VERSION "dbc-export 1 2025.20.8"

NS_ :

BS_:

BU_: ADSP APB APP APS APSB BB BMS CC CMP CMPD CP DAS DI DIF DIR DPB EPAS3P EPAS3S EPASTP EPASTS EPBL EPBR ESP GTW HVP IBST ICR IDB OCS1P ODIN PARK PCS PLG PM PMF PMR PTC RADC RCM RCM2 RCU SCCM SDCR TAS TCU TPMS TRCM UDS UI UIS UMC USM VC VCFRONT VCLEFT VCRIGHT VCSEC

BO_ 938 HVP_alertMatrix: 8 HVP
 SG_ HVP_matrixIndex M : 0|4@1+ (1,0) [0|15] "" Vector__XXX
 SG_ HVP_w001_WatchdogReset m0 : 4|1@1+ (1,0) [0|1] "" Vector__XXX
 SG_ HVP_w002_UnusedAlert2 m0 : 5|1@1+ (1,0) [0|1] "" Vector__XXX
 SG_ HVP_w003_SwAssertion m0 : 6|1@1+ (1,0) [0|1] "" Vector__XXX
 SG_ HVP_w004_CrashEvent m0 : 7|1@1+ (1,0) [0|1] "" Vector__XXX
 SG_ HVP_w005_OverDchgCurrentFault m0 : 8|1@1+ (1,0) [0|1] "" Vector__XXX
 SG_ HVP_w006_OverChargeCurrentFault m0 : 9|1@1+ (1,0) [0|1] "" Vector__XXX
 SG_ HVP_w007_OverCurrentFault m0 : 10|1@1+ (1,0) [0|1] "" Vector__XXX
 SG_ HVP_w008_OverTemperatureFault m0 : 11|1@1+ (1,0) [0|1] "" Vector__XXX
 SG_ HVP_w009_OverVoltageFault m0 : 12|1@1+ (1,0) [0|1] "" Vector__XXX
 SG_ HVP_w010_UnderVoltageFault m0 : 13|1@1+ (1,0) [0|1] "" Vector__XXX
 SG_ HVP_w011_PrimaryBmbMiaFault m0 : 14|1@1+ (1,0) [0|1] "" Vector__XXX
 SG_ HVP_w012_BmbDataIntegrityLoss m0 : 15|1@1+ (1,0) [0|1] "" Vector__XXX
 SG_ HVP_w013_BmbCommunication m0 : 16|1@1+ (1,0) [0|1] "" Vector__XXX
 SG_ HVP_w014_BmsMiaOnHviFault m0 : 17|1@1+ (1,0) [0|1] "" Vector__XXX
 SG_ HVP_w015_CpMiaFault m0 : 18|1@1+ (1,0) [0|1] "" Vector__XXX
 SG_ HVP_w016_PcsMiaFault m0 : 19|1@1+ (1,0) [0|1] "" Vector__XXX
 SG_ HVP_w017_GtwMiaFault m0 : 20|1@1+ (1,0) [0|1] "" Vector__XXX
 SG_ HVP_w018_powerCyclingPcs m0 : 21|1@1+ (1,0) [0|1] "" Vector__XXX
 SG_ HVP_w019_CpFault m0 : 22|1@1+ (1,0) [0|1] "" Vector__XXX
 SG_ HVP_w020_ShuntHwMiaFault m0 : 23|1@1+ (1,0) [0|1] "" Vector__XXX
 SG_ HVP_w021_PyroMiaFault m0 : 24|1@1+ (1,0) [0|1] "" Vector__XXX
 SG_ HVP_w022_PyroMiaWarning m0 : 25|1@1+ (1,0) [0|1] "" Vector__XXX
 SG_ HVP_w023_BmbResetRecovery m0 : 26|1@1+ (1,0) [0|1] "" Vector__XXX
 SG_ HVP_w024_Supply12vFault m0 : 27|1@1+ (1,0) [0|1] "" Vector__XXX
 SG_ HVP_w025_VerSupplyFault m0 : 28|1@1+ (1,0) [0|1] "" Vector__XXX
 SG_ HVP_w026_HvilFault m0 : 29|1@1+ (1,0) [0|1] "" Vector__XXX
 SG_ HVP_w027_BmsMiaOnHvsFault m0 : 30|1@1+ (1,0) [0|1] "" Vector__XXX
 SG_ HVP_w028_PackVoltMismatchFault m0 : 31|1@1+ (1,0) [0|1] "" Vector__XXX
 SG_ HVP_w029_EnsMiaFault m0 : 32|1@1+ (1,0) [0|1] "" Vector__XXX
 SG_ HVP_w030_PackPosCtrArcFault m0 : 33|1@1+ (1,0) [0|1] "" Vector__XXX
 SG_ HVP_w031_packNegCtrArcFault m0 : 34|1@1+ (1,0) [0|1] "" Vector__XXX
 SG_ HVP_w032_ShuntHwAndBmsMiaFault m0 : 35|1@1+ (1,0) [0|1] "" Vector__XXX
 SG_ HVP_w033_fcContHwFault m0 : 36|1@1+ (1,0) [0|1] "" Vector__XXX
 SG_ HVP_w034_cpMismatchFault m0 : 37|1@1+ (1,0) [0|1] "" Vector__XXX
 SG_ HVP_w035_packContHwFault m0 : 38|1@1+ (1,0) [0|1] "" Vector__XXX
 SG_ HVP_w036_pyroFuseBlown m0 : 39|1@1+ (1,0) [0|1] "" Vector__XXX
 SG_ HVP_w037_pyroFuseFailedToBlow m0 : 40|1@1+ (1,0) [0|1] "" Vector__XXX
 SG_ HVP_w038_CpilFault m0 : 41|1@1+ (1,0) [0|1] "" Vector__XXX
 SG_ HVP_w039_PackContactorFellOpen m0 : 42|1@1+ (1,0) [0|1] "" Vector__XXX
 SG_ HVP_w040_FcContactorFellOpen m0 : 43|1@1+ (1,0) [0|1] "" Vector__XXX
 SG_ HVP_w041_packCtrCloseBlocked m0 : 44|1@1+ (1,0) [0|1] "" Vector__XXX
 SG_ HVP_w042_fcCtrCloseBlocked m0 : 45|1@1+ (1,0) [0|1] "" Vector__XXX
 SG_ HVP_w043_packContactorForceOpen m0 : 46|1@1+ (1,0) [0|1] "" Vector__XXX
 SG_ HVP_w044_fcContactorForceOpen m0 : 47|1@1+ (1,0) [0|1] "" Vector__XXX
 SG_ HVP_w045_dcLinkOverVoltage m0 : 48|1@1+ (1,0) [0|1] "" Vector__XXX
 SG_ HVP_w046_shuntOverTemperature m0 : 49|1@1+ (1,0) [0|1] "" Vector__XXX
 SG_ HVP_w047_passivePyroDeploy m0 : 50|1@1+ (1,0) [0|1] "" Vector__XXX
 SG_ HVP_w048_swUnsupportedBmbAsicTyp m0 : 51|1@1+ (1,0) [0|1] "" Vector__XXX
 SG_ HVP_w049_packCtrCloseFailed m0 : 52|1@1+ (1,0) [0|1] "" Vector__XXX
 SG_ HVP_w050_fcCtrCloseFailed m0 : 53|1@1+ (1,0) [0|1] "" Vector__XXX
 SG_ HVP_w051_shuntThermistorMia m0 : 54|1@1+ (1,0) [0|1] "" Vector__XXX
 SG_ HVP_w052_BmbStatusRegError m0 : 55|1@1+ (1,0) [0|1] "" Vector__XXX
 SG_ HVP_w053_hvVoltageSensorRational m0 : 56|1@1+ (1,0) [0|1] "" Vector__XXX
 SG_ HVP_w054_swMissingConfigBlock m0 : 57|1@1+ (1,0) [0|1] "" Vector__XXX
 SG_ HVP_w055_swMissingPartNumber m0 : 58|1@1+ (1,0) [0|1] "" Vector__XXX
 SG_ HVP_w056_contactorFailedToOpen m0 : 59|1@1+ (1,0) [0|1] "" Vector__XXX
 SG_ HVP_w057_BatmanDiagnosticsError m0 : 60|1@1+ (1,0) [0|1] "" Vector__XXX
 SG_ HVP_w058_BmbVrefBad m0 : 61|1@1+ (1,0) [0|1] "" Vector__XXX
 SG_ HVP_w059_BmbVrefWarning m0 : 62|1@1+ (1,0) [0|1] "" Vector__XXX
 SG_ HVP_w060_StackVoltageSense m0 : 63|1@1+ (1,0) [0|1] "" Vector__XXX
 SG_ HVP_w061_ShuntCurrentRationality m1 : 4|1@1+ (1,0) [0|1] "" Vector__XXX
 SG_ HVP_w062_BmbOtpConfigError m1 : 5|1@1+ (1,0) [0|1] "" Vector__XXX
 SG_ HVP_w063_BmbBrickVRationality m1 : 6|1@1+ (1,0) [0|1] "" Vector__XXX
 SG_ HVP_w064_BmbAuxVRationality m1 : 7|1@1+ (1,0) [0|1] "" Vector__XXX
 SG_ HVP_w065_FastOpenVshDetected m1 : 8|1@1+ (1,0) [0|1] "" Vector__XXX
 SG_ HVP_w067_HvilCalNodeMismatch m1 : 10|1@1+ (1,0) [0|1] "" Vector__XXX
 SG_ HVP_w068_shuntUnexpectedThermist m1 : 11|1@1+ (1,0) [0|1] "" Vector__XXX

BO_ 522 HVP_contactorState: 6 HVP
 SG_ HVP_packContNegativeState : 0|3@1+ (1,0) [1|7] "" Vector__XXX
 SG_ HVP_packContPositiveState : 3|3@1+ (1,0) [1|7] "" Vector__XXX
 SG_ HVP_fcContPositiveAuxOpen : 6|1@1+ (1,0) [0|1] "" Vector__XXX
 SG_ HVP_fcContNegativeAuxOpen : 7|1@1+ (1,0) [0|1] "" Vector__XXX
 SG_ HVP_packContactorSetState : 8|4@1+ (1,0) [1|15] "" Vector__XXX
 SG_ HVP_fcContNegativeState : 12|3@1+ (1,0) [1|7] "" Vector__XXX
 SG_ HVP_fcContPositiveState : 16|3@1+ (1,0) [1|7] "" Vector__XXX
 SG_ HVP_fcContactorSetState : 19|4@1+ (1,0) [1|15] "" Vector__XXX
 SG_ HVP_fcCtrsRequestStatus : 24|2@1+ (1,0) [0|3] "" Vector__XXX
 SG_ HVP_fcCtrsResetRequestRequired : 26|1@1+ (1,0) [0|1] "" Vector__XXX
 SG_ HVP_fcCtrsOpenNowRequested : 27|1@1+ (1,0) [0|1] "" Vector__XXX
 SG_ HVP_fcCtrsOpenRequested : 28|1@1+ (1,0) [0|1] "" Vector__XXX
 SG_ HVP_fcCtrsClosingAllowed : 29|1@1+ (1,0) [0|1] "" Vector__XXX
 SG_ HVP_packCtrsRequestStatus : 30|2@1+ (1,0) [0|3] "" Vector__XXX
 SG_ HVP_packCtrsResetRequestRequired : 32|1@1+ (1,0) [0|1] "" Vector__XXX
 SG_ HVP_packCtrsOpenNowRequested : 33|1@1+ (1,0) [0|1] "" Vector__XXX
 SG_ HVP_packCtrsOpenRequested : 34|1@1+ (1,0) [0|1] "" Vector__XXX
 SG_ HVP_packCtrsClosingAllowed : 35|1@1+ (1,0) [0|1] "" Vector__XXX
 SG_ HVP_dcLinkAllowedToEnergize : 36|1@1+ (1,0) [0|1] "" Vector__XXX
 SG_ HVP_pyroTestInProgress : 37|1@1+ (1,0) [0|1] "" Vector__XXX
 SG_ HVP_hvilDiag : 40|4@1+ (1,0) [0|15] "" Vector__XXX
 SG_ HVP_fcLinkAllowedToEnergize : 44|2@1+ (1,0) [0|3] "" Vector__XXX

BO_ 1962 HVP_debugMessage: 8 HVP
 SG_ HVP_debugMessageMultiplexer M : 0|4@1+ (1,0) [0|15] "" Vector__XXX
 SG_ HVP_gpioPassivePyroDepl m0 : 4|1@1+ (1,0) [0|1] "" Vector__XXX
 SG_ HVP_gpioPyroIsoEn m0 : 5|1@1+ (1,0) [0|1] "" Vector__XXX
 SG_ HVP_gpioCpFaultIn m0 : 6|1@1+ (1,0) [0|1] "" Vector__XXX
 SG_ HVP_gpioPackContPowerEn m0 : 7|1@1+ (1,0) [0|1] "" Vector__XXX
 SG_ HVP_gpioHvCablesOk m0 : 8|1@1+ (1,0) [0|1] "" Vector__XXX
 SG_ HVP_gpioHvpSelfEnable m0 : 9|1@1+ (1,0) [0|1] "" Vector__XXX
 SG_ HVP_gpioLed m0 : 10|1@1+ (1,0) [0|1] "" Vector__XXX
 SG_ HVP_gpioCrashSignal m0 : 11|1@1+ (1,0) [0|1] "" Vector__XXX
 SG_ HVP_gpioShuntDataReady m0 : 12|1@1+ (1,0) [0|1] "" Vector__XXX
 SG_ HVP_gpioFcContPosAux m0 : 13|1@1+ (1,0) [0|1] "" Vector__XXX
 SG_ HVP_gpioFcContNegAux m0 : 14|1@1+ (1,0) [0|1] "" Vector__XXX
 SG_ HVP_gpioBmsEout m0 : 15|1@1+ (1,0) [0|1] "" Vector__XXX
 SG_ HVP_gpioCpFaultOut m0 : 16|1@1+ (1,0) [0|1] "" Vector__XXX
 SG_ HVP_gpioPyroPor m0 : 17|1@1+ (1,0) [0|1] "" Vector__XXX
 SG_ HVP_gpioShuntEn m0 : 18|1@1+ (1,0) [0|1] "" Vector__XXX
 SG_ HVP_gpioHvpVerEn m0 : 19|1@1+ (1,0) [0|1] "" Vector__XXX
 SG_ HVP_gpioFcContFlywheelEnable m0 : 20|1@1+ (1,0) [0|1] "" Vector__XXX
 SG_ HVP_gpioCpLatchEnable m0 : 21|1@1+ (1,0) [0|1] "" Vector__XXX
 SG_ HVP_gpioFcContPowerEnable m0 : 22|1@1+ (1,0) [0|1] "" Vector__XXX
 SG_ HVP_gpioHvilEnable m0 : 23|1@1+ (1,0) [0|1] "" Vector__XXX
 SG_ HVP_gpioPortSelSpiRdy m0 : 24|1@1+ (1,0) [0|1] "" Vector__XXX
 SG_ HVP_gpioPyroUnlock m0 : 25|1@1+ (1,0) [0|1] "" Vector__XXX
 SG_ HVP_hvp1v5Ref m0 : 26|12@1+ (0.1,0) [0|3] "V" Vector__XXX
 SG_ HVP_packCurrentMia m0 : 38|1@1+ (1,0) [0|1] "" Vector__XXX
 SG_ HVP_auxCurrentMia m0 : 39|1@1+ (1,0) [0|1] "" Vector__XXX
 SG_ HVP_currentSenseMia m0 : 40|1@1+ (1,0) [0|1] "" Vector__XXX
 SG_ HVP_shuntRefVoltageMismatch m0 : 41|1@1+ (1,0) [0|1] "" Vector__XXX
 SG_ HVP_shuntThermistorMissing m0 : 42|1@1+ (1,0) [0|1] "" Vector__XXX
 SG_ HVP_shuntThermistorExpected m0 : 43|1@1+ (1,0) [0|1] "" Vector__XXX
 SG_ HVP_shuntThermistorMia m0 : 44|1@1+ (1,0) [0|1] "" Vector__XXX
 SG_ HVP_shuntUnexpectedThermistor m0 : 45|1@1+ (1,0) [0|1] "" Vector__XXX
 SG_ HVP_shuntHwMia m0 : 46|1@1+ (1,0) [0|1] "" Vector__XXX
 SG_ HVP_shuntCurrentIrrational m0 : 47|1@1+ (1,0) [0|1] "" Vector__XXX
 SG_ HVP_shuntAsicTCompActive m0 : 48|1@1+ (1,0) [0|1] "" Vector__XXX
 SG_ HVP_ecuLogUploadRequest m0 : 49|2@1+ (1,0) [0|3] "" Vector__XXX
 SG_ HVP_packContVoltage m2 : 4|12@1+ (0.1,0) [0|30] "V" Vector__XXX
 SG_ HVP_packNegativeV m2 : 16|16@1- (0.1,0) [-550|550] "V" Vector__XXX
 SG_ HVP_packPositiveV m2 : 32|16@1- (0.1,0) [-550|550] "V" Vector__XXX
 SG_ HVP_pyroAnalog m2 : 48|12@1+ (0.1,0) [0|3] "V" Vector__XXX
 SG_ HVP_fcContCoilCurrent m4 : 4|12@1+ (0.1,0) [0|7.5] "A" Vector__XXX
 SG_ HVP_fcContVoltage m4 : 16|12@1+ (0.1,0) [0|30] "V" Vector__XXX
 SG_ HVP_hvilInVoltage m4 : 28|12@1+ (0.1,0) [0|30] "V" Vector__XXX
 SG_ HVP_hvilOutVoltage m4 : 40|12@1+ (0.1,0) [0|30] "V" Vector__XXX
 SG_ HVP_shuntGainInvalidCountDbg m4 : 56|8@1+ (1,0) [0|255] "counts" Vector__XXX
 SG_ HVP_fcLinkPositiveV m5 : 8|16@1- (0.1,0) [-550|550] "V" Vector__XXX
 SG_ HVP_packContCoilCurrent m5 : 24|12@1+ (0.1,0) [0|7.5] "A" Vector__XXX
 SG_ HVP_battery12V m5 : 36|12@1+ (0.1,0) [0|30] "V" Vector__XXX
 SG_ HVP_shuntRefVoltageDbg m5 : 48|16@1- (0.001,0) [-32.768|32.767] "V" Vector__XXX

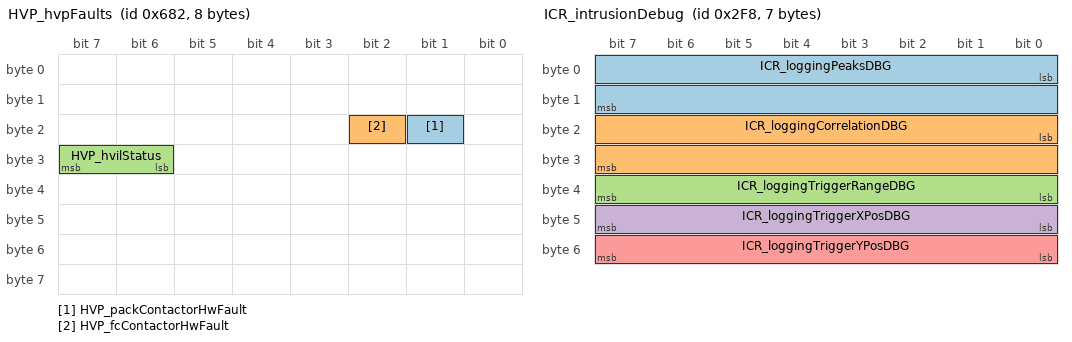
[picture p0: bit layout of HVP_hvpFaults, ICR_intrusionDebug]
BO_ 1666 HVP_hvpFaults: 8 HVP
 SG_ HVP_packContactorHwFault : 17|1@1+ (1,0) [0|1] "" Vector__XXX
 SG_ HVP_fcContactorHwFault : 18|1@1+ (1,0) [0|1] "" Vector__XXX
 SG_ HVP_hvilStatus : 30|2@1+ (1,0) [0|2] "" Vector__XXX

BO_ 1553 HVP_udsResponse: 8 HVP
 SG_ HVP_udsResponseData : 7|64@0+ (1,0) [0|1.84467440737e+19] "" Vector__XXX

BO_ 861 IBST_alertMatrix: 8 IBST
 SG_ IBST_matrixIndex M : 0|4@1+ (1,0) [0|15] "" Vector__XXX
 SG_ IBST_a001_microSupplyError m0 : 4|1@1+ (1,0) [0|1] "" Vector__XXX
 SG_ IBST_a002_HWBISTError m0 : 5|1@1+ (1,0) [0|1] "" Vector__XXX
 SG_ IBST_a003_RAMFault m0 : 6|1@1+ (1,0) [0|1] "" Vector__XXX
 SG_ IBST_a004_flashFault m0 : 7|1@1+ (1,0) [0|1] "" Vector__XXX
 SG_ IBST_a005_microSafetyFault m0 : 8|1@1+ (1,0) [0|1] "" Vector__XXX
 SG_ IBST_a006_microSafetyLogicFault m0 : 9|1@1+ (1,0) [0|1] "" Vector__XXX
 SG_ IBST_a007_RBCPUException m0 : 10|1@1+ (1,0) [0|1] "" Vector__XXX
 SG_ IBST_a008_stackOverUnderFlow m0 : 11|1@1+ (1,0) [0|1] "" Vector__XXX
 SG_ IBST_a009_systemErrorHook m0 : 12|1@1+ (1,0) [0|1] "" Vector__XXX
 SG_ IBST_a010_OSErrorHook m0 : 13|1@1+ (1,0) [0|1] "" Vector__XXX
 SG_ IBST_a011_systemTaskOverRun m0 : 14|1@1+ (1,0) [0|1] "" Vector__XXX
 SG_ IBST_a012_OSTaskSchemeError m0 : 15|1@1+ (1,0) [0|1] "" Vector__XXX
 SG_ IBST_a013_systemTaskJitter m0 : 16|1@1+ (1,0) [0|1] "" Vector__XXX
 SG_ IBST_a014_DMATransferError m0 : 17|1@1+ (1,0) [0|1] "" Vector__XXX
 SG_ IBST_a015_asicOscillatorError m0 : 18|1@1+ (1,0) [0|1] "" Vector__XXX
 SG_ IBST_a016_RBBLMShaftShiftError m0 : 19|1@1+ (1,0) [0|1] "" Vector__XXX
 SG_ IBST_a017_assertionFault m0 : 20|1@1+ (1,0) [0|1] "" Vector__XXX
 SG_ IBST_a018_unsupportedHW m0 : 21|1@1+ (1,0) [0|1] "" Vector__XXX
 SG_ IBST_a019_supplyASICInitFault m0 : 22|1@1+ (1,0) [0|1] "" Vector__XXX
 SG_ IBST_a020_VPREU5VOutOfRange m0 : 23|1@1+ (1,0) [0|1] "" Vector__XXX
 SG_ IBST_a021_IREFOutOfRange m0 : 24|1@1+ (1,0) [0|1] "" Vector__XXX
 SG_ IBST_a022_U5VTestFault m0 : 25|1@1+ (1,0) [0|1] "" Vector__XXX
 SG_ IBST_a023_U5VOutOfRange m0 : 26|1@1+ (1,0) [0|1] "" Vector__XXX
 SG_ IBST_a024_chargePumpFault m0 : 27|1@1+ (1,0) [0|1] "" Vector__XXX
 SG_ IBST_a025_ecuClockTestFault m0 : 28|1@1+ (1,0) [0|1] "" Vector__XXX
 SG_ IBST_a026_ecuBistCmdTestFault m0 : 29|1@1+ (1,0) [0|1] "" Vector__XXX
 SG_ IBST_a027_ecuFastWdTestFault m0 : 30|1@1+ (1,0) [0|1] "" Vector__XXX
 SG_ IBST_a028_ecuBistFaultCtrFault m0 : 31|1@1+ (1,0) [0|1] "" Vector__XXX
 SG_ IBST_a029_ecuErrpinCounterFault m0 : 32|1@1+ (1,0) [0|1] "" Vector__XXX
 SG_ IBST_a030_ecuEnableElLowFault m0 : 33|1@1+ (1,0) [0|1] "" Vector__XXX
 SG_ IBST_a031_decoupleBitTestFault m0 : 34|1@1+ (1,0) [0|1] "" Vector__XXX
 SG_ IBST_a032_ecuEnableElHighFault m0 : 35|1@1+ (1,0) [0|1] "" Vector__XXX
 SG_ IBST_a033_ecuWdStartuptestFault m0 : 36|1@1+ (1,0) [0|1] "" Vector__XXX
 SG_ IBST_a034_ecuEnableHyHighFault m0 : 37|1@1+ (1,0) [0|1] "" Vector__XXX
 SG_ IBST_a035_ecuEnableHyLowFault m0 : 38|1@1+ (1,0) [0|1] "" Vector__XXX
 SG_ IBST_a036_MRGPathTestFault m0 : 39|1@1+ (1,0) [0|1] "" Vector__XXX
 SG_ IBST_a037_ecuWdSContinuousError m0 : 40|1@1+ (1,0) [0|1] "" Vector__XXX
 SG_ IBST_a038_ecuEnContinuousError m0 : 41|1@1+ (1,0) [0|1] "" Vector__XXX
 SG_ IBST_a039_GTMRefFrequencyError m0 : 42|1@1+ (1,0) [0|1] "" Vector__XXX
 SG_ IBST_a040_GTMTbuMonError m0 : 43|1@1+ (1,0) [0|1] "" Vector__XXX
 SG_ IBST_a041_micAsicClkInError m0 : 44|1@1+ (1,0) [0|1] "" Vector__XXX
 SG_ IBST_a042_micAsicInitTestError m0 : 45|1@1+ (1,0) [0|1] "" Vector__XXX
 SG_ IBST_a043_micSpiTransferError m0 : 46|1@1+ (1,0) [0|1] "" Vector__XXX
 SG_ IBST_a044_NvMEepromWIP m0 : 47|1@1+ (1,0) [0|1] "" Vector__XXX
 SG_ IBST_a045_WdhAsicWdErrorCntStuck m0 : 48|1@1+ (1,0) [0|1] "" Vector__XXX
 SG_ IBST_a046_WdhAsicWdErrorCntLimit m0 : 49|1@1+ (1,0) [0|1] "" Vector__XXX
 SG_ IBST_a047_WdhAsicWdCmdMissing m0 : 50|1@1+ (1,0) [0|1] "" Vector__XXX
 SG_ IBST_a048_WdhSwBistConCnt m0 : 51|1@1+ (1,0) [0|1] "" Vector__XXX
 SG_ IBST_a049_WdhTaskMonConCnt m0 : 52|1@1+ (1,0) [0|1] "" Vector__XXX
 SG_ IBST_a050_VPreExternalFeeding m0 : 53|1@1+ (1,0) [0|1] "" Vector__XXX
 SG_ IBST_a051_ecuBandgap m0 : 54|1@1+ (1,0) [0|1] "" Vector__XXX
 SG_ IBST_a052_AdcPinTest m0 : 55|1@1+ (1,0) [0|1] "" Vector__XXX
 SG_ IBST_a053_AdcSelftestC5P m0 : 56|1@1+ (1,0) [0|1] "" Vector__XXX
 SG_ IBST_a054_AdcPeripheralFault m0 : 57|1@1+ (1,0) [0|1] "" Vector__XXX
 SG_ IBST_a055_UB6SupplyPathFault m0 : 58|1@1+ (1,0) [0|1] "" Vector__XXX
 SG_ IBST_a056_UB6PlausiMonFault m0 : 59|1@1+ (1,0) [0|1] "" Vector__XXX
 SG_ IBST_a057_microRegisterFault m0 : 60|1@1+ (1,0) [0|1] "" Vector__XXX
 SG_ IBST_a058_NvMWriteCycleExceed m0 : 61|1@1+ (1,0) [0|1] "" Vector__XXX
 SG_ IBST_a059_NvMEepromSize m0 : 62|1@1+ (1,0) [0|1] "" Vector__XXX
 SG_ IBST_a060_NvMMigrationFault m0 : 63|1@1+ (1,0) [0|1] "" Vector__XXX
 SG_ IBST_a061_AswSystemTimeOut m1 : 4|1@1+ (1,0) [0|1] "" Vector__XXX
 SG_ IBST_a062_MICB6TransferError m1 : 5|1@1+ (1,0) [0|1] "" Vector__XXX
 SG_ IBST_a063_tempSens2ShortToSupply m1 : 6|1@1+ (1,0) [0|1] "" Vector__XXX
 SG_ IBST_a064_tempSens1ShortToGround m1 : 7|1@1+ (1,0) [0|1] "" Vector__XXX
 SG_ IBST_a065_tempSens2ShortToGround m1 : 8|1@1+ (1,0) [0|1] "" Vector__XXX
 SG_ IBST_a066_tempSens1ShortToSupply m1 : 9|1@1+ (1,0) [0|1] "" Vector__XXX
 SG_ IBST_a067_tempSensImplausVoltage m1 : 10|1@1+ (1,0) [0|1] "" Vector__XXX
 SG_ IBST_a068_chargePumpUndervoltage m1 : 11|1@1+ (1,0) [0|1] "" Vector__XXX
 SG_ IBST_a069_greasingRoutineFault m1 : 12|1@1+ (1,0) [0|1] "" Vector__XXX
 SG_ IBST_a070_notShutDownNvMWrite m1 : 13|1@1+ (1,0) [0|1] "" Vector__XXX
 SG_ IBST_a071_notShutDownNvMRead m1 : 14|1@1+ (1,0) [0|1] "" Vector__XXX
 SG_ IBST_a072_notShutDownRight m1 : 15|1@1+ (1,0) [0|1] "" Vector__XXX
 SG_ IBST_a073_jumpInAdjustNvMRead m1 : 16|1@1+ (1,0) [0|1] "" Vector__XXX
 SG_ IBST_a074_FindIdleDataNvMWrite m1 : 17|1@1+ (1,0) [0|1] "" Vector__XXX
 SG_ IBST_a075_FindIdleRoutineFault m1 : 18|1@1+ (1,0) [0|1] "" Vector__XXX
 SG_ IBST_a076_masterCylLengthRead m1 : 19|1@1+ (1,0) [0|1] "" Vector__XXX
 SG_ IBST_a077_runOutMotorSaturated m1 : 20|1@1+ (1,0) [0|1] "" Vector__XXX
 SG_ IBST_a078_wearOffsetCompNVMRead m1 : 21|1@1+ (1,0) [0|1] "" Vector__XXX
 SG_ IBST_a079_motorTempHighLevel1 m1 : 22|1@1+ (1,0) [0|1] "" Vector__XXX
 SG_ IBST_a080_motorTempHighLevel2 m1 : 23|1@1+ (1,0) [0|1] "" Vector__XXX
 SG_ IBST_a081_travelDeviation m1 : 24|1@1+ (1,0) [0|1] "" Vector__XXX
 SG_ IBST_a082_motorSpeedDeviation m1 : 25|1@1+ (1,0) [0|1] "" Vector__XXX
 SG_ IBST_a083_spindlePositionTooHigh m1 : 26|1@1+ (1,0) [0|1] "" Vector__XXX
 SG_ IBST_a084_CANTransceiverHWFault m1 : 27|1@1+ (1,0) [0|1] "" Vector__XXX
 SG_ IBST_a085_supplyUndervoltageLvl3 m1 : 28|1@1+ (1,0) [0|1] "" Vector__XXX
 SG_ IBST_a086_supplyOvervoltageLvl3 m1 : 29|1@1+ (1,0) [0|1] "" Vector__XXX
 SG_ IBST_a087_rotorSinOutOfRangeLow m1 : 30|1@1+ (1,0) [0|1] "" Vector__XXX
 SG_ IBST_a088_rotorCosOutOfRangeLow m1 : 31|1@1+ (1,0) [0|1] "" Vector__XXX
 SG_ IBST_a089_rotorSinOutOfRangeHigh m1 : 32|1@1+ (1,0) [0|1] "" Vector__XXX
 SG_ IBST_a090_rotorCosOutOfRangeHigh m1 : 33|1@1+ (1,0) [0|1] "" Vector__XXX
 SG_ IBST_a091_SMMOneRequestsInit m1 : 34|1@1+ (1,0) [0|1] "" Vector__XXX
 SG_ IBST_a092_systemStartTimeOut m1 : 35|1@1+ (1,0) [0|1] "" Vector__XXX
 SG_ IBST_a093_UEXSOvertemperature m1 : 36|1@1+ (1,0) [0|1] "" Vector__XXX
 SG_ IBST_a094_XPASSEchoTimeDeviation m1 : 37|1@1+ (1,0) [0|1] "" Vector__XXX
 SG_ IBST_a095_XPASSTimeOut m1 : 38|1@1+ (1,0) [0|1] "" Vector__XXX
 SG_ IBST_a096_bridgeDriverMonError m1 : 39|1@1+ (1,0) [0|1] "" Vector__XXX
 SG_ IBST_a097_bridgeDriverError m1 : 40|1@1+ (1,0) [0|1] "" Vector__XXX
 SG_ IBST_a098_bridgeShortedPhase m1 : 41|1@1+ (1,0) [0|1] "" Vector__XXX
 SG_ IBST_a099_bridgeSwitchInitError m1 : 42|1@1+ (1,0) [0|1] "" Vector__XXX
 SG_ IBST_a100_current2OffsetHigh m1 : 43|1@1+ (1,0) [0|1] "" Vector__XXX
 SG_ IBST_a101_current2OffsetLow m1 : 44|1@1+ (1,0) [0|1] "" Vector__XXX
 SG_ IBST_a102_current1OffsetHigh m1 : 45|1@1+ (1,0) [0|1] "" Vector__XXX
 SG_ IBST_a103_current1OffsetLow m1 : 46|1@1+ (1,0) [0|1] "" Vector__XXX
 SG_ IBST_a104_bridgeDriverShort m1 : 47|1@1+ (1,0) [0|1] "" Vector__XXX
 SG_ IBST_a105_LiPSUndervoltage m1 : 48|1@1+ (1,0) [0|1] "" Vector__XXX
 SG_ IBST_a106_LiPS5VSupply m1 : 49|1@1+ (1,0) [0|1] "" Vector__XXX
 SG_ IBST_a107_LiPS2PwmLineHigh m1 : 50|1@1+ (1,0) [0|1] "" Vector__XXX
 SG_ IBST_a108_LiPS2PwmLineLow m1 : 51|1@1+ (1,0) [0|1] "" Vector__XXX
 SG_ IBST_a109_LiPS2PwmTransmission m1 : 52|1@1+ (1,0) [0|1] "" Vector__XXX
 SG_ IBST_a110_LiPS1SentLineHigh m1 : 53|1@1+ (1,0) [0|1] "" Vector__XXX
 SG_ IBST_a111_LiPS1SentLineLow m1 : 54|1@1+ (1,0) [0|1] "" Vector__XXX
 SG_ IBST_a112_LiPS1SentTransmission m1 : 55|1@1+ (1,0) [0|1] "" Vector__XXX
 SG_ IBST_a113_LiPS1SentSensor m1 : 56|1@1+ (1,0) [0|1] "" Vector__XXX
 SG_ IBST_a114_partyBusOff m1 : 57|1@1+ (1,0) [0|1] "" Vector__XXX
 SG_ IBST_a115_chassisBusOff m1 : 58|1@1+ (1,0) [0|1] "" Vector__XXX
 SG_ IBST_a116_supplyUndervoltageLvl2 m1 : 59|1@1+ (1,0) [0|1] "" Vector__XXX
 SG_ IBST_a117_supplyOvervoltageLvl2 m1 : 60|1@1+ (1,0) [0|1] "" Vector__XXX
 SG_ IBST_a118_RPSNvMReadFault m1 : 61|1@1+ (1,0) [0|1] "" Vector__XXX
 SG_ IBST_a119_RPSWrongCalibData m1 : 62|1@1+ (1,0) [0|1] "" Vector__XXX
 SG_ IBST_a120_RPSVectorRangeHigh m1 : 63|1@1+ (1,0) [0|1] "" Vector__XXX
 SG_ IBST_a121_RPSVectorRangeLow m2 : 4|1@1+ (1,0) [0|1] "" Vector__XXX
 SG_ IBST_a122_RPSVectorOscillating m2 : 5|1@1+ (1,0) [0|1] "" Vector__XXX
 SG_ IBST_a123_bridgeDriverUnavail m2 : 6|1@1+ (1,0) [0|1] "" Vector__XXX
 SG_ IBST_a124_OBDCurrent1OORHigh m2 : 7|1@1+ (1,0) [0|1] "" Vector__XXX
 SG_ IBST_a125_OBDCurrent2OORHigh m2 : 8|1@1+ (1,0) [0|1] "" Vector__XXX
 SG_ IBST_a126_OBDCurrent1OORLow m2 : 9|1@1+ (1,0) [0|1] "" Vector__XXX
 SG_ IBST_a127_OBDCurrent2OORLow m2 : 10|1@1+ (1,0) [0|1] "" Vector__XXX
 SG_ IBST_a128_BLMMuxerTimeoutError m2 : 11|1@1+ (1,0) [0|1] "" Vector__XXX
 SG_ IBST_a129_loadDumpOnFSLTest m2 : 12|1@1+ (1,0) [0|1] "" Vector__XXX
 SG_ IBST_a130_DTSFunctionalRangeLow m2 : 13|1@1+ (1,0) [0|1] "" Vector__XXX
 SG_ IBST_a131_DTSFunctionalRangeHigh m2 : 14|1@1+ (1,0) [0|1] "" Vector__XXX
 SG_ IBST_a132_DTSPlausiCheck1vs2 m2 : 15|1@1+ (1,0) [0|1] "" Vector__XXX
 SG_ IBST_a133_DTSOffsetTooLow m2 : 16|1@1+ (1,0) [0|1] "" Vector__XXX
 SG_ IBST_a134_DTSOffsetTooHigh m2 : 17|1@1+ (1,0) [0|1] "" Vector__XXX
 SG_ IBST_a135_ESPparty1DLC m2 : 18|1@1+ (1,0) [0|1] "" Vector__XXX
 SG_ IBST_a136_ESPparty1Timeout m2 : 19|1@1+ (1,0) [0|1] "" Vector__XXX
 SG_ IBST_a137_ESPparty1Checksum m2 : 20|1@1+ (1,0) [0|1] "" Vector__XXX
 SG_ IBST_a138_ESPparty1Counter m2 : 21|1@1+ (1,0) [0|1] "" Vector__XXX
 SG_ IBST_a139_ESPparty2DLC m2 : 22|1@1+ (1,0) [0|1] "" Vector__XXX
 SG_ IBST_a140_ESPparty2Timeout m2 : 23|1@1+ (1,0) [0|1] "" Vector__XXX
 SG_ IBST_a141_ESPparty2Checksum m2 : 24|1@1+ (1,0) [0|1] "" Vector__XXX
 SG_ IBST_a142_ESPparty2Counter m2 : 25|1@1+ (1,0) [0|1] "" Vector__XXX
 SG_ IBST_a143_ESPparty3DLC m2 : 26|1@1+ (1,0) [0|1] "" Vector__XXX
 SG_ IBST_a144_ESPparty3Timeout m2 : 27|1@1+ (1,0) [0|1] "" Vector__XXX
 SG_ IBST_a145_ESPparty3Checksum m2 : 28|1@1+ (1,0) [0|1] "" Vector__XXX
 SG_ IBST_a146_ESPparty3Counter m2 : 29|1@1+ (1,0) [0|1] "" Vector__XXX
 SG_ IBST_a147_PSCMotorSizeReadFault m2 : 30|1@1+ (1,0) [0|1] "" Vector__XXX
 SG_ IBST_a148_MLIGainMechReadFault m2 : 31|1@1+ (1,0) [0|1] "" Vector__XXX
 SG_ IBST_a149_MLITMCAreaReadFault m2 : 32|1@1+ (1,0) [0|1] "" Vector__XXX
 SG_ IBST_a150_motorTestFault m2 : 33|1@1+ (1,0) [0|1] "" Vector__XXX
 SG_ IBST_a151_PSCGearRatioReadFault m2 : 34|1@1+ (1,0) [0|1] "" Vector__XXX
 SG_ IBST_a152_PSCVoltageImplausible m2 : 35|1@1+ (1,0) [0|1] "" Vector__XXX
 SG_ IBST_a153_unused m2 : 36|1@1+ (1,0) [0|1] "" Vector__XXX
 SG_ IBST_a154_unused m2 : 37|1@1+ (1,0) [0|1] "" Vector__XXX
 SG_ IBST_a155_supplyUndervoltageLvl1 m2 : 38|1@1+ (1,0) [0|1] "" Vector__XXX
 SG_ IBST_a156_supplyOvervoltageLvl1 m2 : 39|1@1+ (1,0) [0|1] "" Vector__XXX
 SG_ IBST_a157_masterCylPressInvalid m2 : 40|1@1+ (1,0) [0|1] "" Vector__XXX
 SG_ IBST_a158_DTSOffsHighSuspicious m2 : 41|1@1+ (1,0) [0|1] "" Vector__XXX
 SG_ IBST_a159_FindIdleNvMReadError m2 : 42|1@1+ (1,0) [0|1] "" Vector__XXX
 SG_ IBST_a160_DTSIDTimeOut m2 : 43|1@1+ (1,0) [0|1] "" Vector__XXX
 SG_ IBST_a161_powerPackMismatch m2 : 44|1@1+ (1,0) [0|1] "" Vector__XXX
 SG_ IBST_a162_idlePosNotDetected m2 : 45|1@1+ (1,0) [0|1] "" Vector__XXX
 SG_ IBST_a163_ESPpEstMaxInvalid m2 : 46|1@1+ (1,0) [0|1] "" Vector__XXX
 SG_ IBST_a164_ESPVehicleSpeedInvalid m2 : 47|1@1+ (1,0) [0|1] "" Vector__XXX
 SG_ IBST_a165_ESPpForceBlendInvalid m2 : 48|1@1+ (1,0) [0|1] "" Vector__XXX
 SG_ IBST_a166_ESPpMcVirtualInvalid m2 : 49|1@1+ (1,0) [0|1] "" Vector__XXX
 SG_ IBST_a167_ESPqTargetExterInvalid m2 : 50|1@1+ (1,0) [0|1] "" Vector__XXX
 SG_ IBST_a168_CANOvervoltage m2 : 51|1@1+ (1,0) [0|1] "" Vector__XXX
 SG_ IBST_a169_CANUndervoltage m2 : 52|1@1+ (1,0) [0|1] "" Vector__XXX
 SG_ IBST_a170_LVPowerStateTimeout m2 : 53|1@1+ (1,0) [0|1] "" Vector__XXX
 SG_ IBST_a171_LVPowerStateChecksum m2 : 54|1@1+ (1,0) [0|1] "" Vector__XXX
 SG_ IBST_a172_LVPowerStateDLC m2 : 55|1@1+ (1,0) [0|1] "" Vector__XXX
 SG_ IBST_a173_LVPowerStateCounter m2 : 56|1@1+ (1,0) [0|1] "" Vector__XXX
 SG_ IBST_a174_LVOffStateInvalid m2 : 57|1@1+ (1,0) [0|1] "" Vector__XXX
 SG_ IBST_a175_LVGoingDownInvalid m2 : 58|1@1+ (1,0) [0|1] "" Vector__XXX
 SG_ IBST_a176_blockedPedalDetected m2 : 59|1@1+ (1,0) [0|1] "" Vector__XXX
 SG_ IBST_a177_EPBLsystemStatusMIA m2 : 60|1@1+ (1,0) [0|1] "" Vector__XXX
 SG_ IBST_a178_EPBRsystemStatusMIA m2 : 61|1@1+ (1,0) [0|1] "" Vector__XXX
 SG_ IBST_a179_VCLEFTepbmStatusMIA m2 : 62|1@1+ (1,0) [0|1] "" Vector__XXX
 SG_ IBST_a180_VCRIGHTepbmStatusMIA m2 : 63|1@1+ (1,0) [0|1] "" Vector__XXX
 SG_ IBST_a181_DIchassisControlDLC m3 : 4|1@1+ (1,0) [0|1] "" Vector__XXX
 SG_ IBST_a182_DIchassisControlTimeou m3 : 5|1@1+ (1,0) [0|1] "" Vector__XXX
 SG_ IBST_a183_DIchassisControlChecks m3 : 6|1@1+ (1,0) [0|1] "" Vector__XXX
 SG_ IBST_a184_DIchassisControlCounte m3 : 7|1@1+ (1,0) [0|1] "" Vector__XXX
 SG_ IBST_a185_rightBusOff m3 : 8|1@1+ (1,0) [0|1] "" Vector__XXX
 SG_ IBST_a186_rightBusPassive m3 : 9|1@1+ (1,0) [0|1] "" Vector__XXX
 SG_ IBST_a187_brakeBusOff m3 : 10|1@1+ (1,0) [0|1] "" Vector__XXX
 SG_ IBST_a188_brakeBusPassive m3 : 11|1@1+ (1,0) [0|1] "" Vector__XXX
 SG_ IBST_a189_rightVCLVPowerStateTim m3 : 12|1@1+ (1,0) [0|1] "" Vector__XXX
 SG_ IBST_a190_rightVCLVPowerStateDLC m3 : 13|1@1+ (1,0) [0|1] "" Vector__XXX
 SG_ IBST_a191_rightVCLVPowerStateChe m3 : 14|1@1+ (1,0) [0|1] "" Vector__XXX
 SG_ IBST_a192_rightVCLVPowerStateCou m3 : 15|1@1+ (1,0) [0|1] "" Vector__XXX
 SG_ IBST_a193_leftVCLVPowerStateTime m3 : 16|1@1+ (1,0) [0|1] "" Vector__XXX
 SG_ IBST_a194_leftVCLVPowerStateChec m3 : 17|1@1+ (1,0) [0|1] "" Vector__XXX
 SG_ IBST_a195_leftVCLVPowerStateDLC m3 : 18|1@1+ (1,0) [0|1] "" Vector__XXX
 SG_ IBST_a196_leftVCLVPowerStateCoun m3 : 19|1@1+ (1,0) [0|1] "" Vector__XXX
 SG_ IBST_a197_brakeLatencyReductionA m3 : 20|1@1+ (1,0) [0|1] "" Vector__XXX
 SG_ IBST_a198_aesActive m3 : 21|1@1+ (1,0) [0|1] "" Vector__XXX
 SG_ IBST_a199_undefinedAlertDetected m3 : 22|1@1+ (1,0) [0|1] "" Vector__XXX
 SG_ IBST_a200_aesFault m3 : 23|1@1+ (1,0) [0|1] "" Vector__XXX
 SG_ IBST_a201_EGGREAR1wheelSpeedsRea m3 : 24|1@1+ (1,0) [0|1] "" Vector__XXX
 SG_ IBST_a202_EGGREAR1wheelSpeedsRea m3 : 25|1@1+ (1,0) [0|1] "" Vector__XXX
 SG_ IBST_a203_EGGREAR1wheelSpeedsRea m3 : 26|1@1+ (1,0) [0|1] "" Vector__XXX
 SG_ IBST_a204_EGGREAR1wheelSpeedsRea m3 : 27|1@1+ (1,0) [0|1] "" Vector__XXX
 SG_ IBST_a205_EGGRIGHT1wheelSpeedsFr m3 : 28|1@1+ (1,0) [0|1] "" Vector__XXX
 SG_ IBST_a206_EGGRIGHT1wheelSpeedsFr m3 : 29|1@1+ (1,0) [0|1] "" Vector__XXX
 SG_ IBST_a207_EGGRIGHT1wheelSpeedsFr m3 : 30|1@1+ (1,0) [0|1] "" Vector__XXX
 SG_ IBST_a208_EGGRIGHT1wheelSpeedsFr m3 : 31|1@1+ (1,0) [0|1] "" Vector__XXX
 SG_ IBST_a209_reducedBrakePowerActiv m3 : 32|1@1+ (1,0) [0|1] "" Vector__XXX
 SG_ IBST_a210_reducedBrakePowerNotAv m3 : 33|1@1+ (1,0) [0|1] "" Vector__XXX
 SG_ IBST_a211_DETReportError m3 : 34|1@1+ (1,0) [0|1] "" Vector__XXX
 SG_ IBST_a212_infoFailureWrongCUBASH m3 : 35|1@1+ (1,0) [0|1] "" Vector__XXX
 SG_ IBST_a213_PDURouterinitializatio m3 : 36|1@1+ (1,0) [0|1] "" Vector__XXX
 SG_ IBST_a214_LossOfPDUInstanceDetec m3 : 37|1@1+ (1,0) [0|1] "" Vector__XXX
 SG_ IBST_a215_UnsupportedSeriesHWDet m3 : 38|1@1+ (1,0) [0|1] "" Vector__XXX
 SG_ IBST_a216_AsicMalfunctionDetecte m3 : 39|1@1+ (1,0) [0|1] "" Vector__XXX
 SG_ IBST_a217_AsicTrimmingNotComplet m3 : 40|1@1+ (1,0) [0|1] "" Vector__XXX
 SG_ IBST_a218_uCSafetyNotificationGR m3 : 41|1@1+ (1,0) [0|1] "" Vector__XXX
 SG_ IBST_a219_uCSafetyNotification m3 : 42|1@1+ (1,0) [0|1] "" Vector__XXX
 SG_ IBST_a220_ASICOvercurrentOnGPIO2 m3 : 43|1@1+ (1,0) [0|1] "" Vector__XXX
 SG_ IBST_a221_ASICOvercurrentOnGPIO2 m3 : 44|1@1+ (1,0) [0|1] "" Vector__XXX
 SG_ IBST_a222_ASICOvercurrentOnGPIO5 m3 : 45|1@1+ (1,0) [0|1] "" Vector__XXX
 SG_ IBST_a223_ASICOvercurrentOnGPIO5 m3 : 46|1@1+ (1,0) [0|1] "" Vector__XXX
 SG_ IBST_a224_ASICOvercurrentOnGPIO5 m3 : 47|1@1+ (1,0) [0|1] "" Vector__XXX
 SG_ IBST_a225_ASICOvercurrentOnGPIO5 m3 : 48|1@1+ (1,0) [0|1] "" Vector__XXX
 SG_ IBST_a226_ASICOvercurrentOnWRHS m3 : 49|1@1+ (1,0) [0|1] "" Vector__XXX
 SG_ IBST_a227_wakeRequestMismatchDet m3 : 50|1@1+ (1,0) [0|1] "" Vector__XXX
 SG_ IBST_a228_BlockedPedalDetectedDu m3 : 51|1@1+ (1,0) [0|1] "" Vector__XXX
 SG_ IBST_a229_BlockedPedalDetected m3 : 52|1@1+ (1,0) [0|1] "" Vector__XXX
 SG_ IBST_a230_DTS2FunctionalRangeLow m3 : 53|1@1+ (1,0) [0|1] "" Vector__XXX
 SG_ IBST_a231_DTS2FunctionalRangeLow m3 : 54|1@1+ (1,0) [0|1] "" Vector__XXX
 SG_ IBST_a232_PostAssemblyRoutineFai m3 : 55|1@1+ (1,0) [0|1] "" Vector__XXX
 SG_ IBST_a233_ReferenceRunAbortByECU m3 : 56|1@1+ (1,0) [0|1] "" Vector__XXX
 SG_ IBST_a234_LiPSOutOfRangeHigh m3 : 57|1@1+ (1,0) [0|1] "" Vector__XXX
 SG_ IBST_a235_LiPSOutOfRangeLow m3 : 58|1@1+ (1,0) [0|1] "" Vector__XXX

BO_ 1629 IBST_udsResponse: 8 IBST
 SG_ IBST_udsResponseData : 7|64@0+ (1,0) [0|1.84467440737e+19] "" Vector__XXX

BO_ 1208 ICR_alertLog: 8 ICR
 SG_ ICR_alertID M : 0|8@1+ (1,0) [0|255] "" Vector__XXX
 SG_ ICR_alertState : 15|1@1+ (1,0) [0|1] "" Vector__XXX
 SG_ ICR_a001_watchdogTaskAppDPM m1 : 16|1@1+ (1,0) [0|1] "" Vector__XXX
 SG_ ICR_a001_watchdogTaskMMWControl m1 : 17|1@1+ (1,0) [0|1] "" Vector__XXX
 SG_ ICR_a001_watchdogTaskSentinelInt m1 : 18|1@1+ (1,0) [0|1] "" Vector__XXX
 SG_ ICR_a001_watchdogTaskSentinelMod m1 : 19|1@1+ (1,0) [0|1] "" Vector__XXX
 SG_ ICR_a001_watchdogTaskComTXRAD m1 : 20|1@1+ (1,0) [0|1] "" Vector__XXX
 SG_ ICR_a001_watchdogTaskComRX m1 : 21|1@1+ (1,0) [0|1] "" Vector__XXX
 SG_ ICR_a001_watchdogTaskComTXVEH m1 : 22|1@1+ (1,0) [0|1] "" Vector__XXX
 SG_ ICR_a001_watchdogTaskComUDS m1 : 23|1@1+ (1,0) [0|1] "" Vector__XXX
 SG_ ICR_a001_watchdogTaskCommonError m1 : 24|1@1+ (1,0) [0|1] "" Vector__XXX
 SG_ ICR_a001_watchdogTaskUARTLog m1 : 25|1@1+ (1,0) [0|1] "" Vector__XXX
 SG_ ICR_a001_watchdogTaskDataDump m1 : 26|1@1+ (1,0) [0|1] "" Vector__XXX
 SG_ ICR_a001_watchdogRTOSAppRun10MS m1 : 27|1@1+ (1,0) [0|1] "" Vector__XXX
 SG_ ICR_a001_watchdogRTOSAppRun1MS m1 : 28|1@1+ (1,0) [0|1] "" Vector__XXX
 SG_ ICR_a001_InternalWatchdog m1 : 29|1@1+ (1,0) [0|1] "" Vector__XXX
 SG_ ICR_a002_CPUUndervoltage m2 : 16|1@1+ (1,0) [0|1] "" Vector__XXX
 SG_ ICR_a002_PowerOnReset m2 : 17|1@1+ (1,0) [0|1] "" Vector__XXX
 SG_ ICR_a015_NVMMMemOverflow m15 : 16|1@1+ (1,0) [0|1] "" Vector__XXX
 SG_ ICR_a015_NVMMFilesystemError m15 : 17|1@1+ (1,0) [0|1] "" Vector__XXX
 SG_ ICR_a015_NVMMRecordIDError m15 : 18|1@1+ (1,0) [0|1] "" Vector__XXX
 SG_ ICR_a059_voltageDrop m59 : 16|12@1+ (0.005443676,0) [0|22.29185322] "V" Vector__XXX
 SG_ ICR_a059_resistanceEstimate m59 : 28|12@1+ (0.00244,0) [0|9.9918] "Ohms" Vector__XXX
 SG_ ICR_a059_current m59 : 40|12@1+ (0.05,0) [0|204.75] "A" Vector__XXX
 SG_ ICR_a063_switchChannel m63 : 16|8@1+ (1,0) [0|255] "" Vector__XXX
 SG_ ICR_a063_switchType m63 : 24|8@1+ (1,0) [0|255] "" Vector__XXX
 SG_ ICR_a063_ADCVoltage m63 : 32|8@1+ (0.025,0) [0|6.375] "V" Vector__XXX
 SG_ ICR_a063_disconnected m63 : 40|1@1+ (1,0) [0|1] "" Vector__XXX
 SG_ ICR_a063_indeterminate m63 : 41|1@1+ (1,0) [0|1] "" Vector__XXX
 SG_ ICR_a063_stuckActive m63 : 42|1@1+ (1,0) [0|1] "" Vector__XXX
 SG_ ICR_a063_faulted m63 : 43|1@1+ (1,0) [0|1] "" Vector__XXX
 SG_ ICR_a133_nearClutter m133 : 16|8@1- (0.2,0) [-25.6|25.4] "dB" Vector__XXX
 SG_ ICR_a133_farClutter m133 : 24|8@1- (0.2,0) [-25.6|25.4] "dB" Vector__XXX
 SG_ ICR_a137_nearClutter m137 : 16|8@1- (0.2,0) [-25.6|25.4] "dB" Vector__XXX
 SG_ ICR_a137_farClutter m137 : 24|8@1- (0.2,0) [-25.6|25.4] "dB" Vector__XXX
 SG_ ICR_a139_nearClutter m139 : 16|8@1- (0.2,0) [-25.6|25.4] "dB" Vector__XXX
 SG_ ICR_a139_farClutter m139 : 24|8@1- (0.2,0) [-25.6|25.4] "dB" Vector__XXX

BO_ 2026 ICR_alertMatrix: 8 ICR
 SG_ ICR_matrixIndex M : 0|4@1+ (1,0) [0|15] "" Vector__XXX
 SG_ ICR_a001_WatchdogReset m0 : 4|1@1+ (1,0) [0|1] "" Vector__XXX
 SG_ ICR_a002_PowerLossReset m0 : 5|1@1+ (1,0) [0|1] "" Vector__XXX
 SG_ ICR_a003_SWAssertion m0 : 6|1@1+ (1,0) [0|1] "" Vector__XXX
 SG_ ICR_a005_CANTXError m0 : 8|1@1+ (1,0) [0|1] "" Vector__XXX
 SG_ ICR_a006_CANTX_cyclicError m0 : 9|1@1+ (1,0) [0|1] "" Vector__XXX
 SG_ ICR_a012_CPUReset m0 : 15|1@1+ (1,0) [0|1] "" Vector__XXX
 SG_ ICR_a013_AlertManagerFault m0 : 16|1@1+ (1,0) [0|1] "" Vector__XXX
 SG_ ICR_a015_NVMMError m0 : 18|1@1+ (1,0) [0|1] "" Vector__XXX
 SG_ ICR_a016_NVMMRecordError m0 : 19|1@1+ (1,0) [0|1] "" Vector__XXX
 SG_ ICR_a021_TaskSchedulerError m0 : 24|1@1+ (1,0) [0|1] "" Vector__XXX
 SG_ ICR_a022_TaskInitError m0 : 25|1@1+ (1,0) [0|1] "" Vector__XXX
 SG_ ICR_a029_CoreDump m0 : 32|1@1+ (1,0) [0|1] "" Vector__XXX
 SG_ ICR_a030_ECULogUploadRequest m0 : 33|1@1+ (1,0) [0|1] "" Vector__XXX
 SG_ ICR_a031_UDSActive m0 : 34|1@1+ (1,0) [0|1] "" Vector__XXX
 SG_ ICR_a041_HighCPULoad m0 : 44|1@1+ (1,0) [0|1] "" Vector__XXX
 SG_ ICR_a042_HighStackUsage m0 : 45|1@1+ (1,0) [0|1] "" Vector__XXX
 SG_ ICR_a043_Task1msError m0 : 46|1@1+ (1,0) [0|1] "" Vector__XXX
 SG_ ICR_a044_Task10msError m0 : 47|1@1+ (1,0) [0|1] "" Vector__XXX
 SG_ ICR_a045_Task100msError m0 : 48|1@1+ (1,0) [0|1] "" Vector__XXX
 SG_ ICR_a046_Task1000msError m0 : 49|1@1+ (1,0) [0|1] "" Vector__XXX
 SG_ ICR_a058_inputRHighSyncDebug m0 : 61|1@1+ (1,0) [0|1] "" Vector__XXX
 SG_ ICR_a059_inputResistanceHigh m0 : 62|1@1+ (1,0) [0|1] "" Vector__XXX
 SG_ ICR_a060_engineeringBuild m0 : 63|1@1+ (1,0) [0|1] "" Vector__XXX
 SG_ ICR_a061_XCPConnected m1 : 4|1@1+ (1,0) [0|1] "" Vector__XXX
 SG_ ICR_a062_XCPWasConnected m1 : 5|1@1+ (1,0) [0|1] "" Vector__XXX
 SG_ ICR_a063_SwitchFault m1 : 6|1@1+ (1,0) [0|1] "" Vector__XXX
 SG_ ICR_a064_busSleepReqTimeout m1 : 7|1@1+ (1,0) [0|1] "" Vector__XXX
 SG_ ICR_a133_radarBlocked m2 : 16|1@1+ (1,0) [0|1] "" Vector__XXX
 SG_ ICR_a134_radarPgood m2 : 17|1@1+ (1,0) [0|1] "" Vector__XXX
 SG_ ICR_a135_radarTxBallBreak m2 : 18|1@1+ (1,0) [0|1] "" Vector__XXX
 SG_ ICR_a136_radarHighTemperature m2 : 19|1@1+ (1,0) [0|1] "" Vector__XXX
 SG_ ICR_a137_radarBlocked m2 : 20|1@1+ (1,0) [0|1] "" Vector__XXX
 SG_ ICR_a138_DriverSideMismatch m2 : 21|1@1+ (1,0) [0|1] "" Vector__XXX
 SG_ ICR_a139_AbnormalBlockageDetecte m2 : 22|1@1+ (1,0) [0|1] "" Vector__XXX
 SG_ ICR_a140_OccupancyExceptionEncou m2 : 23|1@1+ (1,0) [0|1] "" Vector__XXX
 SG_ ICR_a141_RequiresReplacement m2 : 24|1@1+ (1,0) [0|1] "" Vector__XXX
 SG_ ICR_a142_ModeOverrideActive m2 : 25|1@1+ (1,0) [0|1] "" Vector__XXX

BO_ 760 ICR_intrusionDebug: 7 ICR
 SG_ ICR_loggingPeaksDBG : 0|16@1+ (1,0) [0|65535] "" Vector__XXX
 SG_ ICR_loggingCorrelationDBG : 16|16@1- (0.390625,0) [-12800|12799.609375] "%" Vector__XXX
 SG_ ICR_loggingTriggerRangeDBG : 32|8@1- (0.04,0) [-5.12|5.08] "m" Vector__XXX
 SG_ ICR_loggingTriggerXPosDBG : 40|8@1- (0.04,0) [-5.12|5.08] "m" Vector__XXX
 SG_ ICR_loggingTriggerYPosDBG : 48|8@1- (0.04,0) [-5.12|5.08] "m" Vector__XXX

BO_ 2025 ICR_occupancy: 8 ICR
 SG_ ICR_occupancy1LRaw : 0|2@1+ (1,0) [0|2] "" Vector__XXX
 SG_ ICR_occupancy1RRaw : 2|2@1+ (1,0) [0|2] "" Vector__XXX
 SG_ ICR_occupancy1LVoteCnt : 4|6@1- (1,0) [-32|31] "" Vector__XXX
 SG_ ICR_occupancy1RVoteCnt : 10|6@1- (1,0) [-32|31] "" Vector__XXX
 SG_ ICR_userPresenceFilt : 16|2@1+ (1,0) [0|2] "" Vector__XXX
 SG_ ICR_userPresenceRaw : 19|2@1+ (1,0) [0|2] "" Vector__XXX
 SG_ ICR_occupancy1LFilt : 21|2@1+ (1,0) [0|2] "" Vector__XXX
 SG_ ICR_occupancy1RFilt : 23|2@1+ (1,0) [0|2] "" Vector__XXX
 SG_ ICR_occupancy2LFilt : 25|2@1+ (1,0) [0|2] "" Vector__XXX
 SG_ ICR_occupancy2CFilt : 27|2@1+ (1,0) [0|2] "" Vector__XXX
 SG_ ICR_occupancy2RFilt : 29|2@1+ (1,0) [0|2] "" Vector__XXX
 SG_ ICR_childPresenceFilt : 31|3@1+ (1,0) [1|7] "" Vector__XXX
 SG_ ICR_childPresenceRaw : 34|3@1+ (1,0) [1|7] "" Vector__XXX
 SG_ ICR_classification1LFilt : 37|3@1+ (1,0) [1|7] "" Vector__XXX
 SG_ ICR_classification1RqF : 40|1@1+ (1,0) [0|1] "" Vector__XXX
 SG_ ICR_occupancy1RFiltExp : 41|2@1+ (1,0) [0|2] "" Vector__XXX
 SG_ ICR_occupancyCounter : 52|4@1+ (1,0) [0|15] "" Vector__XXX
 SG_ ICR_occupancyChecksum : 56|8@1+ (1,0) [0|255] "" Vector__XXX

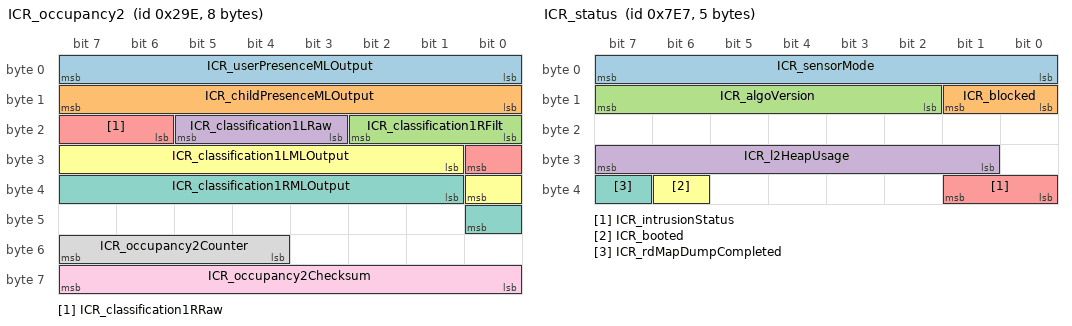
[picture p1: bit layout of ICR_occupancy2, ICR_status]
BO_ 670 ICR_occupancy2: 8 ICR
 SG_ ICR_userPresenceMLOutput : 0|8@1+ (0.004,0) [0|1.016] "points" Vector__XXX
 SG_ ICR_childPresenceMLOutput : 8|8@1+ (0.004,0) [0|1.016] "points" Vector__XXX
 SG_ ICR_classification1RFilt : 16|3@1+ (1,0) [1|7] "" Vector__XXX
 SG_ ICR_classification1LRaw : 19|3@1+ (1,0) [1|7] "" Vector__XXX
 SG_ ICR_classification1RRaw : 22|3@1+ (1,0) [1|7] "" Vector__XXX
 SG_ ICR_classification1LMLOutput : 25|8@1+ (0.004,0) [0|1.016] "points" Vector__XXX
 SG_ ICR_classification1RMLOutput : 33|8@1+ (0.004,0) [0|1.016] "points" Vector__XXX
 SG_ ICR_occupancy2Counter : 52|4@1+ (1,0) [0|15] "" Vector__XXX
 SG_ ICR_occupancy2Checksum : 56|8@1+ (1,0) [0|255] "" Vector__XXX

BO_ 2023 ICR_status: 5 ICR
 SG_ ICR_sensorMode : 0|8@1+ (1,0) [0|255] "" Vector__XXX
 SG_ ICR_blocked : 8|2@1+ (1,0) [1|3] "" Vector__XXX
 SG_ ICR_algoVersion : 10|6@1+ (1,0) [0|63] "" Vector__XXX
 SG_ ICR_l2HeapUsage : 25|7@1+ (1,0) [0|127] "PCT" Vector__XXX
 SG_ ICR_intrusionStatus : 32|2@1+ (1,0) [0|3] "" Vector__XXX
 SG_ ICR_booted : 38|1@1+ (1,0) [0|1] "" Vector__XXX
 SG_ ICR_rdMapDumpCompleted : 39|1@1+ (1,0) [0|1] "" Vector__XXX

BO_ 1624 ICR_udsResponse: 8 ICR
 SG_ ICR_udsResponseData : 7|64@0+ (1,0) [0|1.84467440737e+19] "" Vector__XXX

BO_ 1470 IDB_alertLog: 8 IDB
 SG_ IDB_alertID M : 0|8@1+ (1,0) [0|255] "" Vector__XXX
 SG_ IDB_alertState : 15|1@1+ (1,0) [0|1] "" Vector__XXX
 SG_ IDB_a014_wheelSpeedSensorFreq m14 : 16|1@1+ (1,0) [0|1] "" Vector__XXX
 SG_ IDB_a014_wheelSpeedSensorPhase m14 : 17|1@1+ (1,0) [0|1] "" Vector__XXX
 SG_ IDB_a014_wheelSpeedSensorMisinst m14 : 18|1@1+ (1,0) [0|1] "" Vector__XXX
 SG_ IDB_a014_wheelSpeedSensorWrongEx m14 : 19|1@1+ (1,0) [0|1] "" Vector__XXX
 SG_ IDB_a014_wheelSpeedSensorSpeedJu m14 : 20|1@1+ (1,0) [0|1] "" Vector__XXX
 SG_ IDB_a014_wheelSpeedSensorSp_0001 m14 : 21|1@1+ (1,0) [0|1] "" Vector__XXX
 SG_ IDB_a014_wheelSpeedSensorAirGap m14 : 22|1@1+ (1,0) [0|1] "" Vector__XXX
 SG_ IDB_a014_wheelSpeedSensorBIST m14 : 23|1@1+ (1,0) [0|1] "" Vector__XXX
 SG_ IDB_a014_wheelSpeedSensorLeakage m14 : 24|1@1+ (1,0) [0|1] "" Vector__XXX
 SG_ IDB_a014_wheelSpeedSensorOverTem m14 : 25|1@1+ (1,0) [0|1] "" Vector__XXX
 SG_ IDB_a014_wheelSpeedSensorSh_0001 m14 : 26|1@1+ (1,0) [0|1] "" Vector__XXX
 SG_ IDB_a014_wheelSpeedSensorShortTo m14 : 27|1@1+ (1,0) [0|1] "" Vector__XXX
 SG_ IDB_a014_wheelSpeedSensorOpen m14 : 28|1@1+ (1,0) [0|1] "" Vector__XXX
 SG_ IDB_a015_wheelSpeedSensorFreq m15 : 16|1@1+ (1,0) [0|1] "" Vector__XXX
 SG_ IDB_a015_wheelSpeedSensorPhase m15 : 17|1@1+ (1,0) [0|1] "" Vector__XXX
 SG_ IDB_a015_wheelSpeedSensorMisinst m15 : 18|1@1+ (1,0) [0|1] "" Vector__XXX
 SG_ IDB_a015_wheelSpeedSensorWrongEx m15 : 19|1@1+ (1,0) [0|1] "" Vector__XXX
 SG_ IDB_a015_wheelSpeedSensorSpeedJu m15 : 20|1@1+ (1,0) [0|1] "" Vector__XXX
 SG_ IDB_a015_wheelSpeedSensorSp_0001 m15 : 21|1@1+ (1,0) [0|1] "" Vector__XXX
 SG_ IDB_a015_wheelSpeedSensorAirGap m15 : 22|1@1+ (1,0) [0|1] "" Vector__XXX
 SG_ IDB_a015_wheelSpeedSensorBIST m15 : 23|1@1+ (1,0) [0|1] "" Vector__XXX
 SG_ IDB_a015_wheelSpeedSensorLeakage m15 : 24|1@1+ (1,0) [0|1] "" Vector__XXX
 SG_ IDB_a015_wheelSpeedSensorOverTem m15 : 25|1@1+ (1,0) [0|1] "" Vector__XXX
 SG_ IDB_a015_wheelSpeedSensorSh_0001 m15 : 26|1@1+ (1,0) [0|1] "" Vector__XXX
 SG_ IDB_a015_wheelSpeedSensorShortTo m15 : 27|1@1+ (1,0) [0|1] "" Vector__XXX
 SG_ IDB_a015_wheelSpeedSensorOpen m15 : 28|1@1+ (1,0) [0|1] "" Vector__XXX
 SG_ IDB_a016_wheelSpeedSensorFreq m16 : 16|1@1+ (1,0) [0|1] "" Vector__XXX
 SG_ IDB_a016_wheelSpeedSensorPhase m16 : 17|1@1+ (1,0) [0|1] "" Vector__XXX
 SG_ IDB_a016_wheelSpeedSensorMisinst m16 : 18|1@1+ (1,0) [0|1] "" Vector__XXX
 SG_ IDB_a016_wheelSpeedSensorWrongEx m16 : 19|1@1+ (1,0) [0|1] "" Vector__XXX
 SG_ IDB_a016_wheelSpeedSensorSpeedJu m16 : 20|1@1+ (1,0) [0|1] "" Vector__XXX
 SG_ IDB_a016_wheelSpeedSensorSp_0001 m16 : 21|1@1+ (1,0) [0|1] "" Vector__XXX
 SG_ IDB_a016_wheelSpeedSensorAirGap m16 : 22|1@1+ (1,0) [0|1] "" Vector__XXX
 SG_ IDB_a016_wheelSpeedSensorBIST m16 : 23|1@1+ (1,0) [0|1] "" Vector__XXX
 SG_ IDB_a016_wheelSpeedSensorLeakage m16 : 24|1@1+ (1,0) [0|1] "" Vector__XXX
 SG_ IDB_a016_wheelSpeedSensorOverTem m16 : 25|1@1+ (1,0) [0|1] "" Vector__XXX
 SG_ IDB_a016_wheelSpeedSensorSh_0001 m16 : 26|1@1+ (1,0) [0|1] "" Vector__XXX
 SG_ IDB_a016_wheelSpeedSensorShortTo m16 : 27|1@1+ (1,0) [0|1] "" Vector__XXX
 SG_ IDB_a016_wheelSpeedSensorOpen m16 : 28|1@1+ (1,0) [0|1] "" Vector__XXX
 SG_ IDB_a017_wheelSpeedSensorFreq m17 : 16|1@1+ (1,0) [0|1] "" Vector__XXX
 SG_ IDB_a017_wheelSpeedSensorPhase m17 : 17|1@1+ (1,0) [0|1] "" Vector__XXX
 SG_ IDB_a017_wheelSpeedSensorMisinst m17 : 18|1@1+ (1,0) [0|1] "" Vector__XXX
 SG_ IDB_a017_wheelSpeedSensorWrongEx m17 : 19|1@1+ (1,0) [0|1] "" Vector__XXX
 SG_ IDB_a017_wheelSpeedSensorSpeedJu m17 : 20|1@1+ (1,0) [0|1] "" Vector__XXX
 SG_ IDB_a017_wheelSpeedSensorSp_0001 m17 : 21|1@1+ (1,0) [0|1] "" Vector__XXX
 SG_ IDB_a017_wheelSpeedSensorAirGap m17 : 22|1@1+ (1,0) [0|1] "" Vector__XXX
 SG_ IDB_a017_wheelSpeedSensorBIST m17 : 23|1@1+ (1,0) [0|1] "" Vector__XXX
 SG_ IDB_a017_wheelSpeedSensorLeakage m17 : 24|1@1+ (1,0) [0|1] "" Vector__XXX
 SG_ IDB_a017_wheelSpeedSensorOverTem m17 : 25|1@1+ (1,0) [0|1] "" Vector__XXX
 SG_ IDB_a017_wheelSpeedSensorSh_0001 m17 : 26|1@1+ (1,0) [0|1] "" Vector__XXX
 SG_ IDB_a017_wheelSpeedSensorShortTo m17 : 27|1@1+ (1,0) [0|1] "" Vector__XXX
 SG_ IDB_a017_wheelSpeedSensorOpen m17 : 28|1@1+ (1,0) [0|1] "" Vector__XXX
 SG_ IDB_a020_canSignalValidity m20 : 16|1@1+ (1,0) [0|1] "" Vector__XXX
 SG_ IDB_a020_signalValueCrosscheck m20 : 17|1@1+ (1,0) [0|1] "" Vector__XXX
 SG_ IDB_a030_primaryExternalCircuitL m30 : 16|1@1+ (1,0) [0|1] "" Vector__XXX
 SG_ IDB_a030_secondaryExternalCircui m30 : 17|1@1+ (1,0) [0|1] "" Vector__XXX
 SG_ IDB_a030_primaryChamberInternalL m30 : 18|1@1+ (1,0) [0|1] "" Vector__XXX
 SG_ IDB_a030_syncModeInternalLeakage m30 : 19|1@1+ (1,0) [0|1] "" Vector__XXX
 SG_ IDB_a030_secondaryChamberInterna m30 : 20|1@1+ (1,0) [0|1] "" Vector__XXX
 SG_ IDB_a030_masterCylinderInternalL m30 : 21|1@1+ (1,0) [0|1] "" Vector__XXX
 SG_ IDB_a060_validityOnChassisBus m60 : 16|1@1+ (1,0) [0|1] "" Vector__XXX
 SG_ IDB_a060_validityOnPartyBus m60 : 17|1@1+ (1,0) [0|1] "" Vector__XXX
 SG_ IDB_a061_validityOnChassisBus m61 : 16|1@1+ (1,0) [0|1] "" Vector__XXX
 SG_ IDB_a061_validityOnPartyBus m61 : 17|1@1+ (1,0) [0|1] "" Vector__XXX
 SG_ IDB_a062_validityOnChassisBus m62 : 16|1@1+ (1,0) [0|1] "" Vector__XXX
 SG_ IDB_a062_validityOnPartyBus m62 : 17|1@1+ (1,0) [0|1] "" Vector__XXX
 SG_ IDB_a063_validityOnChassisBus m63 : 16|1@1+ (1,0) [0|1] "" Vector__XXX
 SG_ IDB_a063_validityOnPartyBus m63 : 17|1@1+ (1,0) [0|1] "" Vector__XXX
 SG_ IDB_a064_validityOnChassisBus m64 : 16|1@1+ (1,0) [0|1] "" Vector__XXX
 SG_ IDB_a064_validityOnPartyBus m64 : 17|1@1+ (1,0) [0|1] "" Vector__XXX
 SG_ IDB_a065_validityOnChassisBus m65 : 16|1@1+ (1,0) [0|1] "" Vector__XXX
 SG_ IDB_a065_validityOnPartyBus m65 : 17|1@1+ (1,0) [0|1] "" Vector__XXX
 SG_ IDB_a106_qualifierValidity m106 : 16|1@1+ (1,0) [0|1] "" Vector__XXX
 SG_ IDB_a106_signalNotAvailable m106 : 17|1@1+ (1,0) [0|1] "" Vector__XXX
 SG_ IDB_a107_qualifierValidity m107 : 16|1@1+ (1,0) [0|1] "" Vector__XXX
 SG_ IDB_a107_signalNotAvailable m107 : 17|1@1+ (1,0) [0|1] "" Vector__XXX
 SG_ IDB_a112_qualifierValidity m112 : 16|1@1+ (1,0) [0|1] "" Vector__XXX
 SG_ IDB_a112_signalNotAvailable m112 : 17|1@1+ (1,0) [0|1] "" Vector__XXX
 SG_ IDB_a113_qualifierValidity m113 : 16|1@1+ (1,0) [0|1] "" Vector__XXX
 SG_ IDB_a113_signalNotAvailable m113 : 17|1@1+ (1,0) [0|1] "" Vector__XXX
 SG_ IDB_a114_qualifierValidity m114 : 16|1@1+ (1,0) [0|1] "" Vector__XXX
 SG_ IDB_a114_signalNotAvailable m114 : 17|1@1+ (1,0) [0|1] "" Vector__XXX
 SG_ IDB_a126_PMebrCmdStateValidity m126 : 16|1@1+ (1,0) [0|1] "" Vector__XXX
 SG_ IDB_a126_PMstate2Validity m126 : 17|1@1+ (1,0) [0|1] "" Vector__XXX
 SG_ IDB_a126_PMstate2Missing m126 : 18|1@1+ (1,0) [0|1] "" Vector__XXX
 SG_ IDB_a126_DIchassisControlValidit m126 : 19|1@1+ (1,0) [0|1] "" Vector__XXX
 SG_ IDB_a126_DIchassisControlMissing m126 : 20|1@1+ (1,0) [0|1] "" Vector__XXX
 SG_ IDB_a126_DIrequestActiveValidity m126 : 21|1@1+ (1,0) [0|1] "" Vector__XXX
 SG_ IDB_a129_validityOnChassisBus m129 : 16|1@1+ (1,0) [0|1] "" Vector__XXX
 SG_ IDB_a129_validityOnPartyBus m129 : 17|1@1+ (1,0) [0|1] "" Vector__XXX
 SG_ IDB_a130_PMbrakePedalCmdQFValidi m130 : 16|1@1+ (1,0) [0|1] "" Vector__XXX
 SG_ IDB_a130_PMstate2Validity m130 : 17|1@1+ (1,0) [0|1] "" Vector__XXX
 SG_ IDB_a130_PMstate2Missing m130 : 18|1@1+ (1,0) [0|1] "" Vector__XXX
 SG_ IDB_a130_DIbrakeCommandValidity m130 : 19|1@1+ (1,0) [0|1] "" Vector__XXX
 SG_ IDB_a130_DIbrakeCommandMissing m130 : 20|1@1+ (1,0) [0|1] "" Vector__XXX
 SG_ IDB_a130_DIbrakeTorqueCommandFul m130 : 21|1@1+ (1,0) [0|1] "" Vector__XXX
 SG_ IDB_a130_DIbrakeTorqueComma_0001 m130 : 22|1@1+ (1,0) [0|1] "" Vector__XXX
 SG_ IDB_a132_validityOnChassisBus m132 : 16|1@1+ (1,0) [0|1] "" Vector__XXX
 SG_ IDB_a132_validityOnPartyBus m132 : 17|1@1+ (1,0) [0|1] "" Vector__XXX

BO_ 983 IDB_alertMatrix: 8 IDB
 SG_ IDB_matrixIndex M : 0|4@1+ (1,0) [0|15] "" Vector__XXX
 SG_ IDB_a001_mcuGenericFault m0 : 4|1@1+ (1,0) [0|1] "" Vector__XXX
 SG_ IDB_a002_supplyOvervoltage m0 : 5|1@1+ (1,0) [0|1] "" Vector__XXX
 SG_ IDB_a003_supplyHardOvervoltage m0 : 6|1@1+ (1,0) [0|1] "" Vector__XXX
 SG_ IDB_a004_supplyUndervoltage m0 : 7|1@1+ (1,0) [0|1] "" Vector__XXX
 SG_ IDB_a005_supplyMidUndervoltage m0 : 8|1@1+ (1,0) [0|1] "" Vector__XXX
 SG_ IDB_a006_supplyHardUndervoltage m0 : 9|1@1+ (1,0) [0|1] "" Vector__XXX
 SG_ IDB_a007_wakeLineOpen m0 : 10|1@1+ (1,0) [0|1] "" Vector__XXX
 SG_ IDB_a008_motorPowerOpen m0 : 11|1@1+ (1,0) [0|1] "" Vector__XXX
 SG_ IDB_a009_asicBoostFault m0 : 12|1@1+ (1,0) [0|1] "" Vector__XXX
 SG_ IDB_a010_asicGenericFault m0 : 13|1@1+ (1,0) [0|1] "" Vector__XXX
 SG_ IDB_a011_solenoidValveFault m0 : 14|1@1+ (1,0) [0|1] "" Vector__XXX
 SG_ IDB_a012_motorGenericFault m0 : 15|1@1+ (1,0) [0|1] "" Vector__XXX
 SG_ IDB_a013_motorPosSensorFault m0 : 16|1@1+ (1,0) [0|1] "" Vector__XXX
 SG_ IDB_a014_FrLWSSFault m0 : 17|1@1+ (1,0) [0|1] "" Vector__XXX
 SG_ IDB_a015_FrRWSSFault m0 : 18|1@1+ (1,0) [0|1] "" Vector__XXX
 SG_ IDB_a016_ReLWSSFault m0 : 19|1@1+ (1,0) [0|1] "" Vector__XXX
 SG_ IDB_a017_ReRWSSFault m0 : 20|1@1+ (1,0) [0|1] "" Vector__XXX
 SG_ IDB_a018_WSSGenericFault m0 : 21|1@1+ (1,0) [0|1] "" Vector__XXX
 SG_ IDB_a019_pedalSensorFault m0 : 22|1@1+ (1,0) [0|1] "" Vector__XXX
 SG_ IDB_a020_RCUpedalTravelMismatch m0 : 23|1@1+ (1,0) [0|1] "" Vector__XXX
 SG_ IDB_a021_pedalSensorNotCal m0 : 24|1@1+ (1,0) [0|1] "" Vector__XXX
 SG_ IDB_a022_brakeFluidLow m0 : 25|1@1+ (1,0) [0|1] "" Vector__XXX
 SG_ IDB_a023_steeringImplausible m0 : 26|1@1+ (1,0) [0|1] "" Vector__XXX
 SG_ IDB_a024_yawImplausible m0 : 27|1@1+ (1,0) [0|1] "" Vector__XXX
 SG_ IDB_a025_ayImplausible m0 : 28|1@1+ (1,0) [0|1] "" Vector__XXX
 SG_ IDB_a026_axImplausible m0 : 29|1@1+ (1,0) [0|1] "" Vector__XXX
 SG_ IDB_a027_circuitPresSensorFault m0 : 30|1@1+ (1,0) [0|1] "" Vector__XXX
 SG_ IDB_a028_simPresSensorFault m0 : 31|1@1+ (1,0) [0|1] "" Vector__XXX
 SG_ IDB_a029_pressureSensNotCal m0 : 32|1@1+ (1,0) [0|1] "" Vector__XXX
 SG_ IDB_a030_fluidLeakDetected m0 : 33|1@1+ (1,0) [0|1] "" Vector__XXX
 SG_ IDB_a031_solenoidValveStuck m0 : 34|1@1+ (1,0) [0|1] "" Vector__XXX
 SG_ IDB_a032_motorSoftOverheat m0 : 35|1@1+ (1,0) [0|1] "" Vector__XXX
 SG_ IDB_a033_motorHardOverheat m0 : 36|1@1+ (1,0) [0|1] "" Vector__XXX
 SG_ IDB_a034_motorPositionSetFault m0 : 37|1@1+ (1,0) [0|1] "" Vector__XXX
 SG_ IDB_a035_motorStuck m0 : 38|1@1+ (1,0) [0|1] "" Vector__XXX
 SG_ IDB_a036_partyBusOff m0 : 39|1@1+ (1,0) [0|1] "" Vector__XXX
 SG_ IDB_a037_chassisBusOff m0 : 40|1@1+ (1,0) [0|1] "" Vector__XXX
 SG_ IDB_a038_motorInitFault m0 : 41|1@1+ (1,0) [0|1] "" Vector__XXX
 SG_ IDB_a039_absActive m0 : 42|1@1+ (1,0) [0|1] "" Vector__XXX
 SG_ IDB_a040_ebdActive m0 : 43|1@1+ (1,0) [0|1] "" Vector__XXX
 SG_ IDB_a041_vdcActive m0 : 44|1@1+ (1,0) [0|1] "" Vector__XXX
 SG_ IDB_a042_btcActive m0 : 45|1@1+ (1,0) [0|1] "" Vector__XXX
 SG_ IDB_a043_DItorquePathActive m0 : 46|1@1+ (1,0) [0|1] "" Vector__XXX
 SG_ IDB_a044_standstillSkidDetected m0 : 47|1@1+ (1,0) [0|1] "" Vector__XXX
 SG_ IDB_a045_panicBrakeAssistActive m0 : 48|1@1+ (1,0) [0|1] "" Vector__XXX
 SG_ IDB_a046_fadeCompensationActive m0 : 49|1@1+ (1,0) [0|1] "" Vector__XXX
 SG_ IDB_a047_brakeDiscWipeActive m0 : 50|1@1+ (1,0) [0|1] "" Vector__XXX
 SG_ IDB_a048_scmActive m0 : 51|1@1+ (1,0) [0|1] "" Vector__XXX
 SG_ IDB_a049_cdpActive m0 : 52|1@1+ (1,0) [0|1] "" Vector__XXX
 SG_ IDB_a050_absFaulted m0 : 53|1@1+ (1,0) [0|1] "" Vector__XXX
 SG_ IDB_a051_ebdFaulted m0 : 54|1@1+ (1,0) [0|1] "" Vector__XXX
 SG_ IDB_a052_vdcFaulted m0 : 55|1@1+ (1,0) [0|1] "" Vector__XXX
 SG_ IDB_a053_DItorquePathFaulted m0 : 56|1@1+ (1,0) [0|1] "" Vector__XXX
 SG_ IDB_a054_skidDetectionFaulted m0 : 57|1@1+ (1,0) [0|1] "" Vector__XXX
 SG_ IDB_a055_panicBrakeAssistFaulted m0 : 58|1@1+ (1,0) [0|1] "" Vector__XXX
 SG_ IDB_a056_fadeCompensationFaulted m0 : 59|1@1+ (1,0) [0|1] "" Vector__XXX
 SG_ IDB_a057_bdwRequestInvalid m0 : 60|1@1+ (1,0) [0|1] "" Vector__XXX
 SG_ IDB_a058_scmFaulted m0 : 61|1@1+ (1,0) [0|1] "" Vector__XXX
 SG_ IDB_a059_cdpFaulted m0 : 62|1@1+ (1,0) [0|1] "" Vector__XXX
 SG_ IDB_a060_RCUstatusDLC m0 : 63|1@1+ (1,0) [0|1] "" Vector__XXX
 SG_ IDB_a061_RCUstatusChecksum m1 : 4|1@1+ (1,0) [0|1] "" Vector__XXX
 SG_ IDB_a062_RCUstatusCounter m1 : 5|1@1+ (1,0) [0|1] "" Vector__XXX
 SG_ IDB_a063_RCUactuationDLC m1 : 6|1@1+ (1,0) [0|1] "" Vector__XXX
 SG_ IDB_a064_RCUactuationChecksum m1 : 7|1@1+ (1,0) [0|1] "" Vector__XXX
 SG_ IDB_a065_RCUactuationCounter m1 : 8|1@1+ (1,0) [0|1] "" Vector__XXX
 SG_ IDB_a066_DIFtorqueDLC m1 : 9|1@1+ (1,0) [0|1] "" Vector__XXX
 SG_ IDB_a067_DIFtorqueChecksum m1 : 10|1@1+ (1,0) [0|1] "" Vector__XXX
 SG_ IDB_a068_DIFtorqueCounter m1 : 11|1@1+ (1,0) [0|1] "" Vector__XXX
 SG_ IDB_a069_DIchassisControlDLC m1 : 12|1@1+ (1,0) [0|1] "" Vector__XXX
 SG_ IDB_a070_DIchassisControlChecksu m1 : 13|1@1+ (1,0) [0|1] "" Vector__XXX
 SG_ IDB_a071_DIchassisControlCounter m1 : 14|1@1+ (1,0) [0|1] "" Vector__XXX
 SG_ IDB_a072_DIsystemStatusDLC m1 : 15|1@1+ (1,0) [0|1] "" Vector__XXX
 SG_ IDB_a073_DIsystemStatusChecksum m1 : 16|1@1+ (1,0) [0|1] "" Vector__XXX
 SG_ IDB_a074_DIsystemStatusCounter m1 : 17|1@1+ (1,0) [0|1] "" Vector__XXX
 SG_ IDB_a075_DIRtorqueDLC m1 : 18|1@1+ (1,0) [0|1] "" Vector__XXX
 SG_ IDB_a076_DIRtorqueChecksum m1 : 19|1@1+ (1,0) [0|1] "" Vector__XXX
 SG_ IDB_a077_DIRtorqueCounter m1 : 20|1@1+ (1,0) [0|1] "" Vector__XXX
 SG_ IDB_a078_DIvdcLeftDLC m1 : 21|1@1+ (1,0) [0|1] "" Vector__XXX
 SG_ IDB_a079_DIvdcLeftChecksum m1 : 22|1@1+ (1,0) [0|1] "" Vector__XXX
 SG_ IDB_a080_DIvdcLeftCounter m1 : 23|1@1+ (1,0) [0|1] "" Vector__XXX
 SG_ IDB_a081_DIvdcRightDLC m1 : 24|1@1+ (1,0) [0|1] "" Vector__XXX
 SG_ IDB_a082_DIvdcRightChecksum m1 : 25|1@1+ (1,0) [0|1] "" Vector__XXX
 SG_ IDB_a083_DIvdcRightCounter m1 : 26|1@1+ (1,0) [0|1] "" Vector__XXX
 SG_ IDB_a084_EPAS3PsysStatusDLC m1 : 27|1@1+ (1,0) [0|1] "" Vector__XXX
 SG_ IDB_a085_EPAS3PsysStatusChecksum m1 : 28|1@1+ (1,0) [0|1] "" Vector__XXX
 SG_ IDB_a086_EPAS3PsysStatusCounter m1 : 29|1@1+ (1,0) [0|1] "" Vector__XXX
 SG_ IDB_a087_PMstate2DLC m1 : 30|1@1+ (1,0) [0|1] "" Vector__XXX
 SG_ IDB_a088_PMstate2Checksum m1 : 31|1@1+ (1,0) [0|1] "" Vector__XXX
 SG_ IDB_a089_PMstate2Counter m1 : 32|1@1+ (1,0) [0|1] "" Vector__XXX
 SG_ IDB_a090_RCMinertial1DLC m1 : 33|1@1+ (1,0) [0|1] "" Vector__XXX
 SG_ IDB_a091_RCMinertial1Checksum m1 : 34|1@1+ (1,0) [0|1] "" Vector__XXX
 SG_ IDB_a092_RCMinertial1Counter m1 : 35|1@1+ (1,0) [0|1] "" Vector__XXX
 SG_ IDB_a093_RCMinertial2DLC m1 : 36|1@1+ (1,0) [0|1] "" Vector__XXX
 SG_ IDB_a094_RCMinertial2Checksum m1 : 37|1@1+ (1,0) [0|1] "" Vector__XXX
 SG_ IDB_a095_RCMinertial2Counter m1 : 38|1@1+ (1,0) [0|1] "" Vector__XXX
 SG_ IDB_a096_VCFRONTLVPowerStateDLC m1 : 39|1@1+ (1,0) [0|1] "" Vector__XXX
 SG_ IDB_a097_VCFRONTLVPwrStChecksum m1 : 40|1@1+ (1,0) [0|1] "" Vector__XXX
 SG_ IDB_a098_VCFRONTLVPwrStCounter m1 : 41|1@1+ (1,0) [0|1] "" Vector__XXX
 SG_ IDB_a099_RCMcollisionDLC m1 : 42|1@1+ (1,0) [0|1] "" Vector__XXX
 SG_ IDB_a100_RCMcollisionChecksum m1 : 43|1@1+ (1,0) [0|1] "" Vector__XXX
 SG_ IDB_a101_RCMcollisionCounter m1 : 44|1@1+ (1,0) [0|1] "" Vector__XXX
 SG_ IDB_a102_bdwRequestActiveInvalid m1 : 45|1@1+ (1,0) [0|1] "" Vector__XXX
 SG_ IDB_a103_DIfullTorquePathFaulted m1 : 46|1@1+ (1,0) [0|1] "" Vector__XXX
 SG_ IDB_a104_DIaccelPosInvalid m1 : 47|1@1+ (1,0) [0|1] "" Vector__XXX
 SG_ IDB_a105_DIgearInvalid m1 : 48|1@1+ (1,0) [0|1] "" Vector__XXX
 SG_ IDB_a106_DIFtorqueInvalid m1 : 49|1@1+ (1,0) [0|1] "" Vector__XXX
 SG_ IDB_a107_DIRtorqueInvalid m1 : 50|1@1+ (1,0) [0|1] "" Vector__XXX
 SG_ IDB_a108_EPBstatusDLC m1 : 51|1@1+ (1,0) [0|1] "" Vector__XXX
 SG_ IDB_a109_BDWsignalInvalid m1 : 52|1@1+ (1,0) [0|1] "" Vector__XXX
 SG_ IDB_a110_EPBstatusCounter m1 : 53|1@1+ (1,0) [0|1] "" Vector__XXX
 SG_ IDB_a111_EPBstatusChecksum m1 : 54|1@1+ (1,0) [0|1] "" Vector__XXX
 SG_ IDB_a112_yawRateInvalid m1 : 55|1@1+ (1,0) [0|1] "" Vector__XXX
 SG_ IDB_a113_latAccelInvalid m1 : 56|1@1+ (1,0) [0|1] "" Vector__XXX
 SG_ IDB_a114_longAccelInvalid m1 : 57|1@1+ (1,0) [0|1] "" Vector__XXX
 SG_ IDB_a115_VCFRONTespLvStInvalid m1 : 58|1@1+ (1,0) [0|1] "" Vector__XXX
 SG_ IDB_a116_VCFRONTsensorsDLC m1 : 59|1@1+ (1,0) [0|1] "" Vector__XXX
 SG_ IDB_a117_VCLEFTepbmStatusDLC m1 : 60|1@1+ (1,0) [0|1] "" Vector__XXX
 SG_ IDB_a118_VCLEFTepbmStatusCounter m1 : 61|1@1+ (1,0) [0|1] "" Vector__XXX
 SG_ IDB_a119_VCLEFTepbmStatusChecksu m1 : 62|1@1+ (1,0) [0|1] "" Vector__XXX
 SG_ IDB_a120_EPAS3Pinvalid m1 : 63|1@1+ (1,0) [0|1] "" Vector__XXX
 SG_ IDB_a121_dynoModeActive m2 : 4|1@1+ (1,0) [0|1] "" Vector__XXX
 SG_ IDB_a122_DIFtorqueCommandInvalid m2 : 5|1@1+ (1,0) [0|1] "" Vector__XXX
 SG_ IDB_a123_DIRtorqueCommandInvalid m2 : 6|1@1+ (1,0) [0|1] "" Vector__XXX
 SG_ IDB_a124_VCFRONTtempInvalid m2 : 7|1@1+ (1,0) [0|1] "" Vector__XXX
 SG_ IDB_a125_PMvdcCmdStateInvalid m2 : 8|1@1+ (1,0) [0|1] "" Vector__XXX
 SG_ IDB_a126_DItorqueRequestInvalid m2 : 9|1@1+ (1,0) [0|1] "" Vector__XXX
 SG_ IDB_a127_brakeFluidLevelInvalid m2 : 10|1@1+ (1,0) [0|1] "" Vector__XXX
 SG_ IDB_a128_reserved1 m2 : 11|1@1+ (1,0) [0|1] "" Vector__XXX
 SG_ IDB_a129_RCUinputRodStrokeInvali m2 : 12|1@1+ (1,0) [0|1] "" Vector__XXX
 SG_ IDB_a130_DIfullTorqueRequestInva m2 : 13|1@1+ (1,0) [0|1] "" Vector__XXX
 SG_ IDB_a131_DIfullTorquePathActive m2 : 14|1@1+ (1,0) [0|1] "" Vector__XXX
 SG_ IDB_a132_RCUinputRodStrokeQFInva m2 : 15|1@1+ (1,0) [0|1] "" Vector__XXX
 SG_ IDB_a133_DIbrakeCommandDLC m2 : 16|1@1+ (1,0) [0|1] "" Vector__XXX
 SG_ IDB_a134_DIbrakeCommandCounter m2 : 17|1@1+ (1,0) [0|1] "" Vector__XXX
 SG_ IDB_a135_DIbrakeCommandChecksum m2 : 18|1@1+ (1,0) [0|1] "" Vector__XXX
 SG_ IDB_a136_RCUptsCalMissing m2 : 19|1@1+ (1,0) [0|1] "" Vector__XXX
 SG_ IDB_a137_VCLEFTcdpRequestInvalid m2 : 20|1@1+ (1,0) [0|1] "" Vector__XXX
 SG_ IDB_a138_DIbrakeTorqueCommandAnd m2 : 21|1@1+ (1,0) [0|1] "" Vector__XXX
 SG_ IDB_a139_DIbrakeTorqueCommandFul m2 : 22|1@1+ (1,0) [0|1] "" Vector__XXX
 SG_ IDB_a140_PMbrakePedalCmdQFInvali m2 : 23|1@1+ (1,0) [0|1] "" Vector__XXX
 SG_ IDB_a141_DIbrakeTorqueCommandFul m2 : 24|1@1+ (1,0) [0|1] "" Vector__XXX
 SG_ IDB_a142_PMebrCmdStateInvalid m2 : 25|1@1+ (1,0) [0|1] "" Vector__XXX
 SG_ IDB_a143_factoryModeActive m2 : 26|1@1+ (1,0) [0|1] "" Vector__XXX
 SG_ IDB_a144_hydraulicPushthroughAct m2 : 27|1@1+ (1,0) [0|1] "" Vector__XXX

BO_ 1429 OCS1P_alertLog: 8 OCS1P
 SG_ OCS1P_alertID M : 0|8@1+ (1,0) [0|255] "" Vector__XXX
 SG_ OCS1P_alertState : 15|1@1+ (1,0) [0|1] "" Vector__XXX
 SG_ OCS1P_a121_sandwichFreq m121 : 16|32@1+ (1,0) [0|4294967295] "" Vector__XXX
 SG_ OCS1P_a122_sandwichFreq m122 : 16|32@1+ (1,0) [0|4294967295] "" Vector__XXX
 SG_ OCS1P_a123_sandwichFreq m123 : 16|32@1+ (1,0) [0|4294967295] "" Vector__XXX
 SG_ OCS1P_a124_cushionSelfFreq m124 : 16|32@1+ (1,0) [0|4294967295] "" Vector__XXX
 SG_ OCS1P_a125_cushionSelfFreq m125 : 16|32@1+ (1,0) [0|4294967295] "" Vector__XXX
 SG_ OCS1P_a126_cushionSelfFreq m126 : 16|32@1+ (1,0) [0|4294967295] "" Vector__XXX
 SG_ OCS1P_a127_seatbackSelfFreq m127 : 16|32@1+ (1,0) [0|4294967295] "" Vector__XXX
 SG_ OCS1P_a128_seatbackSelfFreq m128 : 16|32@1+ (1,0) [0|4294967295] "" Vector__XXX
 SG_ OCS1P_a129_seatbackSelfFreq m129 : 16|32@1+ (1,0) [0|4294967295] "" Vector__XXX
 SG_ OCS1P_a130_sandwichNoCalib m130 : 16|1@1+ (1,0) [0|1] "" Vector__XXX
 SG_ OCS1P_a131_cushionSelfNoCalib m131 : 16|1@1+ (1,0) [0|1] "" Vector__XXX
 SG_ OCS1P_a132_seatbackSelfNoCalib m132 : 16|1@1+ (1,0) [0|1] "" Vector__XXX
 SG_ OCS1P_a133_sandwichBadCalib m133 : 16|1@1+ (1,0) [0|1] "" Vector__XXX
 SG_ OCS1P_a134_uninitializedCalib m134 : 16|1@1+ (1,0) [0|1] "" Vector__XXX
 SG_ OCS1P_a135_tempNoCalib m135 : 16|1@1+ (1,0) [0|1] "" Vector__XXX
 SG_ OCS1P_a140_tempInvalidCalib m140 : 16|1@1+ (1,0) [0|1] "" Vector__XXX
 SG_ OCS1P_a141_humidityInvalidCalib m141 : 16|1@1+ (1,0) [0|1] "" Vector__XXX
 SG_ OCS1P_a142_tempHumidityInvalid m142 : 16|1@1+ (1,0) [0|1] "" Vector__XXX
 SG_ OCS1P_a143_mismatchPassAirbag m143 : 16|1@1+ (1,0) [0|1] "" Vector__XXX
 SG_ OCS1P_a144_mismatchCarRegion m144 : 16|1@1+ (1,0) [0|1] "" Vector__XXX

BO_ 767 OCS1P_alertMatrix: 8 OCS1P
 SG_ OCS1P_matrixIndex M : 0|4@1+ (1,0) [0|15] "" Vector__XXX
 SG_ OCS1P_w015_NVMMAlert m0 : 18|1@1+ (1,0) [0|1] "" Vector__XXX
 SG_ OCS1P_w121_sandwichOpen m2 : 4|1@1+ (1,0) [0|1] "" Vector__XXX
 SG_ OCS1P_w122_sandwichLow m2 : 5|1@1+ (1,0) [0|1] "" Vector__XXX
 SG_ OCS1P_w123_sandwichShort m2 : 6|1@1+ (1,0) [0|1] "" Vector__XXX
 SG_ OCS1P_w124_cushionSelfOpen m2 : 7|1@1+ (1,0) [0|1] "" Vector__XXX
 SG_ OCS1P_w125_cushionSelfLow m2 : 8|1@1+ (1,0) [0|1] "" Vector__XXX
 SG_ OCS1P_w126_cushionSelfShort m2 : 9|1@1+ (1,0) [0|1] "" Vector__XXX
 SG_ OCS1P_w127_seatbackSelfOpen m2 : 10|1@1+ (1,0) [0|1] "" Vector__XXX
 SG_ OCS1P_w128_seatbackSelfLow m2 : 11|1@1+ (1,0) [0|1] "" Vector__XXX
 SG_ OCS1P_w129_seatbackSelfShort m2 : 12|1@1+ (1,0) [0|1] "" Vector__XXX
 SG_ OCS1P_w130_sandwichNoCalib m2 : 13|1@1+ (1,0) [0|1] "" Vector__XXX
 SG_ OCS1P_w131_cushionSelfNoCalib m2 : 14|1@1+ (1,0) [0|1] "" Vector__XXX
 SG_ OCS1P_w132_seatbackSelfNoCalib m2 : 15|1@1+ (1,0) [0|1] "" Vector__XXX
 SG_ OCS1P_w133_sandwichBadCalib m2 : 16|1@1+ (1,0) [0|1] "" Vector__XXX
 SG_ OCS1P_w134_uninitializedCalib m2 : 17|1@1+ (1,0) [0|1] "" Vector__XXX
 SG_ OCS1P_w135_tempNoCalib m2 : 18|1@1+ (1,0) [0|1] "" Vector__XXX
 SG_ OCS1P_w136_cushionSelfDutyLow m2 : 19|1@1+ (1,0) [0|1] "" Vector__XXX
 SG_ OCS1P_w137_cushionSelfDutyHigh m2 : 20|1@1+ (1,0) [0|1] "" Vector__XXX
 SG_ OCS1P_w138_seatbackSelfDutyLow m2 : 21|1@1+ (1,0) [0|1] "" Vector__XXX
 SG_ OCS1P_w139_seatbackSelfDutyHigh m2 : 22|1@1+ (1,0) [0|1] "" Vector__XXX
 SG_ OCS1P_w140_tempInvalidCalib m2 : 23|1@1+ (1,0) [0|1] "" Vector__XXX
 SG_ OCS1P_w141_humidityInvalidCalib m2 : 24|1@1+ (1,0) [0|1] "" Vector__XXX
 SG_ OCS1P_w142_tempHumidityInvalid m2 : 25|1@1+ (1,0) [0|1] "" Vector__XXX
 SG_ OCS1P_w143_mismatchPassAirbag m2 : 26|1@1+ (1,0) [0|1] "" Vector__XXX
 SG_ OCS1P_w144_mismatchCarRegion m2 : 27|1@1+ (1,0) [0|1] "" Vector__XXX
 SG_ OCS1P_w145_rebaselineTriggered m2 : 28|1@1+ (1,0) [0|1] "" Vector__XXX
 SG_ OCS1P_w148_classificationMismatc m2 : 31|1@1+ (1,0) [0|1] "" Vector__XXX
 SG_ OCS1P_w150_rbEntryTriggered m2 : 33|1@1+ (1,0) [0|1] "" Vector__XXX
 SG_ OCS1P_w151_rbEntryExited m2 : 34|1@1+ (1,0) [0|1] "" Vector__XXX
 SG_ OCS1P_w152_rbExit1Triggered m2 : 35|1@1+ (1,0) [0|1] "" Vector__XXX
 SG_ OCS1P_w153_rbExit1Exited m2 : 36|1@1+ (1,0) [0|1] "" Vector__XXX
 SG_ OCS1P_w154_rbExit2Exited1 m2 : 37|1@1+ (1,0) [0|1] "" Vector__XXX
 SG_ OCS1P_w155_rbExit2Exited2 m2 : 38|1@1+ (1,0) [0|1] "" Vector__XXX

BO_ 766 OCS1P_info: 8 OCS1P
 SG_ OCS1P_infoIndex M : 0|8@1+ (1,0) [0|255] "" Vector__XXX
 SG_ OCS1P_infoBuildType m10 : 8|8@1+ (1,0) [0|255] "" Vector__XXX
 SG_ OCS1P_infoBuildConfigID m10 : 16|16@1+ (1,0) [0|65535] "" Vector__XXX
 SG_ OCS1P_infoHardwareID m10 : 32|16@1+ (1,0) [0|65535] "" Vector__XXX
 SG_ OCS1P_infoComponentID m10 : 48|16@1+ (1,0) [0|65535] "" Vector__XXX
 SG_ OCS1P_infoPcbaID m11 : 16|8@1+ (1,0) [0|255] "" Vector__XXX
 SG_ OCS1P_infoAssemblyID m11 : 24|8@1+ (1,0) [0|255] "" Vector__XXX
 SG_ OCS1P_infoUsageID m11 : 32|16@1+ (1,0) [0|65535] "" Vector__XXX
 SG_ OCS1P_infoSubUsageID m11 : 48|16@1+ (1,0) [0|65535] "" Vector__XXX
 SG_ OCS1P_infoApplicationCRC m13 : 32|32@1+ (1,0) [0|4294967295] "" Vector__XXX
 SG_ OCS1P_infoBootSvnRev m14 : 8|24@1+ (1,0) [0|16777215] "" Vector__XXX
 SG_ OCS1P_infoAppGitHashBytes m17 : 8|56@1+ (1,0) [0|7.20575940379e+16] "" Vector__XXX
 SG_ OCS1P_infoBootGitHashBytes m18 : 8|56@1+ (1,0) [0|7.20575940379e+16] "" Vector__XXX
 SG_ OCS1P_infoPlatformType m19 : 8|8@1+ (1,0) [0|255] "" Vector__XXX
 SG_ OCS1P_infoBootUdsProtoVersion m20 : 8|8@1+ (1,0) [0|255] "" Vector__XXX
 SG_ OCS1P_infoBootloaderCRC m20 : 32|32@1+ (1,0) [0|4294967295] "" Vector__XXX

BO_TX_BU_ 938 : HVP;
BO_TX_BU_ 522 : HVP;
BO_TX_BU_ 1962 : HVP;
BO_TX_BU_ 1666 : HVP;
BO_TX_BU_ 1553 : HVP;
BO_TX_BU_ 861 : IBST;
BO_TX_BU_ 1629 : IBST;
BO_TX_BU_ 1208 : ICR;
BO_TX_BU_ 2026 : ICR;
BO_TX_BU_ 760 : ICR;
BO_TX_BU_ 2025 : ICR;
BO_TX_BU_ 670 : ICR;
BO_TX_BU_ 2023 : ICR;
BO_TX_BU_ 1624 : ICR;
BO_TX_BU_ 1470 : IDB;
BO_TX_BU_ 983 : IDB;
BO_TX_BU_ 1429 : OCS1P;
BO_TX_BU_ 767 : OCS1P;
BO_TX_BU_ 766 : OCS1P;
CM_ BO_ 938 "High-voltage processor (pack contactor and isolation controller) message: alert matrix";
CM_ SG_ 938 HVP_matrixIndex "High-voltage processor (pack contactor and isolation controller): matrix index";
CM_ SG_ 938 HVP_w001_WatchdogReset "High-voltage processor (pack contactor and isolation controller): w001 watchdog reset";
CM_ SG_ 938 HVP_w002_UnusedAlert2 "High-voltage processor (pack contactor and isolation controller): w002 unused alert2";
CM_ SG_ 938 HVP_w003_SwAssertion "High-voltage processor (pack contactor and isolation controller): w003 sw assertion";
CM_ SG_ 938 HVP_w004_CrashEvent "High-voltage processor (pack contactor and isolation controller): w004 crash event";
CM_ SG_ 938 HVP_w005_OverDchgCurrentFault "High-voltage processor (pack contactor and isolation controller): w005 over dchg current fault";
CM_ SG_ 938 HVP_w006_OverChargeCurrentFault "High-voltage processor (pack contactor and isolation controller): w006 over charge current fault";
CM_ SG_ 938 HVP_w007_OverCurrentFault "High-voltage processor (pack contactor and isolation controller): w007 over current fault";
CM_ SG_ 938 HVP_w008_OverTemperatureFault "High-voltage processor (pack contactor and isolation controller): w008 over temperature fault";
CM_ SG_ 938 HVP_w009_OverVoltageFault "High-voltage processor (pack contactor and isolation controller): w009 over voltage fault";
CM_ SG_ 938 HVP_w010_UnderVoltageFault "High-voltage processor (pack contactor and isolation controller): w010 under voltage fault";
CM_ SG_ 938 HVP_w011_PrimaryBmbMiaFault "High-voltage processor (pack contactor and isolation controller): w011 primary bmb mia fault";
CM_ SG_ 938 HVP_w012_BmbDataIntegrityLoss "High-voltage processor (pack contactor and isolation controller): w012 bmb data integrity loss";
CM_ SG_ 938 HVP_w013_BmbCommunication "High-voltage processor (pack contactor and isolation controller): w013 bmb communication";
CM_ SG_ 938 HVP_w014_BmsMiaOnHviFault "High-voltage processor (pack contactor and isolation controller): w014 bms mia on hvi fault";
CM_ SG_ 938 HVP_w015_CpMiaFault "High-voltage processor (pack contactor and isolation controller): w015 cp mia fault";
CM_ SG_ 938 HVP_w016_PcsMiaFault "High-voltage processor (pack contactor and isolation controller): w016 pcs mia fault";
CM_ SG_ 938 HVP_w017_GtwMiaFault "High-voltage processor (pack contactor and isolation controller): w017 gtw mia fault";
CM_ SG_ 938 HVP_w018_powerCyclingPcs "High-voltage processor (pack contactor and isolation controller): w018 power cycling pcs";
CM_ SG_ 938 HVP_w019_CpFault "High-voltage processor (pack contactor and isolation controller): w019 cp fault";
CM_ SG_ 938 HVP_w020_ShuntHwMiaFault "High-voltage processor (pack contactor and isolation controller): w020 shunt hw mia fault";
CM_ SG_ 938 HVP_w021_PyroMiaFault "High-voltage processor (pack contactor and isolation controller): w021 pyro mia fault";
CM_ SG_ 938 HVP_w022_PyroMiaWarning "High-voltage processor (pack contactor and isolation controller): w022 pyro mia warning";
CM_ SG_ 938 HVP_w023_BmbResetRecovery "High-voltage processor (pack contactor and isolation controller): w023 bmb reset recovery";
CM_ SG_ 938 HVP_w024_Supply12vFault "High-voltage processor (pack contactor and isolation controller): w024 supply12v fault";
CM_ SG_ 938 HVP_w025_VerSupplyFault "High-voltage processor (pack contactor and isolation controller): w025 ver supply fault";
CM_ SG_ 938 HVP_w026_HvilFault "High-voltage processor (pack contactor and isolation controller): w026 hvil fault";
CM_ SG_ 938 HVP_w027_BmsMiaOnHvsFault "High-voltage processor (pack contactor and isolation controller): w027 bms mia on hvs fault";
CM_ SG_ 938 HVP_w028_PackVoltMismatchFault "High-voltage processor (pack contactor and isolation controller): w028 pack volt mismatch fault";
CM_ SG_ 938 HVP_w029_EnsMiaFault "High-voltage processor (pack contactor and isolation controller): w029 ens mia fault";
CM_ SG_ 938 HVP_w030_PackPosCtrArcFault "High-voltage processor (pack contactor and isolation controller): w030 pack pos ctr arc fault";
CM_ SG_ 938 HVP_w031_packNegCtrArcFault "High-voltage processor (pack contactor and isolation controller): w031 pack neg ctr arc fault";
CM_ SG_ 938 HVP_w032_ShuntHwAndBmsMiaFault "High-voltage processor (pack contactor and isolation controller): w032 shunt hw and bms mia fault";
CM_ SG_ 938 HVP_w033_fcContHwFault "High-voltage processor (pack contactor and isolation controller): w033 fc cont hw fault";
CM_ SG_ 938 HVP_w034_cpMismatchFault "High-voltage processor (pack contactor and isolation controller): w034 cp mismatch fault";
CM_ SG_ 938 HVP_w035_packContHwFault "High-voltage processor (pack contactor and isolation controller): w035 pack cont hw fault";
CM_ SG_ 938 HVP_w036_pyroFuseBlown "High-voltage processor (pack contactor and isolation controller): w036 pyro fuse blown";
CM_ SG_ 938 HVP_w037_pyroFuseFailedToBlow "High-voltage processor (pack contactor and isolation controller): w037 pyro fuse failed to blow";
CM_ SG_ 938 HVP_w038_CpilFault "High-voltage processor (pack contactor and isolation controller): w038 cpil fault";
CM_ SG_ 938 HVP_w039_PackContactorFellOpen "High-voltage processor (pack contactor and isolation controller): w039 pack contactor fell open";
CM_ SG_ 938 HVP_w040_FcContactorFellOpen "High-voltage processor (pack contactor and isolation controller): w040 fc contactor fell open";
CM_ SG_ 938 HVP_w041_packCtrCloseBlocked "High-voltage processor (pack contactor and isolation controller): w041 pack ctr close blocked";
CM_ SG_ 938 HVP_w042_fcCtrCloseBlocked "High-voltage processor (pack contactor and isolation controller): w042 fc ctr close blocked";
CM_ SG_ 938 HVP_w043_packContactorForceOpen "High-voltage processor (pack contactor and isolation controller): w043 pack contactor force open";
CM_ SG_ 938 HVP_w044_fcContactorForceOpen "High-voltage processor (pack contactor and isolation controller): w044 fc contactor force open";
CM_ SG_ 938 HVP_w045_dcLinkOverVoltage "High-voltage processor (pack contactor and isolation controller): w045 dc link over voltage";
CM_ SG_ 938 HVP_w046_shuntOverTemperature "High-voltage processor (pack contactor and isolation controller): w046 shunt over temperature";
CM_ SG_ 938 HVP_w047_passivePyroDeploy "High-voltage processor (pack contactor and isolation controller): w047 passive pyro deploy";
CM_ SG_ 938 HVP_w048_swUnsupportedBmbAsicTyp "High-voltage processor (pack contactor and isolation controller): w048 sw unsupported bmb asic type";
CM_ SG_ 938 HVP_w049_packCtrCloseFailed "High-voltage processor (pack contactor and isolation controller): w049 pack ctr close failed";
CM_ SG_ 938 HVP_w050_fcCtrCloseFailed "High-voltage processor (pack contactor and isolation controller): w050 fc ctr close failed";
CM_ SG_ 938 HVP_w051_shuntThermistorMia "High-voltage processor (pack contactor and isolation controller): w051 shunt thermistor mia";
CM_ SG_ 938 HVP_w052_BmbStatusRegError "High-voltage processor (pack contactor and isolation controller): w052 bmb status reg error";
CM_ SG_ 938 HVP_w053_hvVoltageSensorRational "High-voltage processor (pack contactor and isolation controller): w053 hv voltage sensor rationality";
CM_ SG_ 938 HVP_w054_swMissingConfigBlock "High-voltage processor (pack contactor and isolation controller): w054 sw missing config block";
CM_ SG_ 938 HVP_w055_swMissingPartNumber "High-voltage processor (pack contactor and isolation controller): w055 sw missing part number";
CM_ SG_ 938 HVP_w056_contactorFailedToOpen "High-voltage processor (pack contactor and isolation controller): w056 contactor failed to open";
CM_ SG_ 938 HVP_w057_BatmanDiagnosticsError "High-voltage processor (pack contactor and isolation controller): w057 batman diagnostics error";
CM_ SG_ 938 HVP_w058_BmbVrefBad "High-voltage processor (pack contactor and isolation controller): w058 bmb vref bad";
CM_ SG_ 938 HVP_w059_BmbVrefWarning "High-voltage processor (pack contactor and isolation controller): w059 bmb vref warning";
CM_ SG_ 938 HVP_w060_StackVoltageSense "High-voltage processor (pack contactor and isolation controller): w060 stack voltage sense";
CM_ SG_ 938 HVP_w061_ShuntCurrentRationality "High-voltage processor (pack contactor and isolation controller): w061 shunt current rationality";
CM_ SG_ 938 HVP_w062_BmbOtpConfigError "High-voltage processor (pack contactor and isolation controller): w062 bmb otp config error";
CM_ SG_ 938 HVP_w063_BmbBrickVRationality "High-voltage processor (pack contactor and isolation controller): w063 bmb brick v rationality";
CM_ SG_ 938 HVP_w064_BmbAuxVRationality "High-voltage processor (pack contactor and isolation controller): w064 bmb aux v rationality";
CM_ SG_ 938 HVP_w065_FastOpenVshDetected "High-voltage processor (pack contactor and isolation controller): w065 fast open vsh detected";
CM_ SG_ 938 HVP_w067_HvilCalNodeMismatch "High-voltage processor (pack contactor and isolation controller): w067 hvil cal node mismatch";
CM_ SG_ 938 HVP_w068_shuntUnexpectedThermist "High-voltage processor (pack contactor and isolation controller): w068 shunt unexpected thermistor";
CM_ BO_ 522 "High-voltage processor (pack contactor and isolation controller) message: contactor state";
CM_ SG_ 522 HVP_packContNegativeState "High-voltage processor (pack contactor and isolation controller): pack cont negative state; raw 0 = signal not available (SNA)";
CM_ SG_ 522 HVP_packContPositiveState "Current state of positive pack contactor; raw 0 = signal not available (SNA)";
CM_ SG_ 522 HVP_fcContPositiveAuxOpen "High-voltage processor (pack contactor and isolation controller): fc cont positive aux open";
CM_ SG_ 522 HVP_fcContNegativeAuxOpen "High-voltage processor (pack contactor and isolation controller): fc cont negative aux open";
CM_ SG_ 522 HVP_packContactorSetState "The current state of the pack contactors; raw 0 = signal not available (SNA)";
CM_ SG_ 522 HVP_fcContNegativeState "Current state of the negative FC contactor; raw 0 = signal not available (SNA)";
CM_ SG_ 522 HVP_fcContPositiveState "Current state of the positive FC contactor; raw 0 = signal not available (SNA)";
CM_ SG_ 522 HVP_fcContactorSetState "The current state of the fast charge contactors; raw 0 = signal not available (SNA)";
CM_ SG_ 522 HVP_fcCtrsRequestStatus "Current status of FC contactor request";
CM_ SG_ 522 HVP_fcCtrsResetRequestRequired "High-voltage processor (pack contactor and isolation controller): fc ctrs reset request required";
CM_ SG_ 522 HVP_fcCtrsOpenNowRequested "Flag indicated immediate-opening request of FC contactors";
CM_ SG_ 522 HVP_fcCtrsOpenRequested "Flag indicating opening request of FC contactors";
CM_ SG_ 522 HVP_fcCtrsClosingAllowed "Flag indicating closure allowance of FC contactors";
CM_ SG_ 522 HVP_packCtrsRequestStatus "Current request status of pack contactors";
CM_ SG_ 522 HVP_packCtrsResetRequestRequired "High-voltage processor (pack contactor and isolation controller): pack ctrs reset request required";
CM_ SG_ 522 HVP_packCtrsOpenNowRequested "Flag indicating immediate-opening request of pack contactors";
CM_ SG_ 522 HVP_packCtrsOpenRequested "Flag indicating opening request of pack contactors";
CM_ SG_ 522 HVP_packCtrsClosingAllowed "Flag indicating closure allowance of pack contactors";
CM_ SG_ 522 HVP_dcLinkAllowedToEnergize "Indicates there should be no HV exposure if the FC link is energized by an internal or external source";
CM_ SG_ 522 HVP_pyroTestInProgress "High-voltage processor (pack contactor and isolation controller): pyro test in progress";
CM_ SG_ 522 HVP_hvilDiag "Diagnostic status of HVIL circuit, including specific FAULT types; raw 14 = signal not available (SNA)";
CM_ SG_ 522 HVP_fcLinkAllowedToEnergize "The type of charge that is allowed to energize the FC link. Indicates that the HVP has disabled the dynamic FC weld check for DC charge, or has enabled the PCS charging hardware for AC charge";
CM_ BO_ 1962 "High-voltage processor (pack contactor and isolation controller) message: debug message";
CM_ SG_ 1962 HVP_debugMessageMultiplexer "High-voltage processor (pack contactor and isolation controller): debug message multiplexer";
CM_ SG_ 1962 HVP_gpioPassivePyroDepl "High-voltage processor (pack contactor and isolation controller): gpio passive pyro depl";
CM_ SG_ 1962 HVP_gpioPyroIsoEn "High-voltage processor (pack contactor and isolation controller): gpio pyro iso en";
CM_ SG_ 1962 HVP_gpioCpFaultIn "High-voltage processor (pack contactor and isolation controller): gpio cp fault in";
CM_ SG_ 1962 HVP_gpioPackContPowerEn "High-voltage processor (pack contactor and isolation controller): gpio pack cont power en";
CM_ SG_ 1962 HVP_gpioHvCablesOk "CPIL fault monitoring signal";
CM_ SG_ 1962 HVP_gpioHvpSelfEnable "High-voltage processor (pack contactor and isolation controller): gpio hvp self enable";
CM_ SG_ 1962 HVP_gpioLed "High-voltage processor (pack contactor and isolation controller): gpio led";
CM_ SG_ 1962 HVP_gpioCrashSignal "Crash signal from RCM";
CM_ SG_ 1962 HVP_gpioShuntDataReady "High-voltage processor (pack contactor and isolation controller): gpio shunt data ready";
CM_ SG_ 1962 HVP_gpioFcContPosAux "Aux contact line from positive FC contactor";
CM_ SG_ 1962 HVP_gpioFcContNegAux "Aux contact line from negative FC contactor";
CM_ SG_ 1962 HVP_gpioBmsEout "High-voltage processor (pack contactor and isolation controller): gpio bms eout";
CM_ SG_ 1962 HVP_gpioCpFaultOut "High-voltage processor (pack contactor and isolation controller): gpio cp fault out";
CM_ SG_ 1962 HVP_gpioPyroPor "High-voltage processor (pack contactor and isolation controller): gpio pyro por";
CM_ SG_ 1962 HVP_gpioShuntEn "High-voltage processor (pack contactor and isolation controller): gpio shunt en";
CM_ SG_ 1962 HVP_gpioHvpVerEn "High-voltage processor (pack contactor and isolation controller): gpio hvp ver en";
CM_ SG_ 1962 HVP_gpioFcContFlywheelEnable "High-voltage processor (pack contactor and isolation controller): gpio fc cont flywheel enable";
CM_ SG_ 1962 HVP_gpioCpLatchEnable "High-voltage processor (pack contactor and isolation controller): gpio cp latch enable";
CM_ SG_ 1962 HVP_gpioFcContPowerEnable "High-voltage processor (pack contactor and isolation controller): gpio fc cont power enable";
CM_ SG_ 1962 HVP_gpioHvilEnable "High-voltage processor (pack contactor and isolation controller): gpio hvil enable";
CM_ SG_ 1962 HVP_gpioPortSelSpiRdy "High-voltage processor (pack contactor and isolation controller): gpio port sel spi rdy";
CM_ SG_ 1962 HVP_gpioPyroUnlock "High-voltage processor (pack contactor and isolation controller): gpio pyro unlock";
CM_ SG_ 1962 HVP_hvp1v5Ref "High-voltage processor (pack contactor and isolation controller): hvp1v5 ref";
CM_ SG_ 1962 HVP_packCurrentMia "High-voltage processor (pack contactor and isolation controller): pack current mia";
CM_ SG_ 1962 HVP_auxCurrentMia "High-voltage processor (pack contactor and isolation controller): aux current mia";
CM_ SG_ 1962 HVP_currentSenseMia "High-voltage processor (pack contactor and isolation controller): current sense mia";
CM_ SG_ 1962 HVP_shuntRefVoltageMismatch "High-voltage processor (pack contactor and isolation controller): shunt ref voltage mismatch";
CM_ SG_ 1962 HVP_shuntThermistorMissing "High-voltage processor (pack contactor and isolation controller): shunt thermistor missing";
CM_ SG_ 1962 HVP_shuntThermistorExpected "High-voltage processor (pack contactor and isolation controller): shunt thermistor expected";
CM_ SG_ 1962 HVP_shuntThermistorMia "High-voltage processor (pack contactor and isolation controller): shunt thermistor mia";
CM_ SG_ 1962 HVP_shuntUnexpectedThermistor "High-voltage processor (pack contactor and isolation controller): shunt unexpected thermistor";
CM_ SG_ 1962 HVP_shuntHwMia "High-voltage processor (pack contactor and isolation controller): shunt hw mia";
CM_ SG_ 1962 HVP_shuntCurrentIrrational "High-voltage processor (pack contactor and isolation controller): shunt current irrational";
CM_ SG_ 1962 HVP_shuntAsicTCompActive "High-voltage processor (pack contactor and isolation controller): shunt asic t comp active";
CM_ SG_ 1962 HVP_ecuLogUploadRequest "High-voltage processor (pack contactor and isolation controller): ecu log upload request";
CM_ SG_ 1962 HVP_packContVoltage "High-voltage processor (pack contactor and isolation controller): pack cont voltage";
CM_ SG_ 1962 HVP_packNegativeV "The HVP's common-mode measurement of PACK-HV-SENSE-NEG relative to chassis ground";
CM_ SG_ 1962 HVP_packPositiveV "The HVP's common-mode measurement of PACK-HV-SENSE-POS relative to chassis ground";
CM_ SG_ 1962 HVP_pyroAnalog "High-voltage processor (pack contactor and isolation controller): pyro analog";
CM_ SG_ 1962 HVP_fcContCoilCurrent "High-voltage processor (pack contactor and isolation controller): fc cont coil current";
CM_ SG_ 1962 HVP_fcContVoltage "High-voltage processor (pack contactor and isolation controller): fc cont voltage";
CM_ SG_ 1962 HVP_hvilInVoltage "Measured HVIL input voltage";
CM_ SG_ 1962 HVP_hvilOutVoltage "Measured HVIL output voltage";
CM_ SG_ 1962 HVP_shuntGainInvalidCountDbg "High-voltage processor (pack contactor and isolation controller): shunt gain invalid count dbg";
CM_ SG_ 1962 HVP_fcLinkPositiveV "High-voltage processor (pack contactor and isolation controller): fc link positive v";
CM_ SG_ 1962 HVP_packContCoilCurrent "High-voltage processor (pack contactor and isolation controller): pack cont coil current";
CM_ SG_ 1962 HVP_battery12V "Monitored voltage sense of 12V battery";
CM_ SG_ 1962 HVP_shuntRefVoltageDbg "High-voltage processor (pack contactor and isolation controller): shunt ref voltage dbg";
CM_ BO_ 1666 "High-voltage processor (pack contactor and isolation controller) message: hvp faults";
CM_ SG_ 1666 HVP_packContactorHwFault "High-voltage processor (pack contactor and isolation controller): pack contactor hw fault";
CM_ SG_ 1666 HVP_fcContactorHwFault "High-voltage processor (pack contactor and isolation controller): fc contactor hw fault";
CM_ SG_ 1666 HVP_hvilStatus "High-voltage processor (pack contactor and isolation controller): hvil status";
CM_ BO_ 1553 "High-voltage processor (pack contactor and isolation controller) message: uds response";
CM_ SG_ 1553 HVP_udsResponseData "High-voltage processor (pack contactor and isolation controller): uds response data";
CM_ BO_ 861 "Electric brake booster message: alert matrix";
CM_ SG_ 861 IBST_matrixIndex "Electric brake booster: matrix index";
CM_ SG_ 861 IBST_a001_microSupplyError "Electric brake booster: a001 micro supply error";
CM_ SG_ 861 IBST_a002_HWBISTError "Electric brake booster: a002 HWBIST error";
CM_ SG_ 861 IBST_a003_RAMFault "Electric brake booster: a003 RAM fault";
CM_ SG_ 861 IBST_a004_flashFault "Electric brake booster: a004 flash fault";
CM_ SG_ 861 IBST_a005_microSafetyFault "Electric brake booster: a005 micro safety fault";
CM_ SG_ 861 IBST_a006_microSafetyLogicFault "Electric brake booster: a006 micro safety logic fault";
CM_ SG_ 861 IBST_a007_RBCPUException "Electric brake booster: a007 RBCPU exception";
CM_ SG_ 861 IBST_a008_stackOverUnderFlow "Electric brake booster: a008 stack over under flow";
CM_ SG_ 861 IBST_a009_systemErrorHook "Electric brake booster: a009 system error hook";
CM_ SG_ 861 IBST_a010_OSErrorHook "Electric brake booster: a010 OS error hook";
CM_ SG_ 861 IBST_a011_systemTaskOverRun "Electric brake booster: a011 system task over run";
CM_ SG_ 861 IBST_a012_OSTaskSchemeError "Electric brake booster: a012 OS task scheme error";
CM_ SG_ 861 IBST_a013_systemTaskJitter "Electric brake booster: a013 system task jitter";
CM_ SG_ 861 IBST_a014_DMATransferError "Electric brake booster: a014 DMA transfer error";
CM_ SG_ 861 IBST_a015_asicOscillatorError "Electric brake booster: a015 asic oscillator error";
CM_ SG_ 861 IBST_a016_RBBLMShaftShiftError "Electric brake booster: a016 RBBLM shaft shift error";
CM_ SG_ 861 IBST_a017_assertionFault "Electric brake booster: a017 assertion fault";
CM_ SG_ 861 IBST_a018_unsupportedHW "Electric brake booster: a018 unsupported HW";
CM_ SG_ 861 IBST_a019_supplyASICInitFault "Electric brake booster: a019 supply ASIC init fault";
CM_ SG_ 861 IBST_a020_VPREU5VOutOfRange "Electric brake booster: a020 VPREU5 v out of range";
CM_ SG_ 861 IBST_a021_IREFOutOfRange "Electric brake booster: a021 IREF out of range";
CM_ SG_ 861 IBST_a022_U5VTestFault "Electric brake booster: a022 U5 v test fault";
CM_ SG_ 861 IBST_a023_U5VOutOfRange "Electric brake booster: a023 U5 v out of range";
CM_ SG_ 861 IBST_a024_chargePumpFault "Electric brake booster: a024 charge pump fault";
CM_ SG_ 861 IBST_a025_ecuClockTestFault "Electric brake booster: a025 ecu clock test fault";
CM_ SG_ 861 IBST_a026_ecuBistCmdTestFault "Electric brake booster: a026 ecu bist cmd test fault";
CM_ SG_ 861 IBST_a027_ecuFastWdTestFault "Electric brake booster: a027 ecu fast wd test fault";
CM_ SG_ 861 IBST_a028_ecuBistFaultCtrFault "Electric brake booster: a028 ecu bist fault ctr fault";
CM_ SG_ 861 IBST_a029_ecuErrpinCounterFault "Electric brake booster: a029 ecu errpin counter fault";
CM_ SG_ 861 IBST_a030_ecuEnableElLowFault "Electric brake booster: a030 ecu enable el low fault";
CM_ SG_ 861 IBST_a031_decoupleBitTestFault "Electric brake booster: a031 decouple bit test fault";
CM_ SG_ 861 IBST_a032_ecuEnableElHighFault "Electric brake booster: a032 ecu enable el high fault";
CM_ SG_ 861 IBST_a033_ecuWdStartuptestFault "Electric brake booster: a033 ecu wd startuptest fault";
CM_ SG_ 861 IBST_a034_ecuEnableHyHighFault "Electric brake booster: a034 ecu enable hy high fault";
CM_ SG_ 861 IBST_a035_ecuEnableHyLowFault "Electric brake booster: a035 ecu enable hy low fault";
CM_ SG_ 861 IBST_a036_MRGPathTestFault "Electric brake booster: a036 MRG path test fault";
CM_ SG_ 861 IBST_a037_ecuWdSContinuousError "Electric brake booster: a037 ecu wd s continuous error";
CM_ SG_ 861 IBST_a038_ecuEnContinuousError "Electric brake booster: a038 ecu en continuous error";
CM_ SG_ 861 IBST_a039_GTMRefFrequencyError "Electric brake booster: a039 GTM ref frequency error";
CM_ SG_ 861 IBST_a040_GTMTbuMonError "Electric brake booster: a040 GTM tbu mon error";
CM_ SG_ 861 IBST_a041_micAsicClkInError "Electric brake booster: a041 mic asic clk in error";
CM_ SG_ 861 IBST_a042_micAsicInitTestError "Electric brake booster: a042 mic asic init test error";
CM_ SG_ 861 IBST_a043_micSpiTransferError "Electric brake booster: a043 mic spi transfer error";
CM_ SG_ 861 IBST_a044_NvMEepromWIP "Electric brake booster: a044 nv m eeprom WIP";
CM_ SG_ 861 IBST_a045_WdhAsicWdErrorCntStuck "Electric brake booster: a045 wdh asic wd error cnt stuck";
CM_ SG_ 861 IBST_a046_WdhAsicWdErrorCntLimit "Electric brake booster: a046 wdh asic wd error cnt limit";
CM_ SG_ 861 IBST_a047_WdhAsicWdCmdMissing "Electric brake booster: a047 wdh asic wd cmd missing";
CM_ SG_ 861 IBST_a048_WdhSwBistConCnt "Electric brake booster: a048 wdh sw bist con cnt";
CM_ SG_ 861 IBST_a049_WdhTaskMonConCnt "Electric brake booster: a049 wdh task mon con cnt";
CM_ SG_ 861 IBST_a050_VPreExternalFeeding "Electric brake booster: a050 v pre external feeding";
CM_ SG_ 861 IBST_a051_ecuBandgap "Electric brake booster: a051 ecu bandgap";
CM_ SG_ 861 IBST_a052_AdcPinTest "Electric brake booster: a052 adc pin test";
CM_ SG_ 861 IBST_a053_AdcSelftestC5P "Electric brake booster: a053 adc selftest C5 p";
CM_ SG_ 861 IBST_a054_AdcPeripheralFault "Electric brake booster: a054 adc peripheral fault";
CM_ SG_ 861 IBST_a055_UB6SupplyPathFault "Electric brake booster: a055 UB6 supply path fault";
CM_ SG_ 861 IBST_a056_UB6PlausiMonFault "Electric brake booster: a056 UB6 plausi mon fault";
CM_ SG_ 861 IBST_a057_microRegisterFault "Electric brake booster: a057 micro register fault";
CM_ SG_ 861 IBST_a058_NvMWriteCycleExceed "Electric brake booster: a058 nv m write cycle exceed";
CM_ SG_ 861 IBST_a059_NvMEepromSize "Electric brake booster: a059 nv m eeprom size";
CM_ SG_ 861 IBST_a060_NvMMigrationFault "Electric brake booster: a060 nv m migration fault";
CM_ SG_ 861 IBST_a061_AswSystemTimeOut "Electric brake booster: a061 asw system time out";
CM_ SG_ 861 IBST_a062_MICB6TransferError "Electric brake booster: a062 MICB6 transfer error";
CM_ SG_ 861 IBST_a063_tempSens2ShortToSupply "Electric brake booster: a063 temp sens2 short to supply";
CM_ SG_ 861 IBST_a064_tempSens1ShortToGround "Electric brake booster: a064 temp sens1 short to ground";
CM_ SG_ 861 IBST_a065_tempSens2ShortToGround "Electric brake booster: a065 temp sens2 short to ground";
CM_ SG_ 861 IBST_a066_tempSens1ShortToSupply "Electric brake booster: a066 temp sens1 short to supply";
CM_ SG_ 861 IBST_a067_tempSensImplausVoltage "Electric brake booster: a067 temp sens implaus voltage";
CM_ SG_ 861 IBST_a068_chargePumpUndervoltage "Electric brake booster: a068 charge pump undervoltage";
CM_ SG_ 861 IBST_a069_greasingRoutineFault "Electric brake booster: a069 greasing routine fault";
CM_ SG_ 861 IBST_a070_notShutDownNvMWrite "Electric brake booster: a070 not shut down nv m write";
CM_ SG_ 861 IBST_a071_notShutDownNvMRead "Electric brake booster: a071 not shut down nv m read";
CM_ SG_ 861 IBST_a072_notShutDownRight "Electric brake booster: a072 not shut down right";
CM_ SG_ 861 IBST_a073_jumpInAdjustNvMRead "Electric brake booster: a073 jump in adjust nv m read";
CM_ SG_ 861 IBST_a074_FindIdleDataNvMWrite "Electric brake booster: a074 find idle data nv m write";
CM_ SG_ 861 IBST_a075_FindIdleRoutineFault "Electric brake booster: a075 find idle routine fault";
CM_ SG_ 861 IBST_a076_masterCylLengthRead "Electric brake booster: a076 master cyl length read";
CM_ SG_ 861 IBST_a077_runOutMotorSaturated "Electric brake booster: a077 run out motor saturated";
CM_ SG_ 861 IBST_a078_wearOffsetCompNVMRead "Electric brake booster: a078 wear offset comp NVM read";
CM_ SG_ 861 IBST_a079_motorTempHighLevel1 "Electric brake booster: a079 motor temp high level1";
CM_ SG_ 861 IBST_a080_motorTempHighLevel2 "Electric brake booster: a080 motor temp high level2";
CM_ SG_ 861 IBST_a081_travelDeviation "Electric brake booster: a081 travel deviation";
CM_ SG_ 861 IBST_a082_motorSpeedDeviation "Electric brake booster: a082 motor speed deviation";
CM_ SG_ 861 IBST_a083_spindlePositionTooHigh "Electric brake booster: a083 spindle position too high";
CM_ SG_ 861 IBST_a084_CANTransceiverHWFault "Electric brake booster: a084 CAN transceiver HW fault";
CM_ SG_ 861 IBST_a085_supplyUndervoltageLvl3 "Electric brake booster: a085 supply undervoltage lvl3";
CM_ SG_ 861 IBST_a086_supplyOvervoltageLvl3 "Electric brake booster: a086 supply overvoltage lvl3";
CM_ SG_ 861 IBST_a087_rotorSinOutOfRangeLow "Electric brake booster: a087 rotor sin out of range low";
CM_ SG_ 861 IBST_a088_rotorCosOutOfRangeLow "Electric brake booster: a088 rotor cos out of range low";
CM_ SG_ 861 IBST_a089_rotorSinOutOfRangeHigh "Electric brake booster: a089 rotor sin out of range high";
CM_ SG_ 861 IBST_a090_rotorCosOutOfRangeHigh "Electric brake booster: a090 rotor cos out of range high";
CM_ SG_ 861 IBST_a091_SMMOneRequestsInit "Electric brake booster: a091 SMM one requests init";
CM_ SG_ 861 IBST_a092_systemStartTimeOut "Electric brake booster: a092 system start time out";
CM_ SG_ 861 IBST_a093_UEXSOvertemperature "Electric brake booster: a093 UEXS overtemperature";
CM_ SG_ 861 IBST_a094_XPASSEchoTimeDeviation "Electric brake booster: a094 XPASS echo time deviation";
CM_ SG_ 861 IBST_a095_XPASSTimeOut "Electric brake booster: a095 XPASS time out";
CM_ SG_ 861 IBST_a096_bridgeDriverMonError "Electric brake booster: a096 bridge driver mon error";
CM_ SG_ 861 IBST_a097_bridgeDriverError "Electric brake booster: a097 bridge driver error";
CM_ SG_ 861 IBST_a098_bridgeShortedPhase "Electric brake booster: a098 bridge shorted phase";
CM_ SG_ 861 IBST_a099_bridgeSwitchInitError "Electric brake booster: a099 bridge switch init error";
CM_ SG_ 861 IBST_a100_current2OffsetHigh "Electric brake booster: a100 current2 offset high";
CM_ SG_ 861 IBST_a101_current2OffsetLow "Electric brake booster: a101 current2 offset low";
CM_ SG_ 861 IBST_a102_current1OffsetHigh "Electric brake booster: a102 current1 offset high";
CM_ SG_ 861 IBST_a103_current1OffsetLow "Electric brake booster: a103 current1 offset low";
CM_ SG_ 861 IBST_a104_bridgeDriverShort "Electric brake booster: a104 bridge driver short";
CM_ SG_ 861 IBST_a105_LiPSUndervoltage "Electric brake booster: a105 li PS undervoltage";
CM_ SG_ 861 IBST_a106_LiPS5VSupply "Electric brake booster: a106 li PS5 v supply";
CM_ SG_ 861 IBST_a107_LiPS2PwmLineHigh "Electric brake booster: a107 li PS2 pwm line high";
CM_ SG_ 861 IBST_a108_LiPS2PwmLineLow "Electric brake booster: a108 li PS2 pwm line low";
CM_ SG_ 861 IBST_a109_LiPS2PwmTransmission "Electric brake booster: a109 li PS2 pwm transmission";
CM_ SG_ 861 IBST_a110_LiPS1SentLineHigh "Electric brake booster: a110 li PS1 sent line high";
CM_ SG_ 861 IBST_a111_LiPS1SentLineLow "Electric brake booster: a111 li PS1 sent line low";
CM_ SG_ 861 IBST_a112_LiPS1SentTransmission "Electric brake booster: a112 li PS1 sent transmission";
CM_ SG_ 861 IBST_a113_LiPS1SentSensor "Electric brake booster: a113 li PS1 sent sensor";
CM_ SG_ 861 IBST_a114_partyBusOff "Electric brake booster: a114 party bus off";
CM_ SG_ 861 IBST_a115_chassisBusOff "Electric brake booster: a115 chassis bus off";
CM_ SG_ 861 IBST_a116_supplyUndervoltageLvl2 "Electric brake booster: a116 supply undervoltage lvl2";
CM_ SG_ 861 IBST_a117_supplyOvervoltageLvl2 "Electric brake booster: a117 supply overvoltage lvl2";
CM_ SG_ 861 IBST_a118_RPSNvMReadFault "Electric brake booster: a118 RPS nv m read fault";
CM_ SG_ 861 IBST_a119_RPSWrongCalibData "Electric brake booster: a119 RPS wrong calib data";
CM_ SG_ 861 IBST_a120_RPSVectorRangeHigh "Electric brake booster: a120 RPS vector range high";
CM_ SG_ 861 IBST_a121_RPSVectorRangeLow "Electric brake booster: a121 RPS vector range low";
CM_ SG_ 861 IBST_a122_RPSVectorOscillating "Electric brake booster: a122 RPS vector oscillating";
CM_ SG_ 861 IBST_a123_bridgeDriverUnavail "Electric brake booster: a123 bridge driver unavail";
CM_ SG_ 861 IBST_a124_OBDCurrent1OORHigh "Electric brake booster: a124 OBD current1 OOR high";
CM_ SG_ 861 IBST_a125_OBDCurrent2OORHigh "Electric brake booster: a125 OBD current2 OOR high";
CM_ SG_ 861 IBST_a126_OBDCurrent1OORLow "Electric brake booster: a126 OBD current1 OOR low";
CM_ SG_ 861 IBST_a127_OBDCurrent2OORLow "Electric brake booster: a127 OBD current2 OOR low";
CM_ SG_ 861 IBST_a128_BLMMuxerTimeoutError "Electric brake booster: a128 BLM muxer timeout error";
CM_ SG_ 861 IBST_a129_loadDumpOnFSLTest "Electric brake booster: a129 load dump on FSL test";
CM_ SG_ 861 IBST_a130_DTSFunctionalRangeLow "Electric brake booster: a130 DTS functional range low";
CM_ SG_ 861 IBST_a131_DTSFunctionalRangeHigh "Electric brake booster: a131 DTS functional range high";
CM_ SG_ 861 IBST_a132_DTSPlausiCheck1vs2 "Electric brake booster: a132 DTS plausi check1vs2";
CM_ SG_ 861 IBST_a133_DTSOffsetTooLow "Electric brake booster: a133 DTS offset too low";
CM_ SG_ 861 IBST_a134_DTSOffsetTooHigh "Electric brake booster: a134 DTS offset too high";
CM_ SG_ 861 IBST_a135_ESPparty1DLC "Electric brake booster: a135 ES pparty1 DLC";
CM_ SG_ 861 IBST_a136_ESPparty1Timeout "Electric brake booster: a136 ES pparty1 timeout";
CM_ SG_ 861 IBST_a137_ESPparty1Checksum "Electric brake booster: a137 ES pparty1 checksum";
CM_ SG_ 861 IBST_a138_ESPparty1Counter "Electric brake booster: a138 ES pparty1 counter";
CM_ SG_ 861 IBST_a139_ESPparty2DLC "Electric brake booster: a139 ES pparty2 DLC";
CM_ SG_ 861 IBST_a140_ESPparty2Timeout "Electric brake booster: a140 ES pparty2 timeout";
CM_ SG_ 861 IBST_a141_ESPparty2Checksum "Electric brake booster: a141 ES pparty2 checksum";
CM_ SG_ 861 IBST_a142_ESPparty2Counter "Electric brake booster: a142 ES pparty2 counter";
CM_ SG_ 861 IBST_a143_ESPparty3DLC "Electric brake booster: a143 ES pparty3 DLC";
CM_ SG_ 861 IBST_a144_ESPparty3Timeout "Electric brake booster: a144 ES pparty3 timeout";
CM_ SG_ 861 IBST_a145_ESPparty3Checksum "Electric brake booster: a145 ES pparty3 checksum";
CM_ SG_ 861 IBST_a146_ESPparty3Counter "Electric brake booster: a146 ES pparty3 counter";
CM_ SG_ 861 IBST_a147_PSCMotorSizeReadFault "Electric brake booster: a147 PSC motor size read fault";
CM_ SG_ 861 IBST_a148_MLIGainMechReadFault "Electric brake booster: a148 MLI gain mech read fault";
CM_ SG_ 861 IBST_a149_MLITMCAreaReadFault "Electric brake booster: a149 MLITMC area read fault";
CM_ SG_ 861 IBST_a150_motorTestFault "Electric brake booster: a150 motor test fault";
CM_ SG_ 861 IBST_a151_PSCGearRatioReadFault "Electric brake booster: a151 PSC gear ratio read fault";
CM_ SG_ 861 IBST_a152_PSCVoltageImplausible "Electric brake booster: a152 PSC voltage implausible";
CM_ SG_ 861 IBST_a153_unused "Electric brake booster: a153 unused";
CM_ SG_ 861 IBST_a154_unused "Electric brake booster: a154 unused";
CM_ SG_ 861 IBST_a155_supplyUndervoltageLvl1 "Electric brake booster: a155 supply undervoltage lvl1";
CM_ SG_ 861 IBST_a156_supplyOvervoltageLvl1 "Electric brake booster: a156 supply overvoltage lvl1";
CM_ SG_ 861 IBST_a157_masterCylPressInvalid "Electric brake booster: a157 master cyl press invalid";
CM_ SG_ 861 IBST_a158_DTSOffsHighSuspicious "Electric brake booster: a158 DTS offs high suspicious";
CM_ SG_ 861 IBST_a159_FindIdleNvMReadError "Electric brake booster: a159 find idle nv m read error";
CM_ SG_ 861 IBST_a160_DTSIDTimeOut "Electric brake booster: a160 DTSID time out";
CM_ SG_ 861 IBST_a161_powerPackMismatch "Electric brake booster: a161 power pack mismatch";
CM_ SG_ 861 IBST_a162_idlePosNotDetected "Electric brake booster: a162 idle pos not detected";
CM_ SG_ 861 IBST_a163_ESPpEstMaxInvalid "Electric brake booster: a163 ES pp est max invalid";
CM_ SG_ 861 IBST_a164_ESPVehicleSpeedInvalid "Electric brake booster: a164 ESP vehicle speed invalid";
CM_ SG_ 861 IBST_a165_ESPpForceBlendInvalid "Electric brake booster: a165 ES pp force blend invalid";
CM_ SG_ 861 IBST_a166_ESPpMcVirtualInvalid "Electric brake booster: a166 ES pp mc virtual invalid";
CM_ SG_ 861 IBST_a167_ESPqTargetExterInvalid "Electric brake booster: a167 ES pq target exter invalid";
CM_ SG_ 861 IBST_a168_CANOvervoltage "Electric brake booster: a168 CAN overvoltage";
CM_ SG_ 861 IBST_a169_CANUndervoltage "Electric brake booster: a169 CAN undervoltage";
CM_ SG_ 861 IBST_a170_LVPowerStateTimeout "Electric brake booster: a170 LV power state timeout";
CM_ SG_ 861 IBST_a171_LVPowerStateChecksum "Electric brake booster: a171 LV power state checksum";
CM_ SG_ 861 IBST_a172_LVPowerStateDLC "Electric brake booster: a172 LV power state DLC";
CM_ SG_ 861 IBST_a173_LVPowerStateCounter "Electric brake booster: a173 LV power state counter";
CM_ SG_ 861 IBST_a174_LVOffStateInvalid "Electric brake booster: a174 LV off state invalid";
CM_ SG_ 861 IBST_a175_LVGoingDownInvalid "Electric brake booster: a175 LV going down invalid";
CM_ SG_ 861 IBST_a176_blockedPedalDetected "Electric brake booster: a176 blocked pedal detected";
CM_ SG_ 861 IBST_a177_EPBLsystemStatusMIA "Electric brake booster: a177 EPB lsystem status MIA";
CM_ SG_ 861 IBST_a178_EPBRsystemStatusMIA "Electric brake booster: a178 EPB rsystem status MIA";
CM_ SG_ 861 IBST_a179_VCLEFTepbmStatusMIA "Electric brake booster: a179 VCLEF tepbm status MIA";
CM_ SG_ 861 IBST_a180_VCRIGHTepbmStatusMIA "Electric brake booster: a180 VCRIGH tepbm status MIA";
CM_ SG_ 861 IBST_a181_DIchassisControlDLC "Electric brake booster: a181 d ichassis control DLC";
CM_ SG_ 861 IBST_a182_DIchassisControlTimeou "Electric brake booster: a182 d ichassis control timeout";
CM_ SG_ 861 IBST_a183_DIchassisControlChecks "Electric brake booster: a183 d ichassis control checksum";
CM_ SG_ 861 IBST_a184_DIchassisControlCounte "Electric brake booster: a184 d ichassis control counter";
CM_ SG_ 861 IBST_a185_rightBusOff "Electric brake booster: a185 right bus off";
CM_ SG_ 861 IBST_a186_rightBusPassive "Electric brake booster: a186 right bus passive";
CM_ SG_ 861 IBST_a187_brakeBusOff "Electric brake booster: a187 brake bus off";
CM_ SG_ 861 IBST_a188_brakeBusPassive "Electric brake booster: a188 brake bus passive";
CM_ SG_ 861 IBST_a189_rightVCLVPowerStateTim "Electric brake booster: a189 right VCLV power state timeout";
CM_ SG_ 861 IBST_a190_rightVCLVPowerStateDLC "Electric brake booster: a190 right VCLV power state DLC";
CM_ SG_ 861 IBST_a191_rightVCLVPowerStateChe "Electric brake booster: a191 right VCLV power state checksum";
CM_ SG_ 861 IBST_a192_rightVCLVPowerStateCou "Electric brake booster: a192 right VCLV power state counter";
CM_ SG_ 861 IBST_a193_leftVCLVPowerStateTime "Electric brake booster: a193 left VCLV power state timeout";
CM_ SG_ 861 IBST_a194_leftVCLVPowerStateChec "Electric brake booster: a194 left VCLV power state checksum";
CM_ SG_ 861 IBST_a195_leftVCLVPowerStateDLC "Electric brake booster: a195 left VCLV power state DLC";
CM_ SG_ 861 IBST_a196_leftVCLVPowerStateCoun "Electric brake booster: a196 left VCLV power state counter";
CM_ SG_ 861 IBST_a197_brakeLatencyReductionA "Electric brake booster: a197 brake latency reduction active";
CM_ SG_ 861 IBST_a198_aesActive "Electric brake booster: a198 aes active";
CM_ SG_ 861 IBST_a199_undefinedAlertDetected "Electric brake booster: a199 undefined alert detected";
CM_ SG_ 861 IBST_a200_aesFault "Electric brake booster: a200 aes fault";
CM_ SG_ 861 IBST_a201_EGGREAR1wheelSpeedsRea "Electric brake booster: a201 eggrear1wheel speeds rear time out";
CM_ SG_ 861 IBST_a202_EGGREAR1wheelSpeedsRea "Electric brake booster: a202 eggrear1wheel speeds rear checksum";
CM_ SG_ 861 IBST_a203_EGGREAR1wheelSpeedsRea "Electric brake booster: a203 eggrear1wheel speeds rear DLC";
CM_ SG_ 861 IBST_a204_EGGREAR1wheelSpeedsRea "Electric brake booster: a204 eggrear1wheel speeds rear counter";
CM_ SG_ 861 IBST_a205_EGGRIGHT1wheelSpeedsFr "Electric brake booster: a205 eggright1wheel speeds front time out";
CM_ SG_ 861 IBST_a206_EGGRIGHT1wheelSpeedsFr "Electric brake booster: a206 eggright1wheel speeds front checksum";
CM_ SG_ 861 IBST_a207_EGGRIGHT1wheelSpeedsFr "Electric brake booster: a207 eggright1wheel speeds front DLC";
CM_ SG_ 861 IBST_a208_EGGRIGHT1wheelSpeedsFr "Electric brake booster: a208 eggright1wheel speeds front counter";
CM_ SG_ 861 IBST_a209_reducedBrakePowerActiv "Electric brake booster: a209 reduced brake power active";
CM_ SG_ 861 IBST_a210_reducedBrakePowerNotAv "Electric brake booster: a210 reduced brake power not available";
CM_ SG_ 861 IBST_a211_DETReportError "Electric brake booster: a211 DET report error";
CM_ SG_ 861 IBST_a212_infoFailureWrongCUBASH "Electric brake booster: a212 info failure wrong CUBAS handling detected";
CM_ SG_ 861 IBST_a213_PDURouterinitializatio "Electric brake booster: a213 PDU routerinitialization failed";
CM_ SG_ 861 IBST_a214_LossOfPDUInstanceDetec "Electric brake booster: a214 loss of PDU instance detected";
CM_ SG_ 861 IBST_a215_UnsupportedSeriesHWDet "Electric brake booster: a215 unsupported series HW detected";
CM_ SG_ 861 IBST_a216_AsicMalfunctionDetecte "Electric brake booster: a216 asic malfunction detected";
CM_ SG_ 861 IBST_a217_AsicTrimmingNotComplet "Electric brake booster: a217 asic trimming not completed";
CM_ SG_ 861 IBST_a218_uCSafetyNotificationGR "Electric brake booster: a218 u c safety notification GRAM";
CM_ SG_ 861 IBST_a219_uCSafetyNotification "Electric brake booster: a219 u c safety notification";
CM_ SG_ 861 IBST_a220_ASICOvercurrentOnGPIO2 "Electric brake booster: a220 ASIC overcurrent on GPIO250 2";
CM_ SG_ 861 IBST_a221_ASICOvercurrentOnGPIO2 "Electric brake booster: a221 ASIC overcurrent on GPIO250 1";
CM_ SG_ 861 IBST_a222_ASICOvercurrentOnGPIO5 "Electric brake booster: a222 ASIC overcurrent on GPIO50 4";
CM_ SG_ 861 IBST_a223_ASICOvercurrentOnGPIO5 "Electric brake booster: a223 ASIC overcurrent on GPIO50 3";
CM_ SG_ 861 IBST_a224_ASICOvercurrentOnGPIO5 "Electric brake booster: a224 ASIC overcurrent on GPIO50 2";
CM_ SG_ 861 IBST_a225_ASICOvercurrentOnGPIO5 "Electric brake booster: a225 ASIC overcurrent on GPIO50 1";
CM_ SG_ 861 IBST_a226_ASICOvercurrentOnWRHS "Electric brake booster: a226 ASIC overcurrent on WRHS";
CM_ SG_ 861 IBST_a227_wakeRequestMismatchDet "Electric brake booster: a227 wake request mismatch detected";
CM_ SG_ 861 IBST_a228_BlockedPedalDetectedDu "Electric brake booster: a228 blocked pedal detected during HAD";
CM_ SG_ 861 IBST_a229_BlockedPedalDetected "Electric brake booster: a229 blocked pedal detected";
CM_ SG_ 861 IBST_a230_DTS2FunctionalRangeLow "Electric brake booster: a230 DTS2 functional range low";
CM_ SG_ 861 IBST_a231_DTS2FunctionalRangeLow "Electric brake booster: a231 DTS2 functional range low";
CM_ SG_ 861 IBST_a232_PostAssemblyRoutineFai "Electric brake booster: a232 post assembly routine failed";
CM_ SG_ 861 IBST_a233_ReferenceRunAbortByECU "Electric brake booster: a233 reference run abort by ECU reset";
CM_ SG_ 861 IBST_a234_LiPSOutOfRangeHigh "Electric brake booster: a234 li PS out of range high";
CM_ SG_ 861 IBST_a235_LiPSOutOfRangeLow "Electric brake booster: a235 li PS out of range low";
CM_ BO_ 1629 "Electric brake booster message: uds response";
CM_ SG_ 1629 IBST_udsResponseData "Electric brake booster: uds response data";
CM_ BO_ 1208 "ICR ECU message: alert log";
CM_ SG_ 1208 ICR_alertID "ICR ECU: alert ID";
CM_ SG_ 1208 ICR_alertState "ICR ECU: alert state";
CM_ SG_ 1208 ICR_a001_watchdogTaskAppDPM "ICR ECU: a001 watchdog task app DPM";
CM_ SG_ 1208 ICR_a001_watchdogTaskMMWControl "ICR ECU: a001 watchdog task MMW control";
CM_ SG_ 1208 ICR_a001_watchdogTaskSentinelInt "ICR ECU: a001 watchdog task sentinel interface";
CM_ SG_ 1208 ICR_a001_watchdogTaskSentinelMod "ICR ECU: a001 watchdog task sentinel mode change";
CM_ SG_ 1208 ICR_a001_watchdogTaskComTXRAD "ICR ECU: a001 watchdog task com TXRAD";
CM_ SG_ 1208 ICR_a001_watchdogTaskComRX "ICR ECU: a001 watchdog task com RX";
CM_ SG_ 1208 ICR_a001_watchdogTaskComTXVEH "ICR ECU: a001 watchdog task com TXVEH";
CM_ SG_ 1208 ICR_a001_watchdogTaskComUDS "ICR ECU: a001 watchdog task com UDS";
CM_ SG_ 1208 ICR_a001_watchdogTaskCommonError "ICR ECU: a001 watchdog task common error";
CM_ SG_ 1208 ICR_a001_watchdogTaskUARTLog "ICR ECU: a001 watchdog task UART log";
CM_ SG_ 1208 ICR_a001_watchdogTaskDataDump "ICR ECU: a001 watchdog task data dump";
CM_ SG_ 1208 ICR_a001_watchdogRTOSAppRun10MS "ICR ECU: a001 watchdog RTOS app run10 MS";
CM_ SG_ 1208 ICR_a001_watchdogRTOSAppRun1MS "ICR ECU: a001 watchdog RTOS app run1 MS";
CM_ SG_ 1208 ICR_a001_InternalWatchdog "ICR ECU: a001 internal watchdog";
CM_ SG_ 1208 ICR_a002_CPUUndervoltage "ICR ECU: a002 CPU undervoltage";
CM_ SG_ 1208 ICR_a002_PowerOnReset "ICR ECU: a002 power on reset";
CM_ SG_ 1208 ICR_a015_NVMMMemOverflow "ICR ECU: a015 NVMM mem overflow";
CM_ SG_ 1208 ICR_a015_NVMMFilesystemError "ICR ECU: a015 NVMM filesystem error";
CM_ SG_ 1208 ICR_a015_NVMMRecordIDError "ICR ECU: a015 NVMM record ID error";
CM_ SG_ 1208 ICR_a059_voltageDrop "ICR ECU: a059 voltage drop";
CM_ SG_ 1208 ICR_a059_resistanceEstimate "ICR ECU: a059 resistance estimate";
CM_ SG_ 1208 ICR_a059_current "ICR ECU: a059 current";
CM_ SG_ 1208 ICR_a063_switchChannel "ICR ECU: a063 switch channel";
CM_ SG_ 1208 ICR_a063_switchType "ICR ECU: a063 switch type";
CM_ SG_ 1208 ICR_a063_ADCVoltage "ICR ECU: a063 ADC voltage";
CM_ SG_ 1208 ICR_a063_disconnected "ICR ECU: a063 disconnected";
CM_ SG_ 1208 ICR_a063_indeterminate "ICR ECU: a063 indeterminate";
CM_ SG_ 1208 ICR_a063_stuckActive "ICR ECU: a063 stuck active";
CM_ SG_ 1208 ICR_a063_faulted "ICR ECU: a063 faulted";
CM_ SG_ 1208 ICR_a133_nearClutter "ICR ECU: a133 near clutter";
CM_ SG_ 1208 ICR_a133_farClutter "ICR ECU: a133 far clutter";
CM_ SG_ 1208 ICR_a137_nearClutter "ICR ECU: a137 near clutter";
CM_ SG_ 1208 ICR_a137_farClutter "ICR ECU: a137 far clutter";
CM_ SG_ 1208 ICR_a139_nearClutter "ICR ECU: a139 near clutter";
CM_ SG_ 1208 ICR_a139_farClutter "ICR ECU: a139 far clutter";
CM_ BO_ 2026 "ICR ECU message: alert matrix";
CM_ SG_ 2026 ICR_matrixIndex "ICR ECU: matrix index";
CM_ SG_ 2026 ICR_a001_WatchdogReset "ICR ECU: a001 watchdog reset";
CM_ SG_ 2026 ICR_a002_PowerLossReset "ICR ECU: a002 power loss reset";
CM_ SG_ 2026 ICR_a003_SWAssertion "ICR ECU: a003 SW assertion";
CM_ SG_ 2026 ICR_a005_CANTXError "ICR ECU: a005 CANTX error";
CM_ SG_ 2026 ICR_a006_CANTX_cyclicError "ICR ECU: a006 CANTX cyclic error";
CM_ SG_ 2026 ICR_a012_CPUReset "ICR ECU: a012 CPU reset";
CM_ SG_ 2026 ICR_a013_AlertManagerFault "ICR ECU: a013 alert manager fault";
CM_ SG_ 2026 ICR_a015_NVMMError "ICR ECU: a015 NVMM error";
CM_ SG_ 2026 ICR_a016_NVMMRecordError "ICR ECU: a016 NVMM record error";
CM_ SG_ 2026 ICR_a021_TaskSchedulerError "ICR ECU: a021 task scheduler error";
CM_ SG_ 2026 ICR_a022_TaskInitError "ICR ECU: a022 task init error";
CM_ SG_ 2026 ICR_a029_CoreDump "ICR ECU: a029 core dump";
CM_ SG_ 2026 ICR_a030_ECULogUploadRequest "ICR ECU: a030 ECU log upload request";
CM_ SG_ 2026 ICR_a031_UDSActive "ICR ECU: a031 UDS active";
CM_ SG_ 2026 ICR_a041_HighCPULoad "ICR ECU: a041 high CPU load";
CM_ SG_ 2026 ICR_a042_HighStackUsage "ICR ECU: a042 high stack usage";
CM_ SG_ 2026 ICR_a043_Task1msError "ICR ECU: a043 task1ms error";
CM_ SG_ 2026 ICR_a044_Task10msError "ICR ECU: a044 task10ms error";
CM_ SG_ 2026 ICR_a045_Task100msError "ICR ECU: a045 task100ms error";
CM_ SG_ 2026 ICR_a046_Task1000msError "ICR ECU: a046 task1000ms error";
CM_ SG_ 2026 ICR_a058_inputRHighSyncDebug "ICR ECU: a058 input r high sync debug";
CM_ SG_ 2026 ICR_a059_inputResistanceHigh "ICR ECU: a059 input resistance high";
CM_ SG_ 2026 ICR_a060_engineeringBuild "ICR ECU: a060 engineering build";
CM_ SG_ 2026 ICR_a061_XCPConnected "ICR ECU: a061 XCP connected";
CM_ SG_ 2026 ICR_a062_XCPWasConnected "ICR ECU: a062 XCP was connected";
CM_ SG_ 2026 ICR_a063_SwitchFault "ICR ECU: a063 switch fault";
CM_ SG_ 2026 ICR_a064_busSleepReqTimeout "ICR ECU: a064 bus sleep req timeout";
CM_ SG_ 2026 ICR_a133_radarBlocked "ICR ECU: a133 radar blocked";
CM_ SG_ 2026 ICR_a134_radarPgood "ICR ECU: a134 radar pgood";
CM_ SG_ 2026 ICR_a135_radarTxBallBreak "ICR ECU: a135 radar tx ball break";
CM_ SG_ 2026 ICR_a136_radarHighTemperature "ICR ECU: a136 radar high temperature";
CM_ SG_ 2026 ICR_a137_radarBlocked "ICR ECU: a137 radar blocked";
CM_ SG_ 2026 ICR_a138_DriverSideMismatch "ICR ECU: a138 driver side mismatch";
CM_ SG_ 2026 ICR_a139_AbnormalBlockageDetecte "ICR ECU: a139 abnormal blockage detected";
CM_ SG_ 2026 ICR_a140_OccupancyExceptionEncou "ICR ECU: a140 occupancy exception encountered";
CM_ SG_ 2026 ICR_a141_RequiresReplacement "ICR ECU: a141 requires replacement";
CM_ SG_ 2026 ICR_a142_ModeOverrideActive "ICR ECU: a142 mode override active";
CM_ BO_ 760 "ICR ECU message: intrusion debug";
CM_ SG_ 760 ICR_loggingPeaksDBG "ICR ECU: logging peaks DBG";
CM_ SG_ 760 ICR_loggingCorrelationDBG "ICR ECU: logging correlation DBG";
CM_ SG_ 760 ICR_loggingTriggerRangeDBG "ICR ECU: logging trigger range DBG";
CM_ SG_ 760 ICR_loggingTriggerXPosDBG "ICR ECU: logging trigger x pos DBG";
CM_ SG_ 760 ICR_loggingTriggerYPosDBG "ICR ECU: logging trigger y pos DBG";
CM_ BO_ 2025 "ICR ECU message: occupancy";
CM_ SG_ 2025 ICR_occupancy1LRaw "(Non-Functional Interface) Occupancy detection status of First Row left seat; raw 3 = signal not available (SNA)";
CM_ SG_ 2025 ICR_occupancy1RRaw "(Non-Functional Interface) Occupancy detection status of First Row right seat; raw 3 = signal not available (SNA)";
CM_ SG_ 2025 ICR_occupancy1LVoteCnt "ICR ECU: occupancy1 l vote cnt";
CM_ SG_ 2025 ICR_occupancy1RVoteCnt "ICR ECU: occupancy1 r vote cnt";
CM_ SG_ 2025 ICR_userPresenceFilt "Detection status of User Presence Detection feature; raw 3 = signal not available (SNA)";
CM_ SG_ 2025 ICR_userPresenceRaw "ICR ECU: user presence raw; raw 3 = signal not available (SNA)";
CM_ SG_ 2025 ICR_occupancy1LFilt "(Non-Functional Interface) Occupancy detection status of First Row left seat; raw 3 = signal not available (SNA)";
CM_ SG_ 2025 ICR_occupancy1RFilt "(Non-Functional Interface) Occupancy detection status of First Row right seat; raw 3 = signal not available (SNA)";
CM_ SG_ 2025 ICR_occupancy2LFilt "ICR ECU: occupancy2 l filt; raw 3 = signal not available (SNA)";
CM_ SG_ 2025 ICR_occupancy2CFilt "ICR ECU: occupancy2 c filt; raw 3 = signal not available (SNA)";
CM_ SG_ 2025 ICR_occupancy2RFilt "ICR ECU: occupancy2 r filt; raw 3 = signal not available (SNA)";
CM_ SG_ 2025 ICR_childPresenceFilt "ICR ECU: child presence filt; raw 0 = signal not available (SNA)";
CM_ SG_ 2025 ICR_childPresenceRaw "ICR ECU: child presence raw; raw 0 = signal not available (SNA)";
CM_ SG_ 2025 ICR_classification1LFilt "ICR ECU: classification1 l filt; raw 0 = signal not available (SNA)";
CM_ SG_ 2025 ICR_classification1RqF "ICR ECU: classification1 rq f";
CM_ SG_ 2025 ICR_occupancy1RFiltExp "ICR ECU: occupancy1 r filt exp; raw 3 = signal not available (SNA)";
CM_ SG_ 2025 ICR_occupancyCounter "ICR ECU: occupancy counter";
CM_ SG_ 2025 ICR_occupancyChecksum "ICR ECU: occupancy checksum";
CM_ BO_ 670 "ICR ECU message: occupancy2";
CM_ SG_ 670 ICR_userPresenceMLOutput "ICR ECU: user presence ML output; raw 255 = signal not available (SNA)";
CM_ SG_ 670 ICR_childPresenceMLOutput "ICR ECU: child presence ML output; raw 255 = signal not available (SNA)";
CM_ SG_ 670 ICR_classification1RFilt "Occupant classification status of First Row Right seat; raw 0 = signal not available (SNA)";
CM_ SG_ 670 ICR_classification1LRaw "ICR ECU: classification1 l raw; raw 0 = signal not available (SNA)";
CM_ SG_ 670 ICR_classification1RRaw "ICR ECU: classification1 r raw; raw 0 = signal not available (SNA)";
CM_ SG_ 670 ICR_classification1LMLOutput "ICR ECU: classification1 LML output; raw 255 = signal not available (SNA)";
CM_ SG_ 670 ICR_classification1RMLOutput "ICR ECU: classification1 RML output; raw 255 = signal not available (SNA)";
CM_ SG_ 670 ICR_occupancy2Counter "ICR ECU: occupancy2 counter";
CM_ SG_ 670 ICR_occupancy2Checksum "ICR ECU: occupancy2 checksum";
CM_ BO_ 2023 "ICR ECU message: status";
CM_ SG_ 2023 ICR_sensorMode "ICR ECU: sensor mode";
CM_ SG_ 2023 ICR_blocked "Indicates if sensor is blocked or not; raw 0 = signal not available (SNA)";
CM_ SG_ 2023 ICR_algoVersion "ICR ECU: algo version";
CM_ SG_ 2023 ICR_l2HeapUsage "ICR ECU: l2 heap usage";
CM_ SG_ 2023 ICR_intrusionStatus "ICR ECU: intrusion status";
CM_ SG_ 2023 ICR_booted "Indicates if ICR has rebooted";
CM_ SG_ 2023 ICR_rdMapDumpCompleted "ICR ECU: rd map dump completed";
CM_ BO_ 1624 "ICR ECU message: uds response";
CM_ SG_ 1624 ICR_udsResponseData "ICR ECU: uds response data";
CM_ BO_ 1470 "IDB ECU message: alert log";
CM_ SG_ 1470 IDB_alertID "IDB ECU: alert ID";
CM_ SG_ 1470 IDB_alertState "IDB ECU: alert state";
CM_ SG_ 1470 IDB_a014_wheelSpeedSensorFreq "IDB ECU: a014 wheel speed sensor freq";
CM_ SG_ 1470 IDB_a014_wheelSpeedSensorPhase "IDB ECU: a014 wheel speed sensor phase";
CM_ SG_ 1470 IDB_a014_wheelSpeedSensorMisinst "IDB ECU: a014 wheel speed sensor misinstallation";
CM_ SG_ 1470 IDB_a014_wheelSpeedSensorWrongEx "IDB ECU: a014 wheel speed sensor wrong exciter";
CM_ SG_ 1470 IDB_a014_wheelSpeedSensorSpeedJu "IDB ECU: a014 wheel speed sensor speed jump minus";
CM_ SG_ 1470 IDB_a014_wheelSpeedSensorSp_0001 "IDB ECU: a014 wheel speed sensor speed jump plus";
CM_ SG_ 1470 IDB_a014_wheelSpeedSensorAirGap "IDB ECU: a014 wheel speed sensor air gap";
CM_ SG_ 1470 IDB_a014_wheelSpeedSensorBIST "IDB ECU: a014 wheel speed sensor BIST";
CM_ SG_ 1470 IDB_a014_wheelSpeedSensorLeakage "IDB ECU: a014 wheel speed sensor leakage cur";
CM_ SG_ 1470 IDB_a014_wheelSpeedSensorOverTem "IDB ECU: a014 wheel speed sensor over temp";
CM_ SG_ 1470 IDB_a014_wheelSpeedSensorSh_0001 "IDB ECU: a014 wheel speed sensor short to gnd";
CM_ SG_ 1470 IDB_a014_wheelSpeedSensorShortTo "IDB ECU: a014 wheel speed sensor short to bat";
CM_ SG_ 1470 IDB_a014_wheelSpeedSensorOpen "IDB ECU: a014 wheel speed sensor open";
CM_ SG_ 1470 IDB_a015_wheelSpeedSensorFreq "IDB ECU: a015 wheel speed sensor freq";
CM_ SG_ 1470 IDB_a015_wheelSpeedSensorPhase "IDB ECU: a015 wheel speed sensor phase";
CM_ SG_ 1470 IDB_a015_wheelSpeedSensorMisinst "IDB ECU: a015 wheel speed sensor misinstallation";
CM_ SG_ 1470 IDB_a015_wheelSpeedSensorWrongEx "IDB ECU: a015 wheel speed sensor wrong exciter";
CM_ SG_ 1470 IDB_a015_wheelSpeedSensorSpeedJu "IDB ECU: a015 wheel speed sensor speed jump minus";
CM_ SG_ 1470 IDB_a015_wheelSpeedSensorSp_0001 "IDB ECU: a015 wheel speed sensor speed jump plus";
CM_ SG_ 1470 IDB_a015_wheelSpeedSensorAirGap "IDB ECU: a015 wheel speed sensor air gap";
CM_ SG_ 1470 IDB_a015_wheelSpeedSensorBIST "IDB ECU: a015 wheel speed sensor BIST";
CM_ SG_ 1470 IDB_a015_wheelSpeedSensorLeakage "IDB ECU: a015 wheel speed sensor leakage cur";
CM_ SG_ 1470 IDB_a015_wheelSpeedSensorOverTem "IDB ECU: a015 wheel speed sensor over temp";
CM_ SG_ 1470 IDB_a015_wheelSpeedSensorSh_0001 "IDB ECU: a015 wheel speed sensor short to gnd";
CM_ SG_ 1470 IDB_a015_wheelSpeedSensorShortTo "IDB ECU: a015 wheel speed sensor short to bat";
CM_ SG_ 1470 IDB_a015_wheelSpeedSensorOpen "IDB ECU: a015 wheel speed sensor open";
CM_ SG_ 1470 IDB_a016_wheelSpeedSensorFreq "IDB ECU: a016 wheel speed sensor freq";
CM_ SG_ 1470 IDB_a016_wheelSpeedSensorPhase "IDB ECU: a016 wheel speed sensor phase";
CM_ SG_ 1470 IDB_a016_wheelSpeedSensorMisinst "IDB ECU: a016 wheel speed sensor misinstallation";
CM_ SG_ 1470 IDB_a016_wheelSpeedSensorWrongEx "IDB ECU: a016 wheel speed sensor wrong exciter";
CM_ SG_ 1470 IDB_a016_wheelSpeedSensorSpeedJu "IDB ECU: a016 wheel speed sensor speed jump minus";
CM_ SG_ 1470 IDB_a016_wheelSpeedSensorSp_0001 "IDB ECU: a016 wheel speed sensor speed jump plus";
CM_ SG_ 1470 IDB_a016_wheelSpeedSensorAirGap "IDB ECU: a016 wheel speed sensor air gap";
CM_ SG_ 1470 IDB_a016_wheelSpeedSensorBIST "IDB ECU: a016 wheel speed sensor BIST";
CM_ SG_ 1470 IDB_a016_wheelSpeedSensorLeakage "IDB ECU: a016 wheel speed sensor leakage cur";
CM_ SG_ 1470 IDB_a016_wheelSpeedSensorOverTem "IDB ECU: a016 wheel speed sensor over temp";
CM_ SG_ 1470 IDB_a016_wheelSpeedSensorSh_0001 "IDB ECU: a016 wheel speed sensor short to gnd";
CM_ SG_ 1470 IDB_a016_wheelSpeedSensorShortTo "IDB ECU: a016 wheel speed sensor short to bat";
CM_ SG_ 1470 IDB_a016_wheelSpeedSensorOpen "IDB ECU: a016 wheel speed sensor open";
CM_ SG_ 1470 IDB_a017_wheelSpeedSensorFreq "IDB ECU: a017 wheel speed sensor freq";
CM_ SG_ 1470 IDB_a017_wheelSpeedSensorPhase "IDB ECU: a017 wheel speed sensor phase";
CM_ SG_ 1470 IDB_a017_wheelSpeedSensorMisinst "IDB ECU: a017 wheel speed sensor misinstallation";
CM_ SG_ 1470 IDB_a017_wheelSpeedSensorWrongEx "IDB ECU: a017 wheel speed sensor wrong exciter";
CM_ SG_ 1470 IDB_a017_wheelSpeedSensorSpeedJu "IDB ECU: a017 wheel speed sensor speed jump minus";
CM_ SG_ 1470 IDB_a017_wheelSpeedSensorSp_0001 "IDB ECU: a017 wheel speed sensor speed jump plus";
CM_ SG_ 1470 IDB_a017_wheelSpeedSensorAirGap "IDB ECU: a017 wheel speed sensor air gap";
CM_ SG_ 1470 IDB_a017_wheelSpeedSensorBIST "IDB ECU: a017 wheel speed sensor BIST";
CM_ SG_ 1470 IDB_a017_wheelSpeedSensorLeakage "IDB ECU: a017 wheel speed sensor leakage cur";
CM_ SG_ 1470 IDB_a017_wheelSpeedSensorOverTem "IDB ECU: a017 wheel speed sensor over temp";
CM_ SG_ 1470 IDB_a017_wheelSpeedSensorSh_0001 "IDB ECU: a017 wheel speed sensor short to gnd";
CM_ SG_ 1470 IDB_a017_wheelSpeedSensorShortTo "IDB ECU: a017 wheel speed sensor short to bat";
CM_ SG_ 1470 IDB_a017_wheelSpeedSensorOpen "IDB ECU: a017 wheel speed sensor open";
CM_ SG_ 1470 IDB_a020_canSignalValidity "IDB ECU: a020 can signal validity";
CM_ SG_ 1470 IDB_a020_signalValueCrosscheck "IDB ECU: a020 signal value crosscheck";
CM_ SG_ 1470 IDB_a030_primaryExternalCircuitL "IDB ECU: a030 primary external circuit leakage";
CM_ SG_ 1470 IDB_a030_secondaryExternalCircui "IDB ECU: a030 secondary external circuit leakage";
CM_ SG_ 1470 IDB_a030_primaryChamberInternalL "IDB ECU: a030 primary chamber internal leakage";
CM_ SG_ 1470 IDB_a030_syncModeInternalLeakage "IDB ECU: a030 sync mode internal leakage";
CM_ SG_ 1470 IDB_a030_secondaryChamberInterna "IDB ECU: a030 secondary chamber internal leakage";
CM_ SG_ 1470 IDB_a030_masterCylinderInternalL "IDB ECU: a030 master cylinder internal leakage";
CM_ SG_ 1470 IDB_a060_validityOnChassisBus "IDB ECU: a060 validity on chassis bus";
CM_ SG_ 1470 IDB_a060_validityOnPartyBus "IDB ECU: a060 validity on party bus";
CM_ SG_ 1470 IDB_a061_validityOnChassisBus "IDB ECU: a061 validity on chassis bus";
CM_ SG_ 1470 IDB_a061_validityOnPartyBus "IDB ECU: a061 validity on party bus";
CM_ SG_ 1470 IDB_a062_validityOnChassisBus "IDB ECU: a062 validity on chassis bus";
CM_ SG_ 1470 IDB_a062_validityOnPartyBus "IDB ECU: a062 validity on party bus";
CM_ SG_ 1470 IDB_a063_validityOnChassisBus "IDB ECU: a063 validity on chassis bus";
CM_ SG_ 1470 IDB_a063_validityOnPartyBus "IDB ECU: a063 validity on party bus";
CM_ SG_ 1470 IDB_a064_validityOnChassisBus "IDB ECU: a064 validity on chassis bus";
CM_ SG_ 1470 IDB_a064_validityOnPartyBus "IDB ECU: a064 validity on party bus";
CM_ SG_ 1470 IDB_a065_validityOnChassisBus "IDB ECU: a065 validity on chassis bus";
CM_ SG_ 1470 IDB_a065_validityOnPartyBus "IDB ECU: a065 validity on party bus";
CM_ SG_ 1470 IDB_a106_qualifierValidity "IDB ECU: a106 qualifier validity";
CM_ SG_ 1470 IDB_a106_signalNotAvailable "IDB ECU: a106 signal not available";
CM_ SG_ 1470 IDB_a107_qualifierValidity "IDB ECU: a107 qualifier validity";
CM_ SG_ 1470 IDB_a107_signalNotAvailable "IDB ECU: a107 signal not available";
CM_ SG_ 1470 IDB_a112_qualifierValidity "IDB ECU: a112 qualifier validity";
CM_ SG_ 1470 IDB_a112_signalNotAvailable "IDB ECU: a112 signal not available";
CM_ SG_ 1470 IDB_a113_qualifierValidity "IDB ECU: a113 qualifier validity";
CM_ SG_ 1470 IDB_a113_signalNotAvailable "IDB ECU: a113 signal not available";
CM_ SG_ 1470 IDB_a114_qualifierValidity "IDB ECU: a114 qualifier validity";
CM_ SG_ 1470 IDB_a114_signalNotAvailable "IDB ECU: a114 signal not available";
CM_ SG_ 1470 IDB_a126_PMebrCmdStateValidity "IDB ECU: a126 p mebr cmd state validity";
CM_ SG_ 1470 IDB_a126_PMstate2Validity "IDB ECU: a126 p mstate2 validity";
CM_ SG_ 1470 IDB_a126_PMstate2Missing "IDB ECU: a126 p mstate2 missing";
CM_ SG_ 1470 IDB_a126_DIchassisControlValidit "IDB ECU: a126 d ichassis control validity";
CM_ SG_ 1470 IDB_a126_DIchassisControlMissing "IDB ECU: a126 d ichassis control missing";
CM_ SG_ 1470 IDB_a126_DIrequestActiveValidity "IDB ECU: a126 d irequest active validity";
CM_ SG_ 1470 IDB_a129_validityOnChassisBus "IDB ECU: a129 validity on chassis bus";
CM_ SG_ 1470 IDB_a129_validityOnPartyBus "IDB ECU: a129 validity on party bus";
CM_ SG_ 1470 IDB_a130_PMbrakePedalCmdQFValidi "IDB ECU: a130 p mbrake pedal cmd QF validity";
CM_ SG_ 1470 IDB_a130_PMstate2Validity "IDB ECU: a130 p mstate2 validity";
CM_ SG_ 1470 IDB_a130_PMstate2Missing "IDB ECU: a130 p mstate2 missing";
CM_ SG_ 1470 IDB_a130_DIbrakeCommandValidity "IDB ECU: a130 d ibrake command validity";
CM_ SG_ 1470 IDB_a130_DIbrakeCommandMissing "IDB ECU: a130 d ibrake command missing";
CM_ SG_ 1470 IDB_a130_DIbrakeTorqueCommandFul "IDB ECU: a130 d ibrake torque command full SNA";
CM_ SG_ 1470 IDB_a130_DIbrakeTorqueComma_0001 "IDB ECU: a130 d ibrake torque command full too low";
CM_ SG_ 1470 IDB_a132_validityOnChassisBus "IDB ECU: a132 validity on chassis bus";
CM_ SG_ 1470 IDB_a132_validityOnPartyBus "IDB ECU: a132 validity on party bus";
CM_ BO_ 983 "IDB ECU message: alert matrix";
CM_ SG_ 983 IDB_matrixIndex "IDB ECU: matrix index";
CM_ SG_ 983 IDB_a001_mcuGenericFault "IDB ECU: a001 mcu generic fault";
CM_ SG_ 983 IDB_a002_supplyOvervoltage "IDB ECU: a002 supply overvoltage";
CM_ SG_ 983 IDB_a003_supplyHardOvervoltage "IDB ECU: a003 supply hard overvoltage";
CM_ SG_ 983 IDB_a004_supplyUndervoltage "IDB ECU: a004 supply undervoltage";
CM_ SG_ 983 IDB_a005_supplyMidUndervoltage "IDB ECU: a005 supply mid undervoltage";
CM_ SG_ 983 IDB_a006_supplyHardUndervoltage "IDB ECU: a006 supply hard undervoltage";
CM_ SG_ 983 IDB_a007_wakeLineOpen "IDB ECU: a007 wake line open";
CM_ SG_ 983 IDB_a008_motorPowerOpen "IDB ECU: a008 motor power open";
CM_ SG_ 983 IDB_a009_asicBoostFault "IDB ECU: a009 asic boost fault";
CM_ SG_ 983 IDB_a010_asicGenericFault "IDB ECU: a010 asic generic fault";
CM_ SG_ 983 IDB_a011_solenoidValveFault "IDB ECU: a011 solenoid valve fault";
CM_ SG_ 983 IDB_a012_motorGenericFault "IDB ECU: a012 motor generic fault";
CM_ SG_ 983 IDB_a013_motorPosSensorFault "IDB ECU: a013 motor pos sensor fault";
CM_ SG_ 983 IDB_a014_FrLWSSFault "IDB ECU: a014 fr LWSS fault";
CM_ SG_ 983 IDB_a015_FrRWSSFault "IDB ECU: a015 fr RWSS fault";
CM_ SG_ 983 IDB_a016_ReLWSSFault "IDB ECU: a016 re LWSS fault";
CM_ SG_ 983 IDB_a017_ReRWSSFault "IDB ECU: a017 re RWSS fault";
CM_ SG_ 983 IDB_a018_WSSGenericFault "IDB ECU: a018 WSS generic fault";
CM_ SG_ 983 IDB_a019_pedalSensorFault "IDB ECU: a019 pedal sensor fault";
CM_ SG_ 983 IDB_a020_RCUpedalTravelMismatch "IDB ECU: a020 RC upedal travel mismatch";
CM_ SG_ 983 IDB_a021_pedalSensorNotCal "IDB ECU: a021 pedal sensor not cal";
CM_ SG_ 983 IDB_a022_brakeFluidLow "IDB ECU: a022 brake fluid low";
CM_ SG_ 983 IDB_a023_steeringImplausible "IDB ECU: a023 steering implausible";
CM_ SG_ 983 IDB_a024_yawImplausible "IDB ECU: a024 yaw implausible";
CM_ SG_ 983 IDB_a025_ayImplausible "IDB ECU: a025 ay implausible";
CM_ SG_ 983 IDB_a026_axImplausible "IDB ECU: a026 ax implausible";
CM_ SG_ 983 IDB_a027_circuitPresSensorFault "IDB ECU: a027 circuit pres sensor fault";
CM_ SG_ 983 IDB_a028_simPresSensorFault "IDB ECU: a028 sim pres sensor fault";
CM_ SG_ 983 IDB_a029_pressureSensNotCal "IDB ECU: a029 pressure sens not cal";
CM_ SG_ 983 IDB_a030_fluidLeakDetected "IDB ECU: a030 fluid leak detected";
CM_ SG_ 983 IDB_a031_solenoidValveStuck "IDB ECU: a031 solenoid valve stuck";
CM_ SG_ 983 IDB_a032_motorSoftOverheat "IDB ECU: a032 motor soft overheat";
CM_ SG_ 983 IDB_a033_motorHardOverheat "IDB ECU: a033 motor hard overheat";
CM_ SG_ 983 IDB_a034_motorPositionSetFault "IDB ECU: a034 motor position set fault";
CM_ SG_ 983 IDB_a035_motorStuck "IDB ECU: a035 motor stuck";
CM_ SG_ 983 IDB_a036_partyBusOff "IDB ECU: a036 party bus off";
CM_ SG_ 983 IDB_a037_chassisBusOff "IDB ECU: a037 chassis bus off";
CM_ SG_ 983 IDB_a038_motorInitFault "IDB ECU: a038 motor init fault";
CM_ SG_ 983 IDB_a039_absActive "IDB ECU: a039 abs active";
CM_ SG_ 983 IDB_a040_ebdActive "IDB ECU: a040 ebd active";
CM_ SG_ 983 IDB_a041_vdcActive "IDB ECU: a041 vdc active";
CM_ SG_ 983 IDB_a042_btcActive "IDB ECU: a042 btc active";
CM_ SG_ 983 IDB_a043_DItorquePathActive "IDB ECU: a043 d itorque path active";
CM_ SG_ 983 IDB_a044_standstillSkidDetected "IDB ECU: a044 standstill skid detected";
CM_ SG_ 983 IDB_a045_panicBrakeAssistActive "IDB ECU: a045 panic brake assist active";
CM_ SG_ 983 IDB_a046_fadeCompensationActive "IDB ECU: a046 fade compensation active";
CM_ SG_ 983 IDB_a047_brakeDiscWipeActive "IDB ECU: a047 brake disc wipe active";
CM_ SG_ 983 IDB_a048_scmActive "IDB ECU: a048 scm active";
CM_ SG_ 983 IDB_a049_cdpActive "IDB ECU: a049 cdp active";
CM_ SG_ 983 IDB_a050_absFaulted "IDB ECU: a050 abs faulted";
CM_ SG_ 983 IDB_a051_ebdFaulted "IDB ECU: a051 ebd faulted";
CM_ SG_ 983 IDB_a052_vdcFaulted "IDB ECU: a052 vdc faulted";
CM_ SG_ 983 IDB_a053_DItorquePathFaulted "IDB ECU: a053 d itorque path faulted";
CM_ SG_ 983 IDB_a054_skidDetectionFaulted "IDB ECU: a054 skid detection faulted";
CM_ SG_ 983 IDB_a055_panicBrakeAssistFaulted "IDB ECU: a055 panic brake assist faulted";
CM_ SG_ 983 IDB_a056_fadeCompensationFaulted "IDB ECU: a056 fade compensation faulted";
CM_ SG_ 983 IDB_a057_bdwRequestInvalid "IDB ECU: a057 bdw request invalid";
CM_ SG_ 983 IDB_a058_scmFaulted "IDB ECU: a058 scm faulted";
CM_ SG_ 983 IDB_a059_cdpFaulted "IDB ECU: a059 cdp faulted";
CM_ SG_ 983 IDB_a060_RCUstatusDLC "IDB ECU: a060 RC ustatus DLC";
CM_ SG_ 983 IDB_a061_RCUstatusChecksum "IDB ECU: a061 RC ustatus checksum";
CM_ SG_ 983 IDB_a062_RCUstatusCounter "IDB ECU: a062 RC ustatus counter";
CM_ SG_ 983 IDB_a063_RCUactuationDLC "IDB ECU: a063 RC uactuation DLC";
CM_ SG_ 983 IDB_a064_RCUactuationChecksum "IDB ECU: a064 RC uactuation checksum";
CM_ SG_ 983 IDB_a065_RCUactuationCounter "IDB ECU: a065 RC uactuation counter";
CM_ SG_ 983 IDB_a066_DIFtorqueDLC "IDB ECU: a066 DI ftorque DLC";
CM_ SG_ 983 IDB_a067_DIFtorqueChecksum "IDB ECU: a067 DI ftorque checksum";
CM_ SG_ 983 IDB_a068_DIFtorqueCounter "IDB ECU: a068 DI ftorque counter";
CM_ SG_ 983 IDB_a069_DIchassisControlDLC "IDB ECU: a069 d ichassis control DLC";
CM_ SG_ 983 IDB_a070_DIchassisControlChecksu "IDB ECU: a070 d ichassis control checksum";
CM_ SG_ 983 IDB_a071_DIchassisControlCounter "IDB ECU: a071 d ichassis control counter";
CM_ SG_ 983 IDB_a072_DIsystemStatusDLC "IDB ECU: a072 d isystem status DLC";
CM_ SG_ 983 IDB_a073_DIsystemStatusChecksum "IDB ECU: a073 d isystem status checksum";
CM_ SG_ 983 IDB_a074_DIsystemStatusCounter "IDB ECU: a074 d isystem status counter";
CM_ SG_ 983 IDB_a075_DIRtorqueDLC "IDB ECU: a075 DI rtorque DLC";
CM_ SG_ 983 IDB_a076_DIRtorqueChecksum "IDB ECU: a076 DI rtorque checksum";
CM_ SG_ 983 IDB_a077_DIRtorqueCounter "IDB ECU: a077 DI rtorque counter";
CM_ SG_ 983 IDB_a078_DIvdcLeftDLC "IDB ECU: a078 d ivdc left DLC";
CM_ SG_ 983 IDB_a079_DIvdcLeftChecksum "IDB ECU: a079 d ivdc left checksum";
CM_ SG_ 983 IDB_a080_DIvdcLeftCounter "IDB ECU: a080 d ivdc left counter";
CM_ SG_ 983 IDB_a081_DIvdcRightDLC "IDB ECU: a081 d ivdc right DLC";
CM_ SG_ 983 IDB_a082_DIvdcRightChecksum "IDB ECU: a082 d ivdc right checksum";
CM_ SG_ 983 IDB_a083_DIvdcRightCounter "IDB ECU: a083 d ivdc right counter";
CM_ SG_ 983 IDB_a084_EPAS3PsysStatusDLC "IDB ECU: a084 EPAS3 psys status DLC";
CM_ SG_ 983 IDB_a085_EPAS3PsysStatusChecksum "IDB ECU: a085 EPAS3 psys status checksum";
CM_ SG_ 983 IDB_a086_EPAS3PsysStatusCounter "IDB ECU: a086 EPAS3 psys status counter";
CM_ SG_ 983 IDB_a087_PMstate2DLC "IDB ECU: a087 p mstate2 DLC";
CM_ SG_ 983 IDB_a088_PMstate2Checksum "IDB ECU: a088 p mstate2 checksum";
CM_ SG_ 983 IDB_a089_PMstate2Counter "IDB ECU: a089 p mstate2 counter";
CM_ SG_ 983 IDB_a090_RCMinertial1DLC "IDB ECU: a090 RC minertial1 DLC";
CM_ SG_ 983 IDB_a091_RCMinertial1Checksum "IDB ECU: a091 RC minertial1 checksum";
CM_ SG_ 983 IDB_a092_RCMinertial1Counter "IDB ECU: a092 RC minertial1 counter";
CM_ SG_ 983 IDB_a093_RCMinertial2DLC "IDB ECU: a093 RC minertial2 DLC";
CM_ SG_ 983 IDB_a094_RCMinertial2Checksum "IDB ECU: a094 RC minertial2 checksum";
CM_ SG_ 983 IDB_a095_RCMinertial2Counter "IDB ECU: a095 RC minertial2 counter";
CM_ SG_ 983 IDB_a096_VCFRONTLVPowerStateDLC "IDB ECU: a096 VCFRONTLV power state DLC";
CM_ SG_ 983 IDB_a097_VCFRONTLVPwrStChecksum "IDB ECU: a097 VCFRONTLV pwr st checksum";
CM_ SG_ 983 IDB_a098_VCFRONTLVPwrStCounter "IDB ECU: a098 VCFRONTLV pwr st counter";
CM_ SG_ 983 IDB_a099_RCMcollisionDLC "IDB ECU: a099 RC mcollision DLC";
CM_ SG_ 983 IDB_a100_RCMcollisionChecksum "IDB ECU: a100 RC mcollision checksum";
CM_ SG_ 983 IDB_a101_RCMcollisionCounter "IDB ECU: a101 RC mcollision counter";
CM_ SG_ 983 IDB_a102_bdwRequestActiveInvalid "IDB ECU: a102 bdw request active invalid";
CM_ SG_ 983 IDB_a103_DIfullTorquePathFaulted "IDB ECU: a103 d ifull torque path faulted";
CM_ SG_ 983 IDB_a104_DIaccelPosInvalid "IDB ECU: a104 d iaccel pos invalid";
CM_ SG_ 983 IDB_a105_DIgearInvalid "IDB ECU: a105 d igear invalid";
CM_ SG_ 983 IDB_a106_DIFtorqueInvalid "IDB ECU: a106 DI ftorque invalid";
CM_ SG_ 983 IDB_a107_DIRtorqueInvalid "IDB ECU: a107 DI rtorque invalid";
CM_ SG_ 983 IDB_a108_EPBstatusDLC "IDB ECU: a108 EP bstatus DLC";
CM_ SG_ 983 IDB_a109_BDWsignalInvalid "IDB ECU: a109 BD wsignal invalid";
CM_ SG_ 983 IDB_a110_EPBstatusCounter "IDB ECU: a110 EP bstatus counter";
CM_ SG_ 983 IDB_a111_EPBstatusChecksum "IDB ECU: a111 EP bstatus checksum";
CM_ SG_ 983 IDB_a112_yawRateInvalid "IDB ECU: a112 yaw rate invalid";
CM_ SG_ 983 IDB_a113_latAccelInvalid "IDB ECU: a113 lat accel invalid";
CM_ SG_ 983 IDB_a114_longAccelInvalid "IDB ECU: a114 long accel invalid";
CM_ SG_ 983 IDB_a115_VCFRONTespLvStInvalid "IDB ECU: a115 VCFRON tesp lv st invalid";
CM_ SG_ 983 IDB_a116_VCFRONTsensorsDLC "IDB ECU: a116 VCFRON tsensors DLC";
CM_ SG_ 983 IDB_a117_VCLEFTepbmStatusDLC "IDB ECU: a117 VCLEF tepbm status DLC";
CM_ SG_ 983 IDB_a118_VCLEFTepbmStatusCounter "IDB ECU: a118 VCLEF tepbm status counter";
CM_ SG_ 983 IDB_a119_VCLEFTepbmStatusChecksu "IDB ECU: a119 VCLEF tepbm status checksum";
CM_ SG_ 983 IDB_a120_EPAS3Pinvalid "IDB ECU: a120 EPAS3 pinvalid";
CM_ SG_ 983 IDB_a121_dynoModeActive "IDB ECU: a121 dyno mode active";
CM_ SG_ 983 IDB_a122_DIFtorqueCommandInvalid "IDB ECU: a122 DI ftorque command invalid";
CM_ SG_ 983 IDB_a123_DIRtorqueCommandInvalid "IDB ECU: a123 DI rtorque command invalid";
CM_ SG_ 983 IDB_a124_VCFRONTtempInvalid "IDB ECU: a124 VCFRON ttemp invalid";
CM_ SG_ 983 IDB_a125_PMvdcCmdStateInvalid "IDB ECU: a125 p mvdc cmd state invalid";
CM_ SG_ 983 IDB_a126_DItorqueRequestInvalid "IDB ECU: a126 d itorque request invalid";
CM_ SG_ 983 IDB_a127_brakeFluidLevelInvalid "IDB ECU: a127 brake fluid level invalid";
CM_ SG_ 983 IDB_a128_reserved1 "IDB ECU: a128 reserved1";
CM_ SG_ 983 IDB_a129_RCUinputRodStrokeInvali "IDB ECU: a129 RC uinput rod stroke invalid";
CM_ SG_ 983 IDB_a130_DIfullTorqueRequestInva "IDB ECU: a130 d ifull torque request invalid";
CM_ SG_ 983 IDB_a131_DIfullTorquePathActive "IDB ECU: a131 d ifull torque path active";
CM_ SG_ 983 IDB_a132_RCUinputRodStrokeQFInva "IDB ECU: a132 RC uinput rod stroke QF invalid";
CM_ SG_ 983 IDB_a133_DIbrakeCommandDLC "IDB ECU: a133 d ibrake command DLC";
CM_ SG_ 983 IDB_a134_DIbrakeCommandCounter "IDB ECU: a134 d ibrake command counter";
CM_ SG_ 983 IDB_a135_DIbrakeCommandChecksum "IDB ECU: a135 d ibrake command checksum";
CM_ SG_ 983 IDB_a136_RCUptsCalMissing "IDB ECU: a136 RC upts cal missing";
CM_ SG_ 983 IDB_a137_VCLEFTcdpRequestInvalid "IDB ECU: a137 VCLEF tcdp request invalid";
CM_ SG_ 983 IDB_a138_DIbrakeTorqueCommandAnd "IDB ECU: a138 d ibrake torque command and flag mismatch";
CM_ SG_ 983 IDB_a139_DIbrakeTorqueCommandFul "IDB ECU: a139 d ibrake torque command full SNA";
CM_ SG_ 983 IDB_a140_PMbrakePedalCmdQFInvali "IDB ECU: a140 p mbrake pedal cmd QF invalid";
CM_ SG_ 983 IDB_a141_DIbrakeTorqueCommandFul "IDB ECU: a141 d ibrake torque command full too low";
CM_ SG_ 983 IDB_a142_PMebrCmdStateInvalid "IDB ECU: a142 p mebr cmd state invalid";
CM_ SG_ 983 IDB_a143_factoryModeActive "IDB ECU: a143 factory mode active";
CM_ SG_ 983 IDB_a144_hydraulicPushthroughAct "IDB ECU: a144 hydraulic pushthrough active";
CM_ BO_ 1429 "Occupant classification system message: alert log";
CM_ SG_ 1429 OCS1P_alertID "Occupant classification system: alert ID";
CM_ SG_ 1429 OCS1P_alertState "Occupant classification system: alert state";
CM_ SG_ 1429 OCS1P_a121_sandwichFreq "Occupant classification system: a121 sandwich freq";
CM_ SG_ 1429 OCS1P_a122_sandwichFreq "Occupant classification system: a122 sandwich freq";
CM_ SG_ 1429 OCS1P_a123_sandwichFreq "Occupant classification system: a123 sandwich freq";
CM_ SG_ 1429 OCS1P_a124_cushionSelfFreq "Occupant classification system: a124 cushion self freq";
CM_ SG_ 1429 OCS1P_a125_cushionSelfFreq "Occupant classification system: a125 cushion self freq";
CM_ SG_ 1429 OCS1P_a126_cushionSelfFreq "Occupant classification system: a126 cushion self freq";
CM_ SG_ 1429 OCS1P_a127_seatbackSelfFreq "Occupant classification system: a127 seatback self freq";
CM_ SG_ 1429 OCS1P_a128_seatbackSelfFreq "Occupant classification system: a128 seatback self freq";
CM_ SG_ 1429 OCS1P_a129_seatbackSelfFreq "Occupant classification system: a129 seatback self freq";
CM_ SG_ 1429 OCS1P_a130_sandwichNoCalib "Occupant classification system: a130 sandwich no calib";
CM_ SG_ 1429 OCS1P_a131_cushionSelfNoCalib "Occupant classification system: a131 cushion self no calib";
CM_ SG_ 1429 OCS1P_a132_seatbackSelfNoCalib "Occupant classification system: a132 seatback self no calib";
CM_ SG_ 1429 OCS1P_a133_sandwichBadCalib "Occupant classification system: a133 sandwich bad calib";
CM_ SG_ 1429 OCS1P_a134_uninitializedCalib "Occupant classification system: a134 uninitialized calib";
CM_ SG_ 1429 OCS1P_a135_tempNoCalib "Occupant classification system: a135 temp no calib";
CM_ SG_ 1429 OCS1P_a140_tempInvalidCalib "Occupant classification system: a140 temp invalid calib";
CM_ SG_ 1429 OCS1P_a141_humidityInvalidCalib "Occupant classification system: a141 humidity invalid calib";
CM_ SG_ 1429 OCS1P_a142_tempHumidityInvalid "Occupant classification system: a142 temp humidity invalid";
CM_ SG_ 1429 OCS1P_a143_mismatchPassAirbag "Occupant classification system: a143 mismatch pass airbag";
CM_ SG_ 1429 OCS1P_a144_mismatchCarRegion "Occupant classification system: a144 mismatch car region";
CM_ BO_ 767 "Occupant classification system message: alert matrix";
CM_ SG_ 767 OCS1P_matrixIndex "Occupant classification system: matrix index";
CM_ SG_ 767 OCS1P_w015_NVMMAlert "Occupant classification system: w015 NVMM alert";
CM_ SG_ 767 OCS1P_w121_sandwichOpen "Occupant classification system: w121 sandwich open";
CM_ SG_ 767 OCS1P_w122_sandwichLow "Occupant classification system: w122 sandwich low";
CM_ SG_ 767 OCS1P_w123_sandwichShort "Occupant classification system: w123 sandwich short";
CM_ SG_ 767 OCS1P_w124_cushionSelfOpen "Occupant classification system: w124 cushion self open";
CM_ SG_ 767 OCS1P_w125_cushionSelfLow "Occupant classification system: w125 cushion self low";
CM_ SG_ 767 OCS1P_w126_cushionSelfShort "Occupant classification system: w126 cushion self short";
CM_ SG_ 767 OCS1P_w127_seatbackSelfOpen "Occupant classification system: w127 seatback self open";
CM_ SG_ 767 OCS1P_w128_seatbackSelfLow "Occupant classification system: w128 seatback self low";
CM_ SG_ 767 OCS1P_w129_seatbackSelfShort "Occupant classification system: w129 seatback self short";
CM_ SG_ 767 OCS1P_w130_sandwichNoCalib "Occupant classification system: w130 sandwich no calib";
CM_ SG_ 767 OCS1P_w131_cushionSelfNoCalib "Occupant classification system: w131 cushion self no calib";
CM_ SG_ 767 OCS1P_w132_seatbackSelfNoCalib "Occupant classification system: w132 seatback self no calib";
CM_ SG_ 767 OCS1P_w133_sandwichBadCalib "Occupant classification system: w133 sandwich bad calib";
CM_ SG_ 767 OCS1P_w134_uninitializedCalib "Occupant classification system: w134 uninitialized calib";
CM_ SG_ 767 OCS1P_w135_tempNoCalib "Occupant classification system: w135 temp no calib";
CM_ SG_ 767 OCS1P_w136_cushionSelfDutyLow "Occupant classification system: w136 cushion self duty low";
CM_ SG_ 767 OCS1P_w137_cushionSelfDutyHigh "Occupant classification system: w137 cushion self duty high";
CM_ SG_ 767 OCS1P_w138_seatbackSelfDutyLow "Occupant classification system: w138 seatback self duty low";
CM_ SG_ 767 OCS1P_w139_seatbackSelfDutyHigh "Occupant classification system: w139 seatback self duty high";
CM_ SG_ 767 OCS1P_w140_tempInvalidCalib "Occupant classification system: w140 temp invalid calib";
CM_ SG_ 767 OCS1P_w141_humidityInvalidCalib "Occupant classification system: w141 humidity invalid calib";
CM_ SG_ 767 OCS1P_w142_tempHumidityInvalid "Occupant classification system: w142 temp humidity invalid";
CM_ SG_ 767 OCS1P_w143_mismatchPassAirbag "Occupant classification system: w143 mismatch pass airbag";
CM_ SG_ 767 OCS1P_w144_mismatchCarRegion "Occupant classification system: w144 mismatch car region";
CM_ SG_ 767 OCS1P_w145_rebaselineTriggered "Occupant classification system: w145 rebaseline triggered";
CM_ SG_ 767 OCS1P_w148_classificationMismatc "Occupant classification system: w148 classification mismatch";
CM_ SG_ 767 OCS1P_w150_rbEntryTriggered "Occupant classification system: w150 rb entry triggered";
CM_ SG_ 767 OCS1P_w151_rbEntryExited "Occupant classification system: w151 rb entry exited";
CM_ SG_ 767 OCS1P_w152_rbExit1Triggered "Occupant classification system: w152 rb exit1 triggered";
CM_ SG_ 767 OCS1P_w153_rbExit1Exited "Occupant classification system: w153 rb exit1 exited";
CM_ SG_ 767 OCS1P_w154_rbExit2Exited1 "Occupant classification system: w154 rb exit2 exited1";
CM_ SG_ 767 OCS1P_w155_rbExit2Exited2 "Occupant classification system: w155 rb exit2 exited2";
CM_ BO_ 766 "Occupant classification system message: info";
CM_ SG_ 766 OCS1P_infoIndex "Occupant classification system: info index";
CM_ SG_ 766 OCS1P_infoBuildType "Occupant classification system: info build type";
CM_ SG_ 766 OCS1P_infoBuildConfigID "Occupant classification system: info build config ID";
CM_ SG_ 766 OCS1P_infoHardwareID "Occupant classification system: info hardware ID";
CM_ SG_ 766 OCS1P_infoComponentID "Occupant classification system: info component ID";
CM_ SG_ 766 OCS1P_infoPcbaID "Occupant classification system: info pcba ID";
CM_ SG_ 766 OCS1P_infoAssemblyID "Occupant classification system: info assembly ID";
CM_ SG_ 766 OCS1P_infoUsageID "Occupant classification system: info usage ID";
CM_ SG_ 766 OCS1P_infoSubUsageID "Occupant classification system: info sub usage ID";
CM_ SG_ 766 OCS1P_infoApplicationCRC "Occupant classification system: info application CRC";
CM_ SG_ 766 OCS1P_infoBootSvnRev "Occupant classification system: info boot svn rev";
CM_ SG_ 766 OCS1P_infoAppGitHashBytes "Occupant classification system: info app git hash bytes";
CM_ SG_ 766 OCS1P_infoBootGitHashBytes "Occupant classification system: info boot git hash bytes";
CM_ SG_ 766 OCS1P_infoPlatformType "Occupant classification system: info platform type";
CM_ SG_ 766 OCS1P_infoBootUdsProtoVersion "Occupant classification system: info boot uds proto version";
CM_ SG_ 766 OCS1P_infoBootloaderCRC "Occupant classification system: info bootloader CRC";
BA_DEF_ BO_ "GenMsgCycleTime" INT 0 3600000;
BA_DEF_ BO_ "GenMsgSendType" ENUM "Cyclic","NotUsed","NotUsed","NotUsed","NotUsed","NotUsed","NotUsed","IfActive","NoMsgSendType","NotUsed";
BA_DEF_ BO_ "VFrameFormat" ENUM "StandardCAN","ExtendedCAN","reserved","J1939PG","reserved","reserved","reserved","reserved","reserved","reserved","reserved","reserved","reserved","reserved","StandardCAN_FD","ExtendedCAN_FD";
BA_DEF_ BO_ "CANFD_BRS" ENUM "0","1";
BA_DEF_ SG_ "GenSigSNA" STRING;
BA_DEF_ SG_ "SystemSignalLongSymbol" STRING;
BA_DEF_ SG_ "Confidence" ENUM "validated","plausible","layout-only","contradicted";
BA_DEF_DEF_ "GenMsgCycleTime" 0;
BA_DEF_DEF_ "GenMsgSendType" "NoMsgSendType";
BA_DEF_DEF_ "VFrameFormat" "StandardCAN";
BA_DEF_DEF_ "CANFD_BRS" "1";
BA_DEF_DEF_ "GenSigSNA" "";
BA_DEF_DEF_ "SystemSignalLongSymbol" "";
BA_DEF_DEF_ "Confidence" "layout-only";
BA_ "GenMsgCycleTime" BO_ 938 1000;
BA_ "GenMsgSendType" BO_ 938 0;
BA_ "GenMsgCycleTime" BO_ 522 1000;
BA_ "GenMsgSendType" BO_ 522 0;
BA_ "GenMsgCycleTime" BO_ 1962 1000;
BA_ "GenMsgSendType" BO_ 1962 0;
BA_ "GenMsgCycleTime" BO_ 1666 100;
BA_ "GenMsgSendType" BO_ 1666 0;
BA_ "GenMsgCycleTime" BO_ 861 1000;
BA_ "GenMsgSendType" BO_ 861 0;
BA_ "GenMsgCycleTime" BO_ 2026 100;
BA_ "GenMsgSendType" BO_ 2026 0;
BA_ "GenMsgCycleTime" BO_ 760 100;
BA_ "GenMsgSendType" BO_ 760 0;
BA_ "GenMsgCycleTime" BO_ 2025 100;
BA_ "GenMsgSendType" BO_ 2025 0;
BA_ "GenMsgCycleTime" BO_ 670 100;
BA_ "GenMsgSendType" BO_ 670 0;
BA_ "GenMsgCycleTime" BO_ 2023 100;
BA_ "GenMsgSendType" BO_ 2023 0;
BA_ "GenMsgCycleTime" BO_ 983 1000;
BA_ "GenMsgSendType" BO_ 983 0;
BA_ "GenMsgCycleTime" BO_ 767 100;
BA_ "GenMsgSendType" BO_ 767 0;
BA_ "GenMsgCycleTime" BO_ 766 1000;
BA_ "GenMsgSendType" BO_ 766 0;
BA_ "Confidence" SG_ 938 HVP_matrixIndex 1;
BA_ "SystemSignalLongSymbol" SG_ 938 HVP_w048_swUnsupportedBmbAsicTyp "HVP_w048_swUnsupportedBmbAsicType";
BA_ "SystemSignalLongSymbol" SG_ 938 HVP_w053_hvVoltageSensorRational "HVP_w053_hvVoltageSensorRationality";
BA_ "SystemSignalLongSymbol" SG_ 938 HVP_w068_shuntUnexpectedThermist "HVP_w068_shuntUnexpectedThermistor";
BA_ "Confidence" SG_ 522 HVP_packContNegativeState 0;
BA_ "GenSigSNA" SG_ 522 HVP_packContNegativeState "0";
BA_ "Confidence" SG_ 522 HVP_packContPositiveState 0;
BA_ "GenSigSNA" SG_ 522 HVP_packContPositiveState "0";
BA_ "Confidence" SG_ 522 HVP_fcContPositiveAuxOpen 0;
BA_ "Confidence" SG_ 522 HVP_fcContNegativeAuxOpen 0;
BA_ "Confidence" SG_ 522 HVP_packContactorSetState 0;
BA_ "GenSigSNA" SG_ 522 HVP_packContactorSetState "0";
BA_ "Confidence" SG_ 522 HVP_fcContNegativeState 0;
BA_ "GenSigSNA" SG_ 522 HVP_fcContNegativeState "0";
BA_ "Confidence" SG_ 522 HVP_fcContPositiveState 0;
BA_ "GenSigSNA" SG_ 522 HVP_fcContPositiveState "0";
BA_ "Confidence" SG_ 522 HVP_fcContactorSetState 0;
BA_ "GenSigSNA" SG_ 522 HVP_fcContactorSetState "0";
BA_ "Confidence" SG_ 522 HVP_fcCtrsRequestStatus 0;
BA_ "Confidence" SG_ 522 HVP_fcCtrsResetRequestRequired 0;
BA_ "Confidence" SG_ 522 HVP_fcCtrsOpenNowRequested 0;
BA_ "Confidence" SG_ 522 HVP_fcCtrsOpenRequested 0;
BA_ "Confidence" SG_ 522 HVP_fcCtrsClosingAllowed 0;
BA_ "Confidence" SG_ 522 HVP_packCtrsRequestStatus 0;
BA_ "Confidence" SG_ 522 HVP_packCtrsResetRequestRequired 0;
BA_ "Confidence" SG_ 522 HVP_packCtrsOpenNowRequested 0;
BA_ "Confidence" SG_ 522 HVP_packCtrsOpenRequested 0;
BA_ "Confidence" SG_ 522 HVP_packCtrsClosingAllowed 0;
BA_ "Confidence" SG_ 522 HVP_dcLinkAllowedToEnergize 0;
BA_ "Confidence" SG_ 522 HVP_pyroTestInProgress 0;
BA_ "Confidence" SG_ 522 HVP_hvilDiag 0;
BA_ "GenSigSNA" SG_ 522 HVP_hvilDiag "14";
BA_ "Confidence" SG_ 522 HVP_fcLinkAllowedToEnergize 0;
BA_ "Confidence" SG_ 1962 HVP_debugMessageMultiplexer 1;
BA_ "Confidence" SG_ 1962 HVP_gpioPassivePyroDepl 0;
BA_ "Confidence" SG_ 1962 HVP_gpioPyroIsoEn 0;
BA_ "Confidence" SG_ 1962 HVP_gpioCpFaultIn 0;
BA_ "Confidence" SG_ 1962 HVP_gpioPackContPowerEn 0;
BA_ "Confidence" SG_ 1962 HVP_gpioHvCablesOk 0;
BA_ "Confidence" SG_ 1962 HVP_gpioHvpSelfEnable 0;
BA_ "Confidence" SG_ 1962 HVP_gpioLed 0;
BA_ "Confidence" SG_ 1962 HVP_gpioCrashSignal 0;
BA_ "Confidence" SG_ 1962 HVP_gpioShuntDataReady 0;
BA_ "Confidence" SG_ 1962 HVP_gpioFcContPosAux 0;
BA_ "Confidence" SG_ 1962 HVP_gpioFcContNegAux 0;
BA_ "Confidence" SG_ 1962 HVP_gpioBmsEout 0;
BA_ "Confidence" SG_ 1962 HVP_gpioCpFaultOut 0;
BA_ "Confidence" SG_ 1962 HVP_gpioPyroPor 0;
BA_ "Confidence" SG_ 1962 HVP_gpioShuntEn 0;
BA_ "Confidence" SG_ 1962 HVP_gpioHvpVerEn 0;
BA_ "Confidence" SG_ 1962 HVP_gpioFcContFlywheelEnable 0;
BA_ "Confidence" SG_ 1962 HVP_gpioCpLatchEnable 0;
BA_ "Confidence" SG_ 1962 HVP_gpioFcContPowerEnable 0;
BA_ "Confidence" SG_ 1962 HVP_gpioHvilEnable 0;
BA_ "Confidence" SG_ 1962 HVP_gpioPortSelSpiRdy 0;
BA_ "Confidence" SG_ 1962 HVP_gpioPyroUnlock 0;
BA_ "Confidence" SG_ 1962 HVP_hvp1v5Ref 0;
BA_ "Confidence" SG_ 1962 HVP_packCurrentMia 0;
BA_ "Confidence" SG_ 1962 HVP_auxCurrentMia 0;
BA_ "Confidence" SG_ 1962 HVP_currentSenseMia 0;
BA_ "Confidence" SG_ 1962 HVP_shuntThermistorMissing 0;
BA_ "Confidence" SG_ 1962 HVP_shuntThermistorExpected 0;
BA_ "Confidence" SG_ 1962 HVP_shuntThermistorMia 0;
BA_ "Confidence" SG_ 1962 HVP_shuntUnexpectedThermistor 0;
BA_ "Confidence" SG_ 1962 HVP_shuntHwMia 0;
BA_ "Confidence" SG_ 1962 HVP_shuntCurrentIrrational 0;
BA_ "Confidence" SG_ 1962 HVP_shuntAsicTCompActive 0;
BA_ "Confidence" SG_ 1962 HVP_ecuLogUploadRequest 1;
BA_ "Confidence" SG_ 1962 HVP_packContVoltage 0;
BA_ "Confidence" SG_ 1962 HVP_packNegativeV 0;
BA_ "Confidence" SG_ 1962 HVP_packPositiveV 0;
BA_ "Confidence" SG_ 1962 HVP_pyroAnalog 0;
BA_ "Confidence" SG_ 1962 HVP_fcContCoilCurrent 0;
BA_ "Confidence" SG_ 1962 HVP_fcContVoltage 0;
BA_ "Confidence" SG_ 1962 HVP_hvilInVoltage 0;
BA_ "Confidence" SG_ 1962 HVP_hvilOutVoltage 0;
BA_ "Confidence" SG_ 1962 HVP_shuntGainInvalidCountDbg 0;
BA_ "Confidence" SG_ 1962 HVP_fcLinkPositiveV 1;
BA_ "Confidence" SG_ 1962 HVP_packContCoilCurrent 0;
BA_ "Confidence" SG_ 1962 HVP_battery12V 0;
BA_ "Confidence" SG_ 1962 HVP_shuntRefVoltageDbg 1;
BA_ "Confidence" SG_ 1666 HVP_packContactorHwFault 1;
BA_ "Confidence" SG_ 1666 HVP_fcContactorHwFault 1;
BA_ "Confidence" SG_ 1666 HVP_hvilStatus 1;
BA_ "Confidence" SG_ 1553 HVP_udsResponseData 1;
BA_ "Confidence" SG_ 861 IBST_matrixIndex 1;
BA_ "SystemSignalLongSymbol" SG_ 861 IBST_a182_DIchassisControlTimeou "IBST_a182_DIchassisControlTimeout";
BA_ "SystemSignalLongSymbol" SG_ 861 IBST_a183_DIchassisControlChecks "IBST_a183_DIchassisControlChecksum";
BA_ "SystemSignalLongSymbol" SG_ 861 IBST_a184_DIchassisControlCounte "IBST_a184_DIchassisControlCounter";
BA_ "SystemSignalLongSymbol" SG_ 861 IBST_a189_rightVCLVPowerStateTim "IBST_a189_rightVCLVPowerStateTimeout";
BA_ "SystemSignalLongSymbol" SG_ 861 IBST_a191_rightVCLVPowerStateChe "IBST_a191_rightVCLVPowerStateChecksum";
BA_ "SystemSignalLongSymbol" SG_ 861 IBST_a192_rightVCLVPowerStateCou "IBST_a192_rightVCLVPowerStateCounter";
BA_ "SystemSignalLongSymbol" SG_ 861 IBST_a193_leftVCLVPowerStateTime "IBST_a193_leftVCLVPowerStateTimeout";
BA_ "SystemSignalLongSymbol" SG_ 861 IBST_a194_leftVCLVPowerStateChec "IBST_a194_leftVCLVPowerStateChecksum";
BA_ "SystemSignalLongSymbol" SG_ 861 IBST_a196_leftVCLVPowerStateCoun "IBST_a196_leftVCLVPowerStateCounter";
BA_ "SystemSignalLongSymbol" SG_ 861 IBST_a197_brakeLatencyReductionA "IBST_a197_brakeLatencyReductionActive";
BA_ "SystemSignalLongSymbol" SG_ 861 IBST_a201_EGGREAR1wheelSpeedsRea "IBST_a201_EGGREAR1wheelSpeedsRearTimeOut";
BA_ "SystemSignalLongSymbol" SG_ 861 IBST_a202_EGGREAR1wheelSpeedsRea "IBST_a202_EGGREAR1wheelSpeedsRearChecksum";
BA_ "SystemSignalLongSymbol" SG_ 861 IBST_a203_EGGREAR1wheelSpeedsRea "IBST_a203_EGGREAR1wheelSpeedsRearDLC";
BA_ "SystemSignalLongSymbol" SG_ 861 IBST_a204_EGGREAR1wheelSpeedsRea "IBST_a204_EGGREAR1wheelSpeedsRearCounter";
BA_ "SystemSignalLongSymbol" SG_ 861 IBST_a205_EGGRIGHT1wheelSpeedsFr "IBST_a205_EGGRIGHT1wheelSpeedsFrontTimeOut";
BA_ "SystemSignalLongSymbol" SG_ 861 IBST_a206_EGGRIGHT1wheelSpeedsFr "IBST_a206_EGGRIGHT1wheelSpeedsFrontChecksum";
BA_ "SystemSignalLongSymbol" SG_ 861 IBST_a207_EGGRIGHT1wheelSpeedsFr "IBST_a207_EGGRIGHT1wheelSpeedsFrontDLC";
BA_ "SystemSignalLongSymbol" SG_ 861 IBST_a208_EGGRIGHT1wheelSpeedsFr "IBST_a208_EGGRIGHT1wheelSpeedsFrontCounter";
BA_ "SystemSignalLongSymbol" SG_ 861 IBST_a209_reducedBrakePowerActiv "IBST_a209_reducedBrakePowerActive";
BA_ "SystemSignalLongSymbol" SG_ 861 IBST_a210_reducedBrakePowerNotAv "IBST_a210_reducedBrakePowerNotAvailable";
BA_ "SystemSignalLongSymbol" SG_ 861 IBST_a212_infoFailureWrongCUBASH "IBST_a212_infoFailureWrongCUBASHandlingDetected";
BA_ "SystemSignalLongSymbol" SG_ 861 IBST_a213_PDURouterinitializatio "IBST_a213_PDURouterinitializationFailed";
BA_ "SystemSignalLongSymbol" SG_ 861 IBST_a214_LossOfPDUInstanceDetec "IBST_a214_LossOfPDUInstanceDetected";
BA_ "SystemSignalLongSymbol" SG_ 861 IBST_a215_UnsupportedSeriesHWDet "IBST_a215_UnsupportedSeriesHWDetected";
BA_ "SystemSignalLongSymbol" SG_ 861 IBST_a216_AsicMalfunctionDetecte "IBST_a216_AsicMalfunctionDetected";
BA_ "SystemSignalLongSymbol" SG_ 861 IBST_a217_AsicTrimmingNotComplet "IBST_a217_AsicTrimmingNotCompleted";
BA_ "SystemSignalLongSymbol" SG_ 861 IBST_a218_uCSafetyNotificationGR "IBST_a218_uCSafetyNotificationGRAM";
BA_ "SystemSignalLongSymbol" SG_ 861 IBST_a220_ASICOvercurrentOnGPIO2 "IBST_a220_ASICOvercurrentOnGPIO250_2";
BA_ "SystemSignalLongSymbol" SG_ 861 IBST_a221_ASICOvercurrentOnGPIO2 "IBST_a221_ASICOvercurrentOnGPIO250_1";
BA_ "SystemSignalLongSymbol" SG_ 861 IBST_a222_ASICOvercurrentOnGPIO5 "IBST_a222_ASICOvercurrentOnGPIO50_4";
BA_ "SystemSignalLongSymbol" SG_ 861 IBST_a223_ASICOvercurrentOnGPIO5 "IBST_a223_ASICOvercurrentOnGPIO50_3";
BA_ "SystemSignalLongSymbol" SG_ 861 IBST_a224_ASICOvercurrentOnGPIO5 "IBST_a224_ASICOvercurrentOnGPIO50_2";
BA_ "SystemSignalLongSymbol" SG_ 861 IBST_a225_ASICOvercurrentOnGPIO5 "IBST_a225_ASICOvercurrentOnGPIO50_1";
BA_ "SystemSignalLongSymbol" SG_ 861 IBST_a227_wakeRequestMismatchDet "IBST_a227_wakeRequestMismatchDetected";
BA_ "SystemSignalLongSymbol" SG_ 861 IBST_a228_BlockedPedalDetectedDu "IBST_a228_BlockedPedalDetectedDuringHAD";
BA_ "SystemSignalLongSymbol" SG_ 861 IBST_a232_PostAssemblyRoutineFai "IBST_a232_PostAssemblyRoutineFailed";
BA_ "SystemSignalLongSymbol" SG_ 861 IBST_a233_ReferenceRunAbortByECU "IBST_a233_ReferenceRunAbortByECUReset";
BA_ "Confidence" SG_ 1629 IBST_udsResponseData 1;
BA_ "Confidence" SG_ 1208 ICR_alertID 1;
BA_ "Confidence" SG_ 1208 ICR_alertState 1;
BA_ "SystemSignalLongSymbol" SG_ 1208 ICR_a001_watchdogTaskSentinelInt "ICR_a001_watchdogTaskSentinelInterface";
BA_ "SystemSignalLongSymbol" SG_ 1208 ICR_a001_watchdogTaskSentinelMod "ICR_a001_watchdogTaskSentinelModeChange";
BA_ "Confidence" SG_ 1208 ICR_a059_voltageDrop 1;
BA_ "Confidence" SG_ 1208 ICR_a059_resistanceEstimate 1;
BA_ "Confidence" SG_ 1208 ICR_a059_current 1;
BA_ "Confidence" SG_ 1208 ICR_a063_ADCVoltage 1;
BA_ "Confidence" SG_ 1208 ICR_a133_nearClutter 1;
BA_ "Confidence" SG_ 1208 ICR_a133_farClutter 1;
BA_ "Confidence" SG_ 1208 ICR_a137_nearClutter 1;
BA_ "Confidence" SG_ 1208 ICR_a137_farClutter 1;
BA_ "Confidence" SG_ 1208 ICR_a139_nearClutter 1;
BA_ "Confidence" SG_ 1208 ICR_a139_farClutter 1;
BA_ "Confidence" SG_ 2026 ICR_matrixIndex 1;
BA_ "SystemSignalLongSymbol" SG_ 2026 ICR_a139_AbnormalBlockageDetecte "ICR_a139_AbnormalBlockageDetected";
BA_ "SystemSignalLongSymbol" SG_ 2026 ICR_a140_OccupancyExceptionEncou "ICR_a140_OccupancyExceptionEncountered";
BA_ "Confidence" SG_ 760 ICR_loggingCorrelationDBG 1;
BA_ "Confidence" SG_ 760 ICR_loggingTriggerRangeDBG 1;
BA_ "Confidence" SG_ 760 ICR_loggingTriggerXPosDBG 1;
BA_ "Confidence" SG_ 760 ICR_loggingTriggerYPosDBG 1;
BA_ "Confidence" SG_ 2025 ICR_occupancy1LRaw 0;
BA_ "GenSigSNA" SG_ 2025 ICR_occupancy1LRaw "3";
BA_ "Confidence" SG_ 2025 ICR_occupancy1RRaw 0;
BA_ "GenSigSNA" SG_ 2025 ICR_occupancy1RRaw "3";
BA_ "Confidence" SG_ 2025 ICR_occupancy1LVoteCnt 0;
BA_ "Confidence" SG_ 2025 ICR_occupancy1RVoteCnt 0;
BA_ "Confidence" SG_ 2025 ICR_userPresenceFilt 1;
BA_ "GenSigSNA" SG_ 2025 ICR_userPresenceFilt "3";
BA_ "Confidence" SG_ 2025 ICR_userPresenceRaw 1;
BA_ "GenSigSNA" SG_ 2025 ICR_userPresenceRaw "3";
BA_ "Confidence" SG_ 2025 ICR_occupancy1LFilt 1;
BA_ "GenSigSNA" SG_ 2025 ICR_occupancy1LFilt "3";
BA_ "Confidence" SG_ 2025 ICR_occupancy1RFilt 1;
BA_ "GenSigSNA" SG_ 2025 ICR_occupancy1RFilt "3";
BA_ "Confidence" SG_ 2025 ICR_occupancy2LFilt 1;
BA_ "GenSigSNA" SG_ 2025 ICR_occupancy2LFilt "3";
BA_ "Confidence" SG_ 2025 ICR_occupancy2CFilt 1;
BA_ "GenSigSNA" SG_ 2025 ICR_occupancy2CFilt "3";
BA_ "Confidence" SG_ 2025 ICR_occupancy2RFilt 1;
BA_ "GenSigSNA" SG_ 2025 ICR_occupancy2RFilt "3";
BA_ "Confidence" SG_ 2025 ICR_childPresenceFilt 1;
BA_ "GenSigSNA" SG_ 2025 ICR_childPresenceFilt "0";
BA_ "Confidence" SG_ 2025 ICR_childPresenceRaw 1;
BA_ "GenSigSNA" SG_ 2025 ICR_childPresenceRaw "0";
BA_ "Confidence" SG_ 2025 ICR_classification1LFilt 1;
BA_ "GenSigSNA" SG_ 2025 ICR_classification1LFilt "0";
BA_ "Confidence" SG_ 2025 ICR_classification1RqF 1;
BA_ "Confidence" SG_ 2025 ICR_occupancy1RFiltExp 1;
BA_ "GenSigSNA" SG_ 2025 ICR_occupancy1RFiltExp "3";
BA_ "Confidence" SG_ 670 ICR_userPresenceMLOutput 1;
BA_ "GenSigSNA" SG_ 670 ICR_userPresenceMLOutput "255";
BA_ "Confidence" SG_ 670 ICR_childPresenceMLOutput 1;
BA_ "GenSigSNA" SG_ 670 ICR_childPresenceMLOutput "255";
BA_ "Confidence" SG_ 670 ICR_classification1RFilt 1;
BA_ "GenSigSNA" SG_ 670 ICR_classification1RFilt "0";
BA_ "Confidence" SG_ 670 ICR_classification1LRaw 1;
BA_ "GenSigSNA" SG_ 670 ICR_classification1LRaw "0";
BA_ "Confidence" SG_ 670 ICR_classification1RRaw 1;
BA_ "GenSigSNA" SG_ 670 ICR_classification1RRaw "0";
BA_ "Confidence" SG_ 670 ICR_classification1LMLOutput 1;
BA_ "GenSigSNA" SG_ 670 ICR_classification1LMLOutput "255";
BA_ "Confidence" SG_ 670 ICR_classification1RMLOutput 1;
BA_ "GenSigSNA" SG_ 670 ICR_classification1RMLOutput "255";
BA_ "Confidence" SG_ 670 ICR_occupancy2Checksum 0;
BA_ "Confidence" SG_ 2023 ICR_sensorMode 1;
BA_ "Confidence" SG_ 2023 ICR_blocked 1;
BA_ "GenSigSNA" SG_ 2023 ICR_blocked "0";
BA_ "Confidence" SG_ 2023 ICR_algoVersion 1;
BA_ "Confidence" SG_ 2023 ICR_l2HeapUsage 1;
BA_ "Confidence" SG_ 2023 ICR_intrusionStatus 1;
BA_ "Confidence" SG_ 2023 ICR_booted 1;
BA_ "Confidence" SG_ 1624 ICR_udsResponseData 1;
BA_ "Confidence" SG_ 1470 IDB_alertID 1;
BA_ "Confidence" SG_ 1470 IDB_alertState 1;
BA_ "Confidence" SG_ 1470 IDB_a014_wheelSpeedSensorFreq 1;
BA_ "Confidence" SG_ 1470 IDB_a014_wheelSpeedSensorPhase 1;
BA_ "Confidence" SG_ 1470 IDB_a014_wheelSpeedSensorMisinst 1;
BA_ "SystemSignalLongSymbol" SG_ 1470 IDB_a014_wheelSpeedSensorMisinst "IDB_a014_wheelSpeedSensorMisinstallation";
BA_ "Confidence" SG_ 1470 IDB_a014_wheelSpeedSensorWrongEx 1;
BA_ "SystemSignalLongSymbol" SG_ 1470 IDB_a014_wheelSpeedSensorWrongEx "IDB_a014_wheelSpeedSensorWrongExciter";
BA_ "Confidence" SG_ 1470 IDB_a014_wheelSpeedSensorSpeedJu 1;
BA_ "SystemSignalLongSymbol" SG_ 1470 IDB_a014_wheelSpeedSensorSpeedJu "IDB_a014_wheelSpeedSensorSpeedJumpMinus";
BA_ "Confidence" SG_ 1470 IDB_a014_wheelSpeedSensorSp_0001 1;
BA_ "SystemSignalLongSymbol" SG_ 1470 IDB_a014_wheelSpeedSensorSp_0001 "IDB_a014_wheelSpeedSensorSpeedJumpPlus";
BA_ "Confidence" SG_ 1470 IDB_a014_wheelSpeedSensorAirGap 1;
BA_ "Confidence" SG_ 1470 IDB_a014_wheelSpeedSensorBIST 1;
BA_ "Confidence" SG_ 1470 IDB_a014_wheelSpeedSensorLeakage 1;
BA_ "SystemSignalLongSymbol" SG_ 1470 IDB_a014_wheelSpeedSensorLeakage "IDB_a014_wheelSpeedSensorLeakageCur";
BA_ "Confidence" SG_ 1470 IDB_a014_wheelSpeedSensorOverTem 1;
BA_ "SystemSignalLongSymbol" SG_ 1470 IDB_a014_wheelSpeedSensorOverTem "IDB_a014_wheelSpeedSensorOverTemp";
BA_ "Confidence" SG_ 1470 IDB_a014_wheelSpeedSensorSh_0001 1;
BA_ "SystemSignalLongSymbol" SG_ 1470 IDB_a014_wheelSpeedSensorSh_0001 "IDB_a014_wheelSpeedSensorShortToGnd";
BA_ "Confidence" SG_ 1470 IDB_a014_wheelSpeedSensorShortTo 1;
BA_ "SystemSignalLongSymbol" SG_ 1470 IDB_a014_wheelSpeedSensorShortTo "IDB_a014_wheelSpeedSensorShortToBat";
BA_ "Confidence" SG_ 1470 IDB_a014_wheelSpeedSensorOpen 1;
BA_ "Confidence" SG_ 1470 IDB_a015_wheelSpeedSensorFreq 1;
BA_ "Confidence" SG_ 1470 IDB_a015_wheelSpeedSensorPhase 1;
BA_ "Confidence" SG_ 1470 IDB_a015_wheelSpeedSensorMisinst 1;
BA_ "SystemSignalLongSymbol" SG_ 1470 IDB_a015_wheelSpeedSensorMisinst "IDB_a015_wheelSpeedSensorMisinstallation";
BA_ "Confidence" SG_ 1470 IDB_a015_wheelSpeedSensorWrongEx 1;
BA_ "SystemSignalLongSymbol" SG_ 1470 IDB_a015_wheelSpeedSensorWrongEx "IDB_a015_wheelSpeedSensorWrongExciter";
BA_ "Confidence" SG_ 1470 IDB_a015_wheelSpeedSensorSpeedJu 1;
BA_ "SystemSignalLongSymbol" SG_ 1470 IDB_a015_wheelSpeedSensorSpeedJu "IDB_a015_wheelSpeedSensorSpeedJumpMinus";
BA_ "Confidence" SG_ 1470 IDB_a015_wheelSpeedSensorSp_0001 1;
BA_ "SystemSignalLongSymbol" SG_ 1470 IDB_a015_wheelSpeedSensorSp_0001 "IDB_a015_wheelSpeedSensorSpeedJumpPlus";
BA_ "Confidence" SG_ 1470 IDB_a015_wheelSpeedSensorAirGap 1;
BA_ "Confidence" SG_ 1470 IDB_a015_wheelSpeedSensorBIST 1;
BA_ "Confidence" SG_ 1470 IDB_a015_wheelSpeedSensorLeakage 1;
BA_ "SystemSignalLongSymbol" SG_ 1470 IDB_a015_wheelSpeedSensorLeakage "IDB_a015_wheelSpeedSensorLeakageCur";
BA_ "Confidence" SG_ 1470 IDB_a015_wheelSpeedSensorOverTem 1;
BA_ "SystemSignalLongSymbol" SG_ 1470 IDB_a015_wheelSpeedSensorOverTem "IDB_a015_wheelSpeedSensorOverTemp";
BA_ "Confidence" SG_ 1470 IDB_a015_wheelSpeedSensorSh_0001 1;
BA_ "SystemSignalLongSymbol" SG_ 1470 IDB_a015_wheelSpeedSensorSh_0001 "IDB_a015_wheelSpeedSensorShortToGnd";
BA_ "Confidence" SG_ 1470 IDB_a015_wheelSpeedSensorShortTo 1;
BA_ "SystemSignalLongSymbol" SG_ 1470 IDB_a015_wheelSpeedSensorShortTo "IDB_a015_wheelSpeedSensorShortToBat";
BA_ "Confidence" SG_ 1470 IDB_a015_wheelSpeedSensorOpen 1;
BA_ "Confidence" SG_ 1470 IDB_a016_wheelSpeedSensorFreq 1;
BA_ "Confidence" SG_ 1470 IDB_a016_wheelSpeedSensorPhase 1;
BA_ "Confidence" SG_ 1470 IDB_a016_wheelSpeedSensorMisinst 1;
BA_ "SystemSignalLongSymbol" SG_ 1470 IDB_a016_wheelSpeedSensorMisinst "IDB_a016_wheelSpeedSensorMisinstallation";
BA_ "Confidence" SG_ 1470 IDB_a016_wheelSpeedSensorWrongEx 1;
BA_ "SystemSignalLongSymbol" SG_ 1470 IDB_a016_wheelSpeedSensorWrongEx "IDB_a016_wheelSpeedSensorWrongExciter";
BA_ "Confidence" SG_ 1470 IDB_a016_wheelSpeedSensorSpeedJu 1;
BA_ "SystemSignalLongSymbol" SG_ 1470 IDB_a016_wheelSpeedSensorSpeedJu "IDB_a016_wheelSpeedSensorSpeedJumpMinus";
BA_ "Confidence" SG_ 1470 IDB_a016_wheelSpeedSensorSp_0001 1;
BA_ "SystemSignalLongSymbol" SG_ 1470 IDB_a016_wheelSpeedSensorSp_0001 "IDB_a016_wheelSpeedSensorSpeedJumpPlus";
BA_ "Confidence" SG_ 1470 IDB_a016_wheelSpeedSensorAirGap 1;
BA_ "Confidence" SG_ 1470 IDB_a016_wheelSpeedSensorBIST 1;
BA_ "Confidence" SG_ 1470 IDB_a016_wheelSpeedSensorLeakage 1;
BA_ "SystemSignalLongSymbol" SG_ 1470 IDB_a016_wheelSpeedSensorLeakage "IDB_a016_wheelSpeedSensorLeakageCur";
BA_ "Confidence" SG_ 1470 IDB_a016_wheelSpeedSensorOverTem 1;
BA_ "SystemSignalLongSymbol" SG_ 1470 IDB_a016_wheelSpeedSensorOverTem "IDB_a016_wheelSpeedSensorOverTemp";
BA_ "Confidence" SG_ 1470 IDB_a016_wheelSpeedSensorSh_0001 1;
BA_ "SystemSignalLongSymbol" SG_ 1470 IDB_a016_wheelSpeedSensorSh_0001 "IDB_a016_wheelSpeedSensorShortToGnd";
BA_ "Confidence" SG_ 1470 IDB_a016_wheelSpeedSensorShortTo 1;
BA_ "SystemSignalLongSymbol" SG_ 1470 IDB_a016_wheelSpeedSensorShortTo "IDB_a016_wheelSpeedSensorShortToBat";
BA_ "Confidence" SG_ 1470 IDB_a016_wheelSpeedSensorOpen 1;
BA_ "Confidence" SG_ 1470 IDB_a017_wheelSpeedSensorFreq 1;
BA_ "Confidence" SG_ 1470 IDB_a017_wheelSpeedSensorPhase 1;
BA_ "Confidence" SG_ 1470 IDB_a017_wheelSpeedSensorMisinst 1;
BA_ "SystemSignalLongSymbol" SG_ 1470 IDB_a017_wheelSpeedSensorMisinst "IDB_a017_wheelSpeedSensorMisinstallation";
BA_ "Confidence" SG_ 1470 IDB_a017_wheelSpeedSensorWrongEx 1;
BA_ "SystemSignalLongSymbol" SG_ 1470 IDB_a017_wheelSpeedSensorWrongEx "IDB_a017_wheelSpeedSensorWrongExciter";
BA_ "Confidence" SG_ 1470 IDB_a017_wheelSpeedSensorSpeedJu 1;
BA_ "SystemSignalLongSymbol" SG_ 1470 IDB_a017_wheelSpeedSensorSpeedJu "IDB_a017_wheelSpeedSensorSpeedJumpMinus";
BA_ "Confidence" SG_ 1470 IDB_a017_wheelSpeedSensorSp_0001 1;
BA_ "SystemSignalLongSymbol" SG_ 1470 IDB_a017_wheelSpeedSensorSp_0001 "IDB_a017_wheelSpeedSensorSpeedJumpPlus";
BA_ "Confidence" SG_ 1470 IDB_a017_wheelSpeedSensorAirGap 1;
BA_ "Confidence" SG_ 1470 IDB_a017_wheelSpeedSensorBIST 1;
BA_ "Confidence" SG_ 1470 IDB_a017_wheelSpeedSensorLeakage 1;
BA_ "SystemSignalLongSymbol" SG_ 1470 IDB_a017_wheelSpeedSensorLeakage "IDB_a017_wheelSpeedSensorLeakageCur";
BA_ "Confidence" SG_ 1470 IDB_a017_wheelSpeedSensorOverTem 1;
BA_ "SystemSignalLongSymbol" SG_ 1470 IDB_a017_wheelSpeedSensorOverTem "IDB_a017_wheelSpeedSensorOverTemp";
BA_ "Confidence" SG_ 1470 IDB_a017_wheelSpeedSensorSh_0001 1;
BA_ "SystemSignalLongSymbol" SG_ 1470 IDB_a017_wheelSpeedSensorSh_0001 "IDB_a017_wheelSpeedSensorShortToGnd";
BA_ "Confidence" SG_ 1470 IDB_a017_wheelSpeedSensorShortTo 1;
BA_ "SystemSignalLongSymbol" SG_ 1470 IDB_a017_wheelSpeedSensorShortTo "IDB_a017_wheelSpeedSensorShortToBat";
BA_ "Confidence" SG_ 1470 IDB_a017_wheelSpeedSensorOpen 1;
BA_ "Confidence" SG_ 1470 IDB_a020_canSignalValidity 1;
BA_ "Confidence" SG_ 1470 IDB_a020_signalValueCrosscheck 1;
BA_ "Confidence" SG_ 1470 IDB_a030_primaryExternalCircuitL 1;
BA_ "SystemSignalLongSymbol" SG_ 1470 IDB_a030_primaryExternalCircuitL "IDB_a030_primaryExternalCircuitLeakage";
BA_ "Confidence" SG_ 1470 IDB_a030_secondaryExternalCircui 1;
BA_ "SystemSignalLongSymbol" SG_ 1470 IDB_a030_secondaryExternalCircui "IDB_a030_secondaryExternalCircuitLeakage";
BA_ "Confidence" SG_ 1470 IDB_a030_primaryChamberInternalL 1;
BA_ "SystemSignalLongSymbol" SG_ 1470 IDB_a030_primaryChamberInternalL "IDB_a030_primaryChamberInternalLeakage";
BA_ "Confidence" SG_ 1470 IDB_a030_syncModeInternalLeakage 1;
BA_ "Confidence" SG_ 1470 IDB_a030_secondaryChamberInterna 1;
BA_ "SystemSignalLongSymbol" SG_ 1470 IDB_a030_secondaryChamberInterna "IDB_a030_secondaryChamberInternalLeakage";
BA_ "Confidence" SG_ 1470 IDB_a030_masterCylinderInternalL 1;
BA_ "SystemSignalLongSymbol" SG_ 1470 IDB_a030_masterCylinderInternalL "IDB_a030_masterCylinderInternalLeakage";
BA_ "Confidence" SG_ 1470 IDB_a060_validityOnChassisBus 1;
BA_ "Confidence" SG_ 1470 IDB_a060_validityOnPartyBus 1;
BA_ "Confidence" SG_ 1470 IDB_a061_validityOnChassisBus 1;
BA_ "Confidence" SG_ 1470 IDB_a061_validityOnPartyBus 1;
BA_ "Confidence" SG_ 1470 IDB_a062_validityOnChassisBus 1;
BA_ "Confidence" SG_ 1470 IDB_a062_validityOnPartyBus 1;
BA_ "Confidence" SG_ 1470 IDB_a063_validityOnChassisBus 1;
BA_ "Confidence" SG_ 1470 IDB_a063_validityOnPartyBus 1;
BA_ "Confidence" SG_ 1470 IDB_a064_validityOnChassisBus 1;
BA_ "Confidence" SG_ 1470 IDB_a064_validityOnPartyBus 1;
BA_ "Confidence" SG_ 1470 IDB_a065_validityOnChassisBus 1;
BA_ "Confidence" SG_ 1470 IDB_a065_validityOnPartyBus 1;
BA_ "Confidence" SG_ 1470 IDB_a106_qualifierValidity 1;
BA_ "Confidence" SG_ 1470 IDB_a106_signalNotAvailable 1;
BA_ "Confidence" SG_ 1470 IDB_a107_qualifierValidity 1;
BA_ "Confidence" SG_ 1470 IDB_a107_signalNotAvailable 1;
BA_ "Confidence" SG_ 1470 IDB_a112_qualifierValidity 1;
BA_ "Confidence" SG_ 1470 IDB_a112_signalNotAvailable 1;
BA_ "Confidence" SG_ 1470 IDB_a113_qualifierValidity 1;
BA_ "Confidence" SG_ 1470 IDB_a113_signalNotAvailable 1;
BA_ "Confidence" SG_ 1470 IDB_a114_qualifierValidity 1;
BA_ "Confidence" SG_ 1470 IDB_a114_signalNotAvailable 1;
BA_ "Confidence" SG_ 1470 IDB_a126_PMebrCmdStateValidity 1;
BA_ "Confidence" SG_ 1470 IDB_a126_PMstate2Validity 1;
BA_ "Confidence" SG_ 1470 IDB_a126_PMstate2Missing 1;
BA_ "Confidence" SG_ 1470 IDB_a126_DIchassisControlValidit 1;
BA_ "SystemSignalLongSymbol" SG_ 1470 IDB_a126_DIchassisControlValidit "IDB_a126_DIchassisControlValidity";
BA_ "Confidence" SG_ 1470 IDB_a126_DIchassisControlMissing 1;
BA_ "Confidence" SG_ 1470 IDB_a126_DIrequestActiveValidity 1;
BA_ "Confidence" SG_ 1470 IDB_a129_validityOnChassisBus 1;
BA_ "Confidence" SG_ 1470 IDB_a129_validityOnPartyBus 1;
BA_ "Confidence" SG_ 1470 IDB_a130_PMbrakePedalCmdQFValidi 1;
BA_ "SystemSignalLongSymbol" SG_ 1470 IDB_a130_PMbrakePedalCmdQFValidi "IDB_a130_PMbrakePedalCmdQFValidity";
BA_ "Confidence" SG_ 1470 IDB_a130_PMstate2Validity 1;
BA_ "Confidence" SG_ 1470 IDB_a130_PMstate2Missing 1;
BA_ "Confidence" SG_ 1470 IDB_a130_DIbrakeCommandValidity 1;
BA_ "Confidence" SG_ 1470 IDB_a130_DIbrakeCommandMissing 1;
BA_ "Confidence" SG_ 1470 IDB_a130_DIbrakeTorqueCommandFul 1;
BA_ "SystemSignalLongSymbol" SG_ 1470 IDB_a130_DIbrakeTorqueCommandFul "IDB_a130_DIbrakeTorqueCommandFullSNA";
BA_ "Confidence" SG_ 1470 IDB_a130_DIbrakeTorqueComma_0001 1;
BA_ "SystemSignalLongSymbol" SG_ 1470 IDB_a130_DIbrakeTorqueComma_0001 "IDB_a130_DIbrakeTorqueCommandFullTooLow";
BA_ "Confidence" SG_ 1470 IDB_a132_validityOnChassisBus 1;
BA_ "Confidence" SG_ 1470 IDB_a132_validityOnPartyBus 1;
BA_ "Confidence" SG_ 983 IDB_matrixIndex 1;
BA_ "SystemSignalLongSymbol" SG_ 983 IDB_a070_DIchassisControlChecksu "IDB_a070_DIchassisControlChecksum";
BA_ "SystemSignalLongSymbol" SG_ 983 IDB_a119_VCLEFTepbmStatusChecksu "IDB_a119_VCLEFTepbmStatusChecksum";
BA_ "SystemSignalLongSymbol" SG_ 983 IDB_a129_RCUinputRodStrokeInvali "IDB_a129_RCUinputRodStrokeInvalid";
BA_ "SystemSignalLongSymbol" SG_ 983 IDB_a130_DIfullTorqueRequestInva "IDB_a130_DIfullTorqueRequestInvalid";
BA_ "SystemSignalLongSymbol" SG_ 983 IDB_a132_RCUinputRodStrokeQFInva "IDB_a132_RCUinputRodStrokeQFInvalid";
BA_ "SystemSignalLongSymbol" SG_ 983 IDB_a138_DIbrakeTorqueCommandAnd "IDB_a138_DIbrakeTorqueCommandAndFlagMismatch";
BA_ "SystemSignalLongSymbol" SG_ 983 IDB_a139_DIbrakeTorqueCommandFul "IDB_a139_DIbrakeTorqueCommandFullSNA";
BA_ "SystemSignalLongSymbol" SG_ 983 IDB_a140_PMbrakePedalCmdQFInvali "IDB_a140_PMbrakePedalCmdQFInvalid";
BA_ "SystemSignalLongSymbol" SG_ 983 IDB_a141_DIbrakeTorqueCommandFul "IDB_a141_DIbrakeTorqueCommandFullTooLow";
BA_ "SystemSignalLongSymbol" SG_ 983 IDB_a144_hydraulicPushthroughAct "IDB_a144_hydraulicPushthroughActive";
BA_ "Confidence" SG_ 1429 OCS1P_alertID 1;
BA_ "Confidence" SG_ 1429 OCS1P_alertState 1;
BA_ "Confidence" SG_ 767 OCS1P_matrixIndex 1;
BA_ "SystemSignalLongSymbol" SG_ 767 OCS1P_w148_classificationMismatc "OCS1P_w148_classificationMismatch";
BA_ "Confidence" SG_ 766 OCS1P_infoIndex 1;
BA_ "Confidence" SG_ 766 OCS1P_infoBuildType 0;
BA_ "Confidence" SG_ 766 OCS1P_infoBuildConfigID 0;
BA_ "Confidence" SG_ 766 OCS1P_infoHardwareID 0;
BA_ "Confidence" SG_ 766 OCS1P_infoComponentID 0;
BA_ "Confidence" SG_ 766 OCS1P_infoPcbaID 0;
BA_ "Confidence" SG_ 766 OCS1P_infoAssemblyID 0;
BA_ "Confidence" SG_ 766 OCS1P_infoUsageID 0;
BA_ "Confidence" SG_ 766 OCS1P_infoSubUsageID 0;
BA_ "Confidence" SG_ 766 OCS1P_infoApplicationCRC 0;
BA_ "Confidence" SG_ 766 OCS1P_infoBootSvnRev 0;
BA_ "Confidence" SG_ 766 OCS1P_infoAppGitHashBytes 0;
BA_ "Confidence" SG_ 766 OCS1P_infoBootGitHashBytes 0;
BA_ "Confidence" SG_ 766 OCS1P_infoPlatformType 0;
BA_ "Confidence" SG_ 766 OCS1P_infoBootUdsProtoVersion 0;
BA_ "Confidence" SG_ 766 OCS1P_infoBootloaderCRC 0;
VAL_ 938 HVP_matrixIndex 1 "AlertMatrix1" 0 "AlertMatrix0" ;
VAL_ 522 HVP_packContNegativeState 7 "CONTACTOR_STATE_WELDED" 6 "CONTACTOR_STATE_ECONOMIZED" 5 "CONTACTOR_STATE_OPENING" 4 "CONTACTOR_STATE_PULLED_IN" 3 "CONTACTOR_STATE_BLOCKED" 2 "CONTACTOR_STATE_PRECHARGE" 1 "CONTACTOR_STATE_OPEN" 0 "CONTACTOR_STATE_SNA" ;
VAL_ 522 HVP_packContPositiveState 7 "CONTACTOR_STATE_WELDED" 6 "CONTACTOR_STATE_ECONOMIZED" 5 "CONTACTOR_STATE_OPENING" 4 "CONTACTOR_STATE_PULLED_IN" 3 "CONTACTOR_STATE_BLOCKED" 2 "CONTACTOR_STATE_PRECHARGE" 1 "CONTACTOR_STATE_OPEN" 0 "CONTACTOR_STATE_SNA" ;
VAL_ 522 HVP_packContactorSetState 9 "CONTACTOR_SET_STATE_NEGATIVE_CLOSED" 8 "CONTACTOR_SET_STATE_POSITIVE_CLOSED" 7 "CONTACTOR_SET_STATE_WELDED" 6 "CONTACTOR_SET_STATE_PARTIAL_WELD" 5 "CONTACTOR_SET_STATE_CLOSED" 4 "CONTACTOR_SET_STATE_OPENING" 3 "CONTACTOR_SET_STATE_BLOCKED" 2 "CONTACTOR_SET_STATE_CLOSING" 1 "CONTACTOR_SET_STATE_OPEN" 0 "CONTACTOR_SET_STATE_SNA" ;
VAL_ 522 HVP_fcContNegativeState 7 "CONTACTOR_STATE_WELDED" 6 "CONTACTOR_STATE_ECONOMIZED" 5 "CONTACTOR_STATE_OPENING" 4 "CONTACTOR_STATE_PULLED_IN" 3 "CONTACTOR_STATE_BLOCKED" 2 "CONTACTOR_STATE_PRECHARGE" 1 "CONTACTOR_STATE_OPEN" 0 "CONTACTOR_STATE_SNA" ;
VAL_ 522 HVP_fcContPositiveState 7 "CONTACTOR_STATE_WELDED" 6 "CONTACTOR_STATE_ECONOMIZED" 5 "CONTACTOR_STATE_OPENING" 4 "CONTACTOR_STATE_PULLED_IN" 3 "CONTACTOR_STATE_BLOCKED" 2 "CONTACTOR_STATE_PRECHARGE" 1 "CONTACTOR_STATE_OPEN" 0 "CONTACTOR_STATE_SNA" ;
VAL_ 522 HVP_fcContactorSetState 9 "CONTACTOR_SET_STATE_NEGATIVE_CLOSED" 8 "CONTACTOR_SET_STATE_POSITIVE_CLOSED" 7 "CONTACTOR_SET_STATE_WELDED" 6 "CONTACTOR_SET_STATE_PARTIAL_WELD" 5 "CONTACTOR_SET_STATE_CLOSED" 4 "CONTACTOR_SET_STATE_OPENING" 3 "CONTACTOR_SET_STATE_BLOCKED" 2 "CONTACTOR_SET_STATE_CLOSING" 1 "CONTACTOR_SET_STATE_OPEN" 0 "CONTACTOR_SET_STATE_SNA" ;
VAL_ 522 HVP_fcCtrsRequestStatus 2 "REQUEST_COMPLETED" 1 "REQUEST_ACTIVE" 0 "REQUEST_NOT_ACTIVE" ;
VAL_ 522 HVP_packCtrsRequestStatus 2 "REQUEST_COMPLETED" 1 "REQUEST_ACTIVE" 0 "REQUEST_NOT_ACTIVE" ;
VAL_ 522 HVP_hvilDiag 14 "SNA" 13 "PM_OPEN_FAULT" 12 "DI_OPEN_FAULT" 11 "PM_STATUS_MISSING_FAULT" 10 "DI_STATUS_MISSING_FAULT" 9 "VEHICLE_OR_PENTHOUSE_LID_OPEN_FAULT" 8 "NO_12V_SUPPLY" 7 "VEHICLE_NODE_FAULT" 6 "UNKNOWN_LOCATION_OPEN_FAULT" 5 "PENTHOUSE_LID_OPEN_FAULT" 4 "VEHICLE_OPEN_FAULT" 3 "INTERNAL_OPEN_FAULT" 2 "CURRENT_SOURCE_OR_GROUND_LEAK_FAULT" 1 "OK" 0 "UNKNOWN" ;
VAL_ 522 HVP_fcLinkAllowedToEnergize 2 "FC_LINK_ENERGY_DC" 1 "FC_LINK_ENERGY_AC" 0 "FC_LINK_ENERGY_NONE" ;
VAL_ 1962 HVP_debugMessageMultiplexer 12 "Mux12" 11 "Mux11" 10 "Mux10" 9 "Mux9" 8 "Mux8" 7 "Mux7" 6 "Mux6" 5 "Mux5" 4 "Mux4" 3 "Mux3" 2 "Mux2" 1 "Mux1" 0 "Mux0" ;
VAL_ 1962 HVP_ecuLogUploadRequest 3 "REQUEST_PRIORITY_3" 2 "REQUEST_PRIORITY_2" 1 "REQUEST_PRIORITY_1" 0 "REQUEST_PRIORITY_NONE" ;
VAL_ 1666 HVP_hvilStatus 2 "FAULT" 1 "OK" 0 "UNKNOWN" ;
VAL_ 861 IBST_matrixIndex 3 "AlertMatrix3" 2 "AlertMatrix2" 1 "AlertMatrix1" 0 "AlertMatrix0" ;
VAL_ 1208 ICR_alertID 142 "a142_ModeOverrideActive" 141 "a141_RequiresReplacement" 140 "a140_OccupancyExceptionEncountered" 139 "a139_AbnormalBlockageDetected" 138 "a138_DriverSideMismatch" 137 "a137_radarBlocked" 136 "a136_radarHighTemperature" 135 "a135_radarTxBallBreak" 134 "a134_radarPgood" 133 "a133_radarBlocked" 64 "a064_busSleepReqTimeout" 63 "a063_SwitchFault" 62 "a062_XCPWasConnected" 61 "a061_XCPConnected" 60 "a060_engineeringBuild" 59 "a059_inputResistanceHigh" 58 "a058_inputRHighSyncDebug" 46 "a046_Task1000msError" 45 "a045_Task100msError" 44 "a044_Task10msError" 43 "a043_Task1msError" 42 "a042_HighStackUsage" 41 "a041_HighCPULoad" 31 "a031_UDSActive" 30 "a030_ECULogUploadRequest" 29 "a029_CoreDump" 22 "a022_TaskInitError" 21 "a021_TaskSchedulerError" 16 "a016_NVMMRecordError" 15 "a015_NVMMError" 13 "a013_AlertManagerFault" 12 "a012_CPUReset" 6 "a006_CANTX_cyclicError" 5 "a005_CANTXError" 3 "a003_SWAssertion" 2 "a002_PowerLossReset" 1 "a001_WatchdogReset" 0 "ALERT_DO_NOT_USE_ZERO" ;
VAL_ 1208 ICR_alertState 1 "SET" 0 "CLEARED" ;
VAL_ 2026 ICR_matrixIndex 2 "AlertMatrix2" 1 "AlertMatrix1" 0 "AlertMatrix0" ;
VAL_ 2025 ICR_occupancy1LRaw 3 "SBRStatus_SEAT_SNA" 2 "SBRStatus_SEAT_FAULTED" 1 "SBRStatus_SEAT_OCCUPIED" 0 "SBRStatus_SEAT_UNOCCUPIED" ;
VAL_ 2025 ICR_occupancy1RRaw 3 "SBRStatus_SEAT_SNA" 2 "SBRStatus_SEAT_FAULTED" 1 "SBRStatus_SEAT_OCCUPIED" 0 "SBRStatus_SEAT_UNOCCUPIED" ;
VAL_ 2025 ICR_userPresenceFilt 3 "SBRStatus_SEAT_SNA" 2 "SBRStatus_SEAT_FAULTED" 1 "SBRStatus_SEAT_OCCUPIED" 0 "SBRStatus_SEAT_UNOCCUPIED" ;
VAL_ 2025 ICR_userPresenceRaw 3 "SBRStatus_SEAT_SNA" 2 "SBRStatus_SEAT_FAULTED" 1 "SBRStatus_SEAT_OCCUPIED" 0 "SBRStatus_SEAT_UNOCCUPIED" ;
VAL_ 2025 ICR_occupancy1LFilt 3 "SBRStatus_SEAT_SNA" 2 "SBRStatus_SEAT_FAULTED" 1 "SBRStatus_SEAT_OCCUPIED" 0 "SBRStatus_SEAT_UNOCCUPIED" ;
VAL_ 2025 ICR_occupancy1RFilt 3 "SBRStatus_SEAT_SNA" 2 "SBRStatus_SEAT_FAULTED" 1 "SBRStatus_SEAT_OCCUPIED" 0 "SBRStatus_SEAT_UNOCCUPIED" ;
VAL_ 2025 ICR_occupancy2LFilt 3 "SBRStatus_SEAT_SNA" 2 "SBRStatus_SEAT_FAULTED" 1 "SBRStatus_SEAT_OCCUPIED" 0 "SBRStatus_SEAT_UNOCCUPIED" ;
VAL_ 2025 ICR_occupancy2CFilt 3 "SBRStatus_SEAT_SNA" 2 "SBRStatus_SEAT_FAULTED" 1 "SBRStatus_SEAT_OCCUPIED" 0 "SBRStatus_SEAT_UNOCCUPIED" ;
VAL_ 2025 ICR_occupancy2RFilt 3 "SBRStatus_SEAT_SNA" 2 "SBRStatus_SEAT_FAULTED" 1 "SBRStatus_SEAT_OCCUPIED" 0 "SBRStatus_SEAT_UNOCCUPIED" ;
VAL_ 2025 ICR_childPresenceFilt 2 "DETECTED" 1 "NOT_DETECTED" 0 "DETECTED_SNA" ;
VAL_ 2025 ICR_childPresenceRaw 2 "DETECTED" 1 "NOT_DETECTED" 0 "DETECTED_SNA" ;
VAL_ 2025 ICR_classification1LFilt 4 "OCCUPANT_CLASSIFICATION_OCCUPIED_ALLOW" 3 "OCCUPANT_CLASSIFICATION_OCCUPIED_INHIBIT" 2 "OCCUPANT_CLASSIFICATION_EMPTY" 1 "OCCUPANT_CLASSIFICATION_INIT" 0 "OCCUPANT_CLASSIFICATION_SNA" ;
VAL_ 2025 ICR_classification1RqF 1 "OCCUPANT_CLASSIFICATION_NOT_FAULTED" 0 "OCCUPANT_CLASSIFICATION_FAULTED" ;
VAL_ 2025 ICR_occupancy1RFiltExp 3 "SBRStatus_SEAT_SNA" 2 "SBRStatus_SEAT_FAULTED" 1 "SBRStatus_SEAT_OCCUPIED" 0 "SBRStatus_SEAT_UNOCCUPIED" ;
VAL_ 670 ICR_userPresenceMLOutput 255 "SNA" ;
VAL_ 670 ICR_childPresenceMLOutput 255 "SNA" ;
VAL_ 670 ICR_classification1RFilt 4 "OCCUPANT_CLASSIFICATION_OCCUPIED_ALLOW" 3 "OCCUPANT_CLASSIFICATION_OCCUPIED_INHIBIT" 2 "OCCUPANT_CLASSIFICATION_EMPTY" 1 "OCCUPANT_CLASSIFICATION_INIT" 0 "OCCUPANT_CLASSIFICATION_SNA" ;
VAL_ 670 ICR_classification1LRaw 4 "OCCUPANT_CLASSIFICATION_OCCUPIED_ALLOW" 3 "OCCUPANT_CLASSIFICATION_OCCUPIED_INHIBIT" 2 "OCCUPANT_CLASSIFICATION_EMPTY" 1 "OCCUPANT_CLASSIFICATION_INIT" 0 "OCCUPANT_CLASSIFICATION_SNA" ;
VAL_ 670 ICR_classification1RRaw 4 "OCCUPANT_CLASSIFICATION_OCCUPIED_ALLOW" 3 "OCCUPANT_CLASSIFICATION_OCCUPIED_INHIBIT" 2 "OCCUPANT_CLASSIFICATION_EMPTY" 1 "OCCUPANT_CLASSIFICATION_INIT" 0 "OCCUPANT_CLASSIFICATION_SNA" ;
VAL_ 670 ICR_classification1LMLOutput 255 "SNA" ;
VAL_ 670 ICR_classification1RMLOutput 255 "SNA" ;
VAL_ 2023 ICR_sensorMode 15 "ICR_SENSOR_INTERFACE_MODE_ERROR" 7 "ICR_SENSOR_INTERFACE_MODE_LPM_TEST" 6 "ICR_SENSOR_INTERFACE_MODE_OCCUPANCY_DETECTION" 5 "ICR_SENSOR_INTERFACE_MODE_HPM_TEST" 4 "ICR_SENSOR_INTERFACE_MODE_CALIBRATION" 3 "ICR_SENSOR_INTERFACE_MODE_CW" 2 "ICR_SENSOR_MODE_END_OF_LINE_TEST" 1 "ICR_SENSOR_MODE_INTRUSTION" 0 "ICR_SENSOR_MODE_SENSOR_STOPPED" ;
VAL_ 2023 ICR_blocked 2 "ICR_BLOCKED_TRUE" 1 "ICR_BLOCKED_FALSE" 0 "ICR_BLOCKED_SNA" ;
VAL_ 2023 ICR_algoVersion 37 "ICR_ALGO_VERSION_FUTURE_RELEASE_37" 36 "ICR_ALGO_VERSION_v06112025" 35 "ICR_ALGO_VERSION_v04232025" 34 "ICR_ALGO_VERSION_v03192025" 33 "ICR_ALGO_VERSION_v02142025" 32 "ICR_ALGO_VERSION_v01222025" 31 "ICR_ALGO_VERSION_v10072024" 30 "ICR_ALGO_VERSION_v08282024" 29 "ICR_ALGO_VERSION_v07172024" 28 "ICR_ALGO_VERSION_v06122024" 27 "ICR_ALGO_VERSION_v04242024" 26 "ICR_ALGO_VERSION_v03142024" 25 "ICR_ALGO_VERSION_v01312024" 24 "ICR_ALGO_VERSION_v12192023" 23 "ICR_ALGO_VERSION_v10252023" 22 "ICR_ALGO_VERSION_v10112023" 21 "ICR_ALGO_VERSION_v09222023" 20 "ICR_ALGO_VERSION_V08302023" 19 "ICR_ALGO_VERSION_V07172023" 18 "ICR_ALGO_VERSION_V06152023" 17 "ICR_ALGO_VERSION_V06072023" 16 "ICR_ALGO_VERSION_V05192023" 15 "ICR_ALGO_VERSION_V04262023" 14 "ICR_ALGO_VERSION_V1222" 13 "ICR_ALGO_VERSION_V1125" 12 "ICR_ALGO_VERSION_V1118" 11 "ICR_ALGO_VERSION_V1103" 10 "ICR_ALGO_VERSION_V1013" 9 "ICR_ALGO_VERSION_V1006" 8 "ICR_ALGO_VERSION_V927" 7 "ICR_ALGO_VERSION_V902" 6 "ICR_ALGO_VERSION_V826" 5 "ICR_ALGO_VERSION_V803" 4 "ICR_ALGO_VERSION_V715" 3 "ICR_ALGO_VERSION_V711" 2 "ICR_ALGO_VERSION_V204" 1 "ICR_ALGO_VERSION_EXPERIMENTAL" 0 "ICR_ALGO_VERSION_NONE" ;
VAL_ 2023 ICR_intrusionStatus 2 "INSTRUSION_STATUS_INTRUSION_DETECTED" 1 "INSTRUSION_STATUS_NONE" 0 "INSTRUSION_STATUS_UNKNOWN" ;
VAL_ 1470 IDB_alertID 144 "a144_hydraulicPushthroughActive" 143 "a143_factoryModeActive" 142 "a142_PMebrCmdStateInvalid" 141 "a141_DIbrakeTorqueCommandFullTooLow" 140 "a140_PMbrakePedalCmdQFInvalid" 139 "a139_DIbrakeTorqueCommandFullSNA" 138 "a138_DIbrakeTorqueCommandAndFlagMismatch" 137 "a137_VCLEFTcdpRequestInvalid" 136 "a136_RCUptsCalMissing" 135 "a135_DIbrakeCommandChecksum" 134 "a134_DIbrakeCommandCounter" 133 "a133_DIbrakeCommandDLC" 132 "a132_RCUinputRodStrokeQFInvalid" 131 "a131_DIfullTorquePathActive" 130 "a130_DIfullTorqueRequestInvalid" 129 "a129_RCUinputRodStrokeInvalid" 128 "a128_reserved1" 127 "a127_brakeFluidLevelInvalid" 126 "a126_DItorqueRequestInvalid" 125 "a125_PMvdcCmdStateInvalid" 124 "a124_VCFRONTtempInvalid" 123 "a123_DIRtorqueCommandInvalid" 122 "a122_DIFtorqueCommandInvalid" 121 "a121_dynoModeActive" 120 "a120_EPAS3Pinvalid" 119 "a119_VCLEFTepbmStatusChecksum" 118 "a118_VCLEFTepbmStatusCounter" 117 "a117_VCLEFTepbmStatusDLC" 116 "a116_VCFRONTsensorsDLC" 115 "a115_VCFRONTespLvStInvalid" 114 "a114_longAccelInvalid" 113 "a113_latAccelInvalid" 112 "a112_yawRateInvalid" 111 "a111_EPBstatusChecksum" 110 "a110_EPBstatusCounter" 109 "a109_BDWsignalInvalid" 108 "a108_EPBstatusDLC" 107 "a107_DIRtorqueInvalid" 106 "a106_DIFtorqueInvalid" 105 "a105_DIgearInvalid" 104 "a104_DIaccelPosInvalid" 103 "a103_DIfullTorquePathFaulted" 102 "a102_bdwRequestActiveInvalid" 101 "a101_RCMcollisionCounter" 100 "a100_RCMcollisionChecksum" 99 "a099_RCMcollisionDLC" 98 "a098_VCFRONTLVPwrStCounter" 97 "a097_VCFRONTLVPwrStChecksum" 96 "a096_VCFRONTLVPowerStateDLC" 95 "a095_RCMinertial2Counter" 94 "a094_RCMinertial2Checksum" 93 "a093_RCMinertial2DLC" 92 "a092_RCMinertial1Counter" 91 "a091_RCMinertial1Checksum" 90 "a090_RCMinertial1DLC" 89 "a089_PMstate2Counter" 88 "a088_PMstate2Checksum" 87 "a087_PMstate2DLC" 86 "a086_EPAS3PsysStatusCounter" 85 "a085_EPAS3PsysStatusChecksum" 84 "a084_EPAS3PsysStatusDLC" 83 "a083_DIvdcRightCounter" 82 "a082_DIvdcRightChecksum" 81 "a081_DIvdcRightDLC" 80 "a080_DIvdcLeftCounter" 79 "a079_DIvdcLeftChecksum" 78 "a078_DIvdcLeftDLC" 77 "a077_DIRtorqueCounter" 76 "a076_DIRtorqueChecksum" 75 "a075_DIRtorqueDLC" 74 "a074_DIsystemStatusCounter" 73 "a073_DIsystemStatusChecksum" 72 "a072_DIsystemStatusDLC" 71 "a071_DIchassisControlCounter" 70 "a070_DIchassisControlChecksum" 69 "a069_DIchassisControlDLC" 68 "a068_DIFtorqueCounter" 67 "a067_DIFtorqueChecksum" 66 "a066_DIFtorqueDLC" 65 "a065_RCUactuationCounter" 64 "a064_RCUactuationChecksum" 63 "a063_RCUactuationDLC" 62 "a062_RCUstatusCounter" 61 "a061_RCUstatusChecksum" 60 "a060_RCUstatusDLC" 59 "a059_cdpFaulted" 58 "a058_scmFaulted" 57 "a057_bdwRequestInvalid" 56 "a056_fadeCompensationFaulted" 55 "a055_panicBrakeAssistFaulted" 54 "a054_skidDetectionFaulted" 53 "a053_DItorquePathFaulted" 52 "a052_vdcFaulted" 51 "a051_ebdFaulted" 50 "a050_absFaulted" 49 "a049_cdpActive" 48 "a048_scmActive" 47 "a047_brakeDiscWipeActive" 46 "a046_fadeCompensationActive" 45 "a045_panicBrakeAssistActive" 44 "a044_standstillSkidDetected" 43 "a043_DItorquePathActive" 42 "a042_btcActive" 41 "a041_vdcActive" 40 "a040_ebdActive" 39 "a039_absActive" 38 "a038_motorInitFault" 37 "a037_chassisBusOff" 36 "a036_partyBusOff" 35 "a035_motorStuck" 34 "a034_motorPositionSetFault" 33 "a033_motorHardOverheat" 32 "a032_motorSoftOverheat" 31 "a031_solenoidValveStuck" 30 "a030_fluidLeakDetected" 29 "a029_pressureSensNotCal" 28 "a028_simPresSensorFault" 27 "a027_circuitPresSensorFault" 26 "a026_axImplausible" 25 "a025_ayImplausible" 24 "a024_yawImplausible" 23 "a023_steeringImplausible" 22 "a022_brakeFluidLow" 21 "a021_pedalSensorNotCal" 20 "a020_RCUpedalTravelMismatch" 19 "a019_pedalSensorFault" 18 "a018_WSSGenericFault" 17 "a017_ReRWSSFault" 16 "a016_ReLWSSFault" 15 "a015_FrRWSSFault" 14 "a014_FrLWSSFault" 13 "a013_motorPosSensorFault" 12 "a012_motorGenericFault" 11 "a011_solenoidValveFault" 10 "a010_asicGenericFault" 9 "a009_asicBoostFault" 8 "a008_motorPowerOpen" 7 "a007_wakeLineOpen" 6 "a006_supplyHardUndervoltage" 5 "a005_supplyMidUndervoltage" 4 "a004_supplyUndervoltage" 3 "a003_supplyHardOvervoltage" 2 "a002_supplyOvervoltage" 1 "a001_mcuGenericFault" 0 "ALERT_DO_NOT_USE_ZERO" ;
VAL_ 1470 IDB_alertState 1 "SET" 0 "CLEARED" ;
VAL_ 1470 IDB_a014_wheelSpeedSensorFreq 1 "NOT_OK" 0 "OK" ;
VAL_ 1470 IDB_a014_wheelSpeedSensorPhase 1 "NOT_OK" 0 "OK" ;
VAL_ 1470 IDB_a014_wheelSpeedSensorMisinst 1 "NOT_OK" 0 "OK" ;
VAL_ 1470 IDB_a014_wheelSpeedSensorWrongEx 1 "NOT_OK" 0 "OK" ;
VAL_ 1470 IDB_a014_wheelSpeedSensorSpeedJu 1 "NOT_OK" 0 "OK" ;
VAL_ 1470 IDB_a014_wheelSpeedSensorSp_0001 1 "NOT_OK" 0 "OK" ;
VAL_ 1470 IDB_a014_wheelSpeedSensorAirGap 1 "NOT_OK" 0 "OK" ;
VAL_ 1470 IDB_a014_wheelSpeedSensorBIST 1 "NOT_OK" 0 "OK" ;
VAL_ 1470 IDB_a014_wheelSpeedSensorLeakage 1 "NOT_OK" 0 "OK" ;
VAL_ 1470 IDB_a014_wheelSpeedSensorOverTem 1 "NOT_OK" 0 "OK" ;
VAL_ 1470 IDB_a014_wheelSpeedSensorSh_0001 1 "NOT_OK" 0 "OK" ;
VAL_ 1470 IDB_a014_wheelSpeedSensorShortTo 1 "NOT_OK" 0 "OK" ;
VAL_ 1470 IDB_a014_wheelSpeedSensorOpen 1 "NOT_OK" 0 "OK" ;
VAL_ 1470 IDB_a015_wheelSpeedSensorFreq 1 "NOT_OK" 0 "OK" ;
VAL_ 1470 IDB_a015_wheelSpeedSensorPhase 1 "NOT_OK" 0 "OK" ;
VAL_ 1470 IDB_a015_wheelSpeedSensorMisinst 1 "NOT_OK" 0 "OK" ;
VAL_ 1470 IDB_a015_wheelSpeedSensorWrongEx 1 "NOT_OK" 0 "OK" ;
VAL_ 1470 IDB_a015_wheelSpeedSensorSpeedJu 1 "NOT_OK" 0 "OK" ;
VAL_ 1470 IDB_a015_wheelSpeedSensorSp_0001 1 "NOT_OK" 0 "OK" ;
VAL_ 1470 IDB_a015_wheelSpeedSensorAirGap 1 "NOT_OK" 0 "OK" ;
VAL_ 1470 IDB_a015_wheelSpeedSensorBIST 1 "NOT_OK" 0 "OK" ;
VAL_ 1470 IDB_a015_wheelSpeedSensorLeakage 1 "NOT_OK" 0 "OK" ;
VAL_ 1470 IDB_a015_wheelSpeedSensorOverTem 1 "NOT_OK" 0 "OK" ;
VAL_ 1470 IDB_a015_wheelSpeedSensorSh_0001 1 "NOT_OK" 0 "OK" ;
VAL_ 1470 IDB_a015_wheelSpeedSensorShortTo 1 "NOT_OK" 0 "OK" ;
VAL_ 1470 IDB_a015_wheelSpeedSensorOpen 1 "NOT_OK" 0 "OK" ;
VAL_ 1470 IDB_a016_wheelSpeedSensorFreq 1 "NOT_OK" 0 "OK" ;
VAL_ 1470 IDB_a016_wheelSpeedSensorPhase 1 "NOT_OK" 0 "OK" ;
VAL_ 1470 IDB_a016_wheelSpeedSensorMisinst 1 "NOT_OK" 0 "OK" ;
VAL_ 1470 IDB_a016_wheelSpeedSensorWrongEx 1 "NOT_OK" 0 "OK" ;
VAL_ 1470 IDB_a016_wheelSpeedSensorSpeedJu 1 "NOT_OK" 0 "OK" ;
VAL_ 1470 IDB_a016_wheelSpeedSensorSp_0001 1 "NOT_OK" 0 "OK" ;
VAL_ 1470 IDB_a016_wheelSpeedSensorAirGap 1 "NOT_OK" 0 "OK" ;
VAL_ 1470 IDB_a016_wheelSpeedSensorBIST 1 "NOT_OK" 0 "OK" ;
VAL_ 1470 IDB_a016_wheelSpeedSensorLeakage 1 "NOT_OK" 0 "OK" ;
VAL_ 1470 IDB_a016_wheelSpeedSensorOverTem 1 "NOT_OK" 0 "OK" ;
VAL_ 1470 IDB_a016_wheelSpeedSensorSh_0001 1 "NOT_OK" 0 "OK" ;
VAL_ 1470 IDB_a016_wheelSpeedSensorShortTo 1 "NOT_OK" 0 "OK" ;
VAL_ 1470 IDB_a016_wheelSpeedSensorOpen 1 "NOT_OK" 0 "OK" ;
VAL_ 1470 IDB_a017_wheelSpeedSensorFreq 1 "NOT_OK" 0 "OK" ;
VAL_ 1470 IDB_a017_wheelSpeedSensorPhase 1 "NOT_OK" 0 "OK" ;
VAL_ 1470 IDB_a017_wheelSpeedSensorMisinst 1 "NOT_OK" 0 "OK" ;
VAL_ 1470 IDB_a017_wheelSpeedSensorWrongEx 1 "NOT_OK" 0 "OK" ;
VAL_ 1470 IDB_a017_wheelSpeedSensorSpeedJu 1 "NOT_OK" 0 "OK" ;
VAL_ 1470 IDB_a017_wheelSpeedSensorSp_0001 1 "NOT_OK" 0 "OK" ;
VAL_ 1470 IDB_a017_wheelSpeedSensorAirGap 1 "NOT_OK" 0 "OK" ;
VAL_ 1470 IDB_a017_wheelSpeedSensorBIST 1 "NOT_OK" 0 "OK" ;
VAL_ 1470 IDB_a017_wheelSpeedSensorLeakage 1 "NOT_OK" 0 "OK" ;
VAL_ 1470 IDB_a017_wheelSpeedSensorOverTem 1 "NOT_OK" 0 "OK" ;
VAL_ 1470 IDB_a017_wheelSpeedSensorSh_0001 1 "NOT_OK" 0 "OK" ;
VAL_ 1470 IDB_a017_wheelSpeedSensorShortTo 1 "NOT_OK" 0 "OK" ;
VAL_ 1470 IDB_a017_wheelSpeedSensorOpen 1 "NOT_OK" 0 "OK" ;
VAL_ 1470 IDB_a020_canSignalValidity 1 "NOT_OK" 0 "OK" ;
VAL_ 1470 IDB_a020_signalValueCrosscheck 1 "NOT_OK" 0 "OK" ;
VAL_ 1470 IDB_a030_primaryExternalCircuitL 1 "NOT_OK" 0 "OK" ;
VAL_ 1470 IDB_a030_secondaryExternalCircui 1 "NOT_OK" 0 "OK" ;
VAL_ 1470 IDB_a030_primaryChamberInternalL 1 "NOT_OK" 0 "OK" ;
VAL_ 1470 IDB_a030_syncModeInternalLeakage 1 "NOT_OK" 0 "OK" ;
VAL_ 1470 IDB_a030_secondaryChamberInterna 1 "NOT_OK" 0 "OK" ;
VAL_ 1470 IDB_a030_masterCylinderInternalL 1 "NOT_OK" 0 "OK" ;
VAL_ 1470 IDB_a060_validityOnChassisBus 1 "NOT_OK" 0 "OK" ;
VAL_ 1470 IDB_a060_validityOnPartyBus 1 "NOT_OK" 0 "OK" ;
VAL_ 1470 IDB_a061_validityOnChassisBus 1 "NOT_OK" 0 "OK" ;
VAL_ 1470 IDB_a061_validityOnPartyBus 1 "NOT_OK" 0 "OK" ;
VAL_ 1470 IDB_a062_validityOnChassisBus 1 "NOT_OK" 0 "OK" ;
VAL_ 1470 IDB_a062_validityOnPartyBus 1 "NOT_OK" 0 "OK" ;
VAL_ 1470 IDB_a063_validityOnChassisBus 1 "NOT_OK" 0 "OK" ;
VAL_ 1470 IDB_a063_validityOnPartyBus 1 "NOT_OK" 0 "OK" ;
VAL_ 1470 IDB_a064_validityOnChassisBus 1 "NOT_OK" 0 "OK" ;
VAL_ 1470 IDB_a064_validityOnPartyBus 1 "NOT_OK" 0 "OK" ;
VAL_ 1470 IDB_a065_validityOnChassisBus 1 "NOT_OK" 0 "OK" ;
VAL_ 1470 IDB_a065_validityOnPartyBus 1 "NOT_OK" 0 "OK" ;
VAL_ 1470 IDB_a106_qualifierValidity 1 "NOT_OK" 0 "OK" ;
VAL_ 1470 IDB_a106_signalNotAvailable 1 "NOT_OK" 0 "OK" ;
VAL_ 1470 IDB_a107_qualifierValidity 1 "NOT_OK" 0 "OK" ;
VAL_ 1470 IDB_a107_signalNotAvailable 1 "NOT_OK" 0 "OK" ;
VAL_ 1470 IDB_a112_qualifierValidity 1 "NOT_OK" 0 "OK" ;
VAL_ 1470 IDB_a112_signalNotAvailable 1 "NOT_OK" 0 "OK" ;
VAL_ 1470 IDB_a113_qualifierValidity 1 "NOT_OK" 0 "OK" ;
VAL_ 1470 IDB_a113_signalNotAvailable 1 "NOT_OK" 0 "OK" ;
VAL_ 1470 IDB_a114_qualifierValidity 1 "NOT_OK" 0 "OK" ;
VAL_ 1470 IDB_a114_signalNotAvailable 1 "NOT_OK" 0 "OK" ;
VAL_ 1470 IDB_a126_PMebrCmdStateValidity 1 "NOT_OK" 0 "OK" ;
VAL_ 1470 IDB_a126_PMstate2Validity 1 "NOT_OK" 0 "OK" ;
VAL_ 1470 IDB_a126_PMstate2Missing 1 "NOT_OK" 0 "OK" ;
VAL_ 1470 IDB_a126_DIchassisControlValidit 1 "NOT_OK" 0 "OK" ;
VAL_ 1470 IDB_a126_DIchassisControlMissing 1 "NOT_OK" 0 "OK" ;
VAL_ 1470 IDB_a126_DIrequestActiveValidity 1 "NOT_OK" 0 "OK" ;
VAL_ 1470 IDB_a129_validityOnChassisBus 1 "NOT_OK" 0 "OK" ;
VAL_ 1470 IDB_a129_validityOnPartyBus 1 "NOT_OK" 0 "OK" ;
VAL_ 1470 IDB_a130_PMbrakePedalCmdQFValidi 1 "NOT_OK" 0 "OK" ;
VAL_ 1470 IDB_a130_PMstate2Validity 1 "NOT_OK" 0 "OK" ;
VAL_ 1470 IDB_a130_PMstate2Missing 1 "NOT_OK" 0 "OK" ;
VAL_ 1470 IDB_a130_DIbrakeCommandValidity 1 "NOT_OK" 0 "OK" ;
VAL_ 1470 IDB_a130_DIbrakeCommandMissing 1 "NOT_OK" 0 "OK" ;
VAL_ 1470 IDB_a130_DIbrakeTorqueCommandFul 1 "NOT_OK" 0 "OK" ;
VAL_ 1470 IDB_a130_DIbrakeTorqueComma_0001 1 "NOT_OK" 0 "OK" ;
VAL_ 1470 IDB_a132_validityOnChassisBus 1 "NOT_OK" 0 "OK" ;
VAL_ 1470 IDB_a132_validityOnPartyBus 1 "NOT_OK" 0 "OK" ;
VAL_ 983 IDB_matrixIndex 2 "AlertMatrix2" 1 "AlertMatrix1" 0 "AlertMatrix0" ;
VAL_ 1429 OCS1P_alertID 155 "a155_rbExit2Exited2" 154 "a154_rbExit2Exited1" 153 "a153_rbExit1Exited" 152 "a152_rbExit1Triggered" 151 "a151_rbEntryExited" 150 "a150_rbEntryTriggered" 148 "a148_classificationMismatch" 145 "a145_rebaselineTriggered" 144 "a144_mismatchCarRegion" 143 "a143_mismatchPassAirbag" 142 "a142_tempHumidityInvalid" 141 "a141_humidityInvalidCalib" 140 "a140_tempInvalidCalib" 139 "a139_seatbackSelfDutyHigh" 138 "a138_seatbackSelfDutyLow" 137 "a137_cushionSelfDutyHigh" 136 "a136_cushionSelfDutyLow" 135 "a135_tempNoCalib" 134 "a134_uninitializedCalib" 133 "a133_sandwichBadCalib" 132 "a132_seatbackSelfNoCalib" 131 "a131_cushionSelfNoCalib" 130 "a130_sandwichNoCalib" 129 "a129_seatbackSelfShort" 128 "a128_seatbackSelfLow" 127 "a127_seatbackSelfOpen" 126 "a126_cushionSelfShort" 125 "a125_cushionSelfLow" 124 "a124_cushionSelfOpen" 123 "a123_sandwichShort" 122 "a122_sandwichLow" 121 "a121_sandwichOpen" 15 "a015_NVMMAlert" 0 "ALERT_DO_NOT_USE_ZERO" ;
VAL_ 1429 OCS1P_alertState 1 "SET" 0 "CLEARED" ;
VAL_ 767 OCS1P_matrixIndex 2 "AlertMatrix2" 0 "AlertMatrix0" ;
VAL_ 766 OCS1P_infoIndex 20 "Mux20" 19 "Mux19" 18 "Mux18" 17 "Mux17" 14 "Mux14" 13 "Mux13" 11 "Mux11" 10 "Mux10" ;
VAL_ 766 OCS1P_infoBuildType 4 "INFO_MFG_BUILD" 3 "INFO_TRACEABLE_CI_BUILD" 2 "INFO_LOCAL_BUILD" 1 "INFO_PLATFORM_BUILD" 0 "INFO_UNKNOWN_BUILD" ;
